VERSION ""

NS_ :

BS_:

BU_: WPC2 PSB SHVU_RR vHS_B2 FCS EMCU SLB GW_APSU GW_DLBCU ARS RCM CGW_CCU vDummy_HS_B GW_RLPSU ATS RLHV SGU PFSU GW_RRPSU ALBCU DSAU SWRC SHVU_FR RCS GW_DPSU BLTN_CAM SCM OHCL RWPC RRHV WPC HOD ASAU

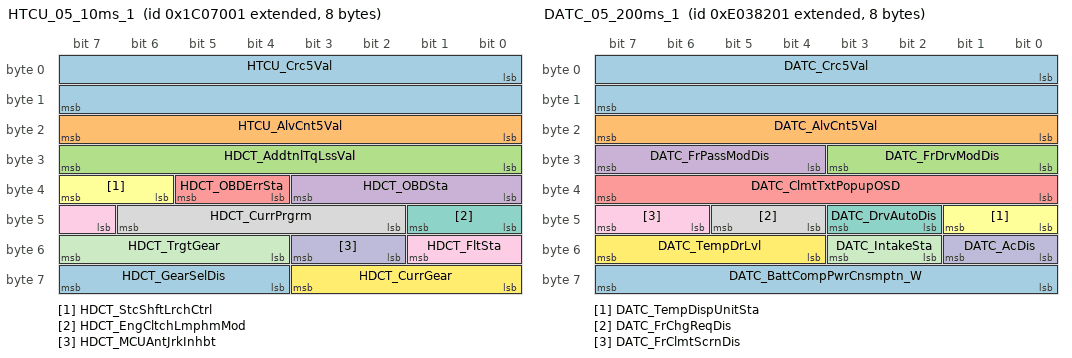
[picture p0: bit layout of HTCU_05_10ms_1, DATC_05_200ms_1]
BO_ 2176872449 HTCU_05_10ms_1: 8 CGW_CCU
 SG_ HTCU_Crc5Val : 0|16@1+ (1,0) [0|0] ""  Vector__XXX
 SG_ HTCU_AlvCnt5Val : 16|8@1+ (1,0) [0|0] ""  Vector__XXX
 SG_ HDCT_AddtnlTqLssVal : 24|8@1+ (0.390625,0) [0|0] "%"  Vector__XXX
 SG_ HDCT_OBDSta : 32|4@1+ (1,0) [0|0] ""  Vector__XXX
 SG_ HDCT_OBDErrSta : 36|2@1+ (1,0) [0|0] ""  Vector__XXX
 SG_ HDCT_StcShftLrchCtrl : 38|2@1+ (1,0) [0|0] ""  Vector__XXX
 SG_ HDCT_EngCltchLmphmMod : 40|2@1+ (1,0) [0|0] ""  Vector__XXX
 SG_ HDCT_CurrPrgrm : 42|5@1+ (1,0) [0|0] ""  Vector__XXX
 SG_ HDCT_FltSta : 47|3@1+ (1,0) [0|0] ""  Vector__XXX
 SG_ HDCT_MCUAntJrkInhbt : 50|2@1+ (1,0) [0|0] ""  Vector__XXX
 SG_ HDCT_TrgtGear : 52|4@1+ (1,0) [0|0] ""  Vector__XXX
 SG_ HDCT_CurrGear : 56|4@1+ (1,0) [0|0] ""  Vector__XXX
 SG_ HDCT_GearSelDis : 60|4@1+ (1,0) [0|0] ""  SWRC,BLTN_CAM

BO_ 2176872452 HTCU_05_10ms_4: 8 CGW_CCU

BO_ 694 ASAU_02_00ms: 8 ASAU
 SG_ ASAU_NotFootMsgOperStaWarn : 0|2@1+ (1,0) [0|0] ""  Vector__XXX

BO_ 2382594561 DATC_05_200ms_1: 8 CGW_CCU
 SG_ DATC_Crc5Val : 0|16@1+ (1,0) [0|0] ""  Vector__XXX
 SG_ DATC_AlvCnt5Val : 16|8@1+ (1,0) [0|0] ""  Vector__XXX
 SG_ DATC_FrDrvModDis : 24|4@1+ (1,0) [0|0] ""  ATS
 SG_ DATC_FrPassModDis : 28|4@1+ (1,0) [0|0] ""  ATS
 SG_ DATC_ClmtTxtPopupOSD : 32|8@1+ (1,0) [0|0] ""  ATS
 SG_ DATC_TempDispUnitSta : 40|2@1+ (1,0) [0|0] ""  ATS
 SG_ DATC_DrvAutoDis : 42|2@1+ (1,0) [0|0] ""  ATS
 SG_ DATC_FrChgReqDis : 44|2@1+ (1,0) [0|0] ""  Vector__XXX
 SG_ DATC_FrClmtScrnDis : 46|2@1+ (1,0) [0|0] ""  ATS
 SG_ DATC_AcDis : 48|2@1+ (1,0) [0|0] ""  ATS
 SG_ DATC_IntakeSta : 50|2@1+ (1,0) [0|0] ""  Vector__XXX
 SG_ DATC_TempDrLvl : 52|4@1+ (1,0) [0|0] ""  Vector__XXX
 SG_ DATC_BattCompPwrCnsmptn_W : 56|8@1+ (40,0) [0|0] "W"  Vector__XXX

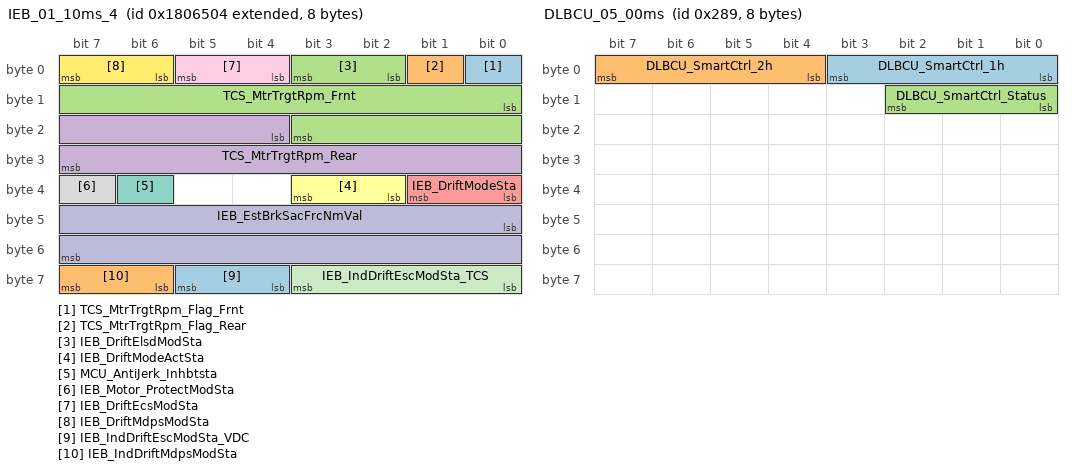
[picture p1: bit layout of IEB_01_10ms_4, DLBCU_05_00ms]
BO_ 2172675332 IEB_01_10ms_4: 8 CGW_CCU
 SG_ TCS_MtrTrgtRpm_Flag_Frnt : 0|1@1+ (1,0) [0|0] ""  Vector__XXX
 SG_ TCS_MtrTrgtRpm_Flag_Rear : 1|1@1+ (1,0) [0|0] ""  Vector__XXX
 SG_ IEB_DriftElsdModSta : 2|2@1+ (1,0) [0|0] ""  Vector__XXX
 SG_ TCS_MtrTrgtRpm_Rear : 20|12@1+ (8,0) [0|0] "rpm"  Vector__XXX
 SG_ IEB_DriftModeSta : 32|2@1+ (1,0) [0|0] ""  Vector__XXX
 SG_ IEB_DriftModeActSta : 34|2@1+ (1,0) [0|0] ""  Vector__XXX
 SG_ MCU_AntiJerk_Inhbtsta : 38|1@1+ (1,0) [0|0] ""  Vector__XXX
 SG_ IEB_Motor_ProtectModSta : 39|1@1+ (1,0) [0|0] ""  Vector__XXX
 SG_ IEB_DriftEcsModSta : 4|2@1+ (1,0) [0|0] ""  Vector__XXX
 SG_ IEB_EstBrkSacFrcNmVal : 40|16@1+ (1,0) [0|0] ""  Vector__XXX
 SG_ IEB_IndDriftEscModSta_TCS : 56|4@1+ (1,0) [0|0] ""  Vector__XXX
 SG_ IEB_DriftMdpsModSta : 6|2@1+ (1,0) [0|0] ""  Vector__XXX
 SG_ IEB_IndDriftEscModSta_VDC : 60|2@1+ (1,0) [0|0] ""  Vector__XXX
 SG_ IEB_IndDriftMdpsModSta : 62|2@1+ (1,0) [0|0] ""  Vector__XXX
 SG_ TCS_MtrTrgtRpm_Frnt : 8|12@1+ (8,0) [0|0] "rpm"  Vector__XXX

BO_ 649 DLBCU_05_00ms: 8 GW_DLBCU
 SG_ DLBCU_SmartCtrl_1h : 0|4@1+ (1,0) [0|0] ""  CGW_CCU
 SG_ DLBCU_SmartCtrl_2h : 4|4@1+ (1,0) [0|0] ""  CGW_CCU
 SG_ DLBCU_SmartCtrl_Status : 8|3@1+ (1,0) [0|0] ""  CGW_CCU

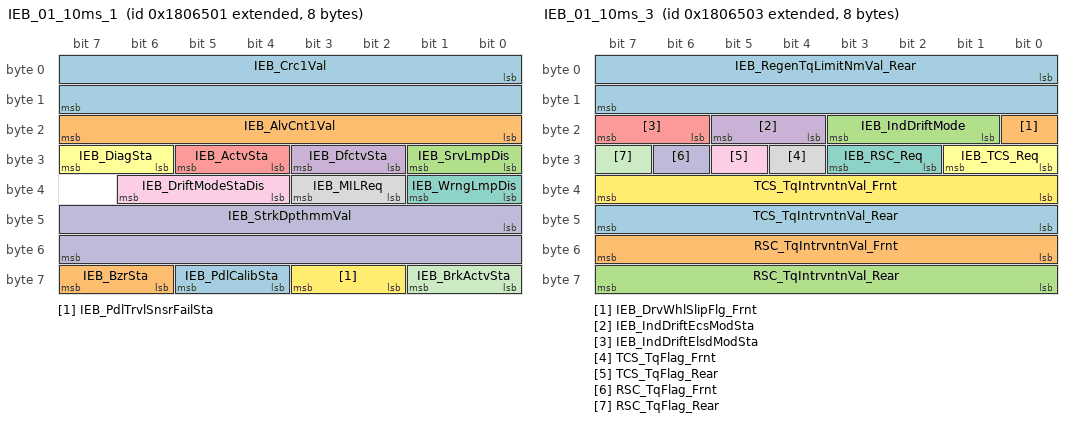
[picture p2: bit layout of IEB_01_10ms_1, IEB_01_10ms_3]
BO_ 2172675329 IEB_01_10ms_1: 8 CGW_CCU
 SG_ IEB_Crc1Val : 0|16@1+ (1,0) [0|0] ""  Vector__XXX
 SG_ IEB_AlvCnt1Val : 16|8@1+ (1,0) [0|0] ""  Vector__XXX
 SG_ IEB_SrvLmpDis : 24|2@1+ (1,0) [0|0] ""  Vector__XXX
 SG_ IEB_DfctvSta : 26|2@1+ (1,0) [0|0] ""  Vector__XXX
 SG_ IEB_ActvSta : 28|2@1+ (1,0) [0|0] ""  Vector__XXX
 SG_ IEB_DiagSta : 30|2@1+ (1,0) [0|0] ""  Vector__XXX
 SG_ IEB_WrngLmpDis : 32|2@1+ (1,0) [0|0] ""  Vector__XXX
 SG_ IEB_MILReq : 34|2@1+ (1,0) [0|0] ""  Vector__XXX
 SG_ IEB_DriftModeStaDis : 36|3@1+ (1,0) [0|0] ""  Vector__XXX
 SG_ IEB_StrkDpthmmVal : 40|16@1- (0.1,0) [0|0] "mm"  Vector__XXX
 SG_ IEB_BrkActvSta : 56|2@1+ (1,0) [0|0] ""  BLTN_CAM
 SG_ IEB_PdlTrvlSnsrFailSta : 58|2@1+ (1,0) [0|0] ""  Vector__XXX
 SG_ IEB_PdlCalibSta : 60|2@1+ (1,0) [0|0] ""  Vector__XXX
 SG_ IEB_BzrSta : 62|2@1+ (1,0) [0|0] ""  Vector__XXX

BO_ 2172675331 IEB_01_10ms_3: 8 CGW_CCU
 SG_ IEB_RegenTqLimitNmVal_Rear : 0|16@1+ (1,0) [0|0] "Nm"  Vector__XXX
 SG_ IEB_DrvWhlSlipFlg_Frnt : 16|1@1+ (1,0) [0|0] ""  Vector__XXX
 SG_ IEB_IndDriftMode : 17|3@1+ (1,0) [0|0] ""  Vector__XXX
 SG_ IEB_IndDriftEcsModSta : 20|2@1+ (1,0) [0|0] ""  Vector__XXX
 SG_ IEB_IndDriftElsdModSta : 22|2@1+ (1,0) [0|0] ""  Vector__XXX
 SG_ IEB_TCS_Req : 24|2@1+ (1,0) [0|0] ""  Vector__XXX
 SG_ IEB_RSC_Req : 26|2@1+ (1,0) [0|0] ""  Vector__XXX
 SG_ TCS_TqFlag_Frnt : 28|1@1+ (1,0) [0|0] ""  Vector__XXX
 SG_ TCS_TqFlag_Rear : 29|1@1+ (1,0) [0|0] ""  Vector__XXX
 SG_ RSC_TqFlag_Frnt : 30|1@1+ (1,0) [0|0] ""  Vector__XXX
 SG_ RSC_TqFlag_Rear : 31|1@1+ (1,0) [0|0] ""  Vector__XXX
 SG_ TCS_TqIntrvntnVal_Frnt : 32|8@1+ (0.390625,0) [0|0] "%"  Vector__XXX
 SG_ TCS_TqIntrvntnVal_Rear : 40|8@1+ (0.390625,0) [0|0] "%"  Vector__XXX
 SG_ RSC_TqIntrvntnVal_Frnt : 48|8@1+ (0.390625,0) [0|0] "%"  Vector__XXX
 SG_ RSC_TqIntrvntnVal_Rear : 56|8@1+ (0.390625,0) [0|0] "%"  Vector__XXX

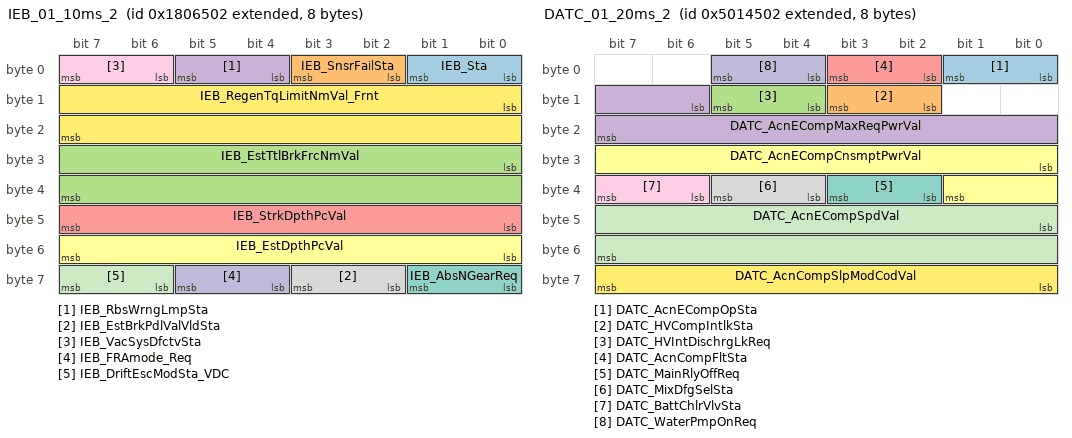
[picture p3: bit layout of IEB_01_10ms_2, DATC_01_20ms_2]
BO_ 2172675330 IEB_01_10ms_2: 8 CGW_CCU
 SG_ IEB_Sta : 0|2@1+ (1,0) [0|0] ""  Vector__XXX
 SG_ IEB_SnsrFailSta : 2|2@1+ (1,0) [0|0] ""  Vector__XXX
 SG_ IEB_EstTtlBrkFrcNmVal : 24|16@1+ (1,0) [0|0] "Nm"  Vector__XXX
 SG_ IEB_RbsWrngLmpSta : 4|2@1+ (1,0) [0|0] ""  Vector__XXX
 SG_ IEB_StrkDpthPcVal : 40|8@1+ (0.39215,0) [0|0] "%"  Vector__XXX
 SG_ IEB_EstDpthPcVal : 48|8@1+ (0.390625,0) [0|0] "%"  Vector__XXX
 SG_ IEB_AbsNGearReq : 56|2@1+ (1,0) [0|0] ""  Vector__XXX
 SG_ IEB_EstBrkPdlValVldSta : 58|2@1+ (1,0) [0|0] ""  Vector__XXX
 SG_ IEB_VacSysDfctvSta : 6|2@1+ (1,0) [0|0] ""  Vector__XXX
 SG_ IEB_FRAmode_Req : 60|2@1+ (1,0) [0|0] ""  Vector__XXX
 SG_ IEB_DriftEscModSta_VDC : 62|2@1+ (1,0) [0|0] ""  Vector__XXX
 SG_ IEB_RegenTqLimitNmVal_Frnt : 8|16@1+ (1,0) [0|0] "Nm"  Vector__XXX

BO_ 2231452930 DATC_01_20ms_2: 8 CGW_CCU
 SG_ DATC_AcnECompOpSta : 0|2@1+ (1,0) [0|0] "flag"  Vector__XXX
 SG_ DATC_HVCompIntlkSta : 10|2@1+ (1,0) [0|0] "flag"  Vector__XXX
 SG_ DATC_HVIntDischrgLkReq : 12|2@1+ (1,0) [0|0] "flag"  Vector__XXX
 SG_ DATC_AcnECompMaxReqPwrVal : 14|10@1+ (20,0) [0|0] "W"  Vector__XXX
 SG_ DATC_AcnCompFltSta : 2|2@1+ (1,0) [0|0] "flag"  Vector__XXX
 SG_ DATC_AcnECompCnsmptPwrVal : 24|10@1+ (20,0) [0|0] "W"  Vector__XXX
 SG_ DATC_MainRlyOffReq : 34|2@1+ (1,0) [0|0] "flag"  Vector__XXX
 SG_ DATC_MixDfgSelSta : 36|2@1+ (1,0) [0|0] "flag"  Vector__XXX
 SG_ DATC_BattChlrVlvSta : 38|2@1+ (1,0) [0|0] ""  Vector__XXX
 SG_ DATC_WaterPmpOnReq : 4|2@1+ (1,0) [0|0] "flag"  Vector__XXX
 SG_ DATC_AcnECompSpdVal : 40|16@1+ (1,0) [0|0] "rpm"  Vector__XXX
 SG_ DATC_AcnCompSlpModCodVal : 56|8@1+ (1,0) [0|0] ""  Vector__XXX

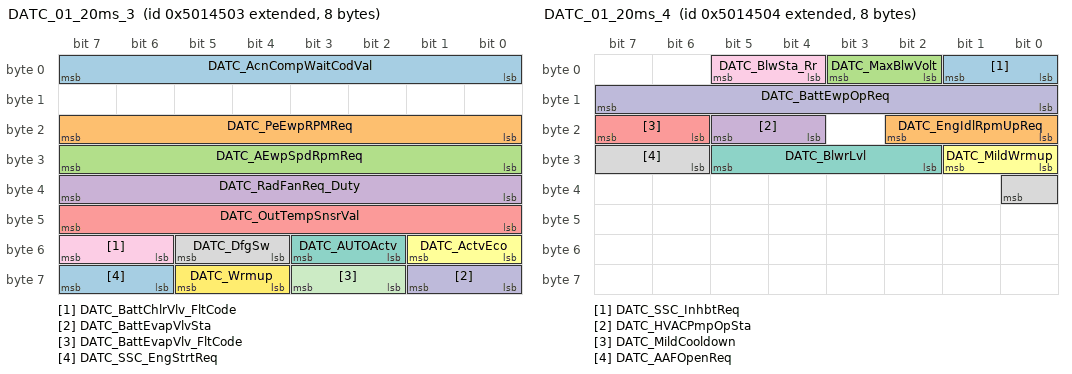
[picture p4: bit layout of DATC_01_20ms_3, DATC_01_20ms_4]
BO_ 2231452931 DATC_01_20ms_3: 8 CGW_CCU
 SG_ DATC_AcnCompWaitCodVal : 0|8@1+ (1,0) [0|0] ""  Vector__XXX
 SG_ DATC_PeEwpRPMReq : 16|8@1+ (30,0) [0|0] ""  Vector__XXX
 SG_ DATC_AEwpSpdRpmReq : 24|8@1+ (20,0) [0|0] "rpm"  Vector__XXX
 SG_ DATC_RadFanReq_Duty : 32|8@1+ (1,0) [0|0] "%"  Vector__XXX
 SG_ DATC_OutTempSnsrVal : 40|8@1+ (0.5,-40) [0|0] "¡É"  RCM
 SG_ DATC_ActvEco : 48|2@1+ (1,0) [0|0] ""  Vector__XXX
 SG_ DATC_AUTOActv : 50|2@1+ (1,0) [0|0] ""  Vector__XXX
 SG_ DATC_DfgSw : 52|2@1+ (1,0) [0|0] ""  Vector__XXX
 SG_ DATC_BattChlrVlv_FltCode : 54|2@1+ (1,0) [0|0] ""  Vector__XXX
 SG_ DATC_BattEvapVlvSta : 56|2@1+ (1,0) [0|0] ""  Vector__XXX
 SG_ DATC_BattEvapVlv_FltCode : 58|2@1+ (1,0) [0|0] ""  Vector__XXX
 SG_ DATC_Wrmup : 60|2@1+ (1,0) [0|0] ""  Vector__XXX
 SG_ DATC_SSC_EngStrtReq : 62|2@1+ (1,0) [0|0] ""  Vector__XXX

BO_ 2231452929 DATC_01_20ms_1: 8 CGW_CCU
 SG_ DATC_Crc1Val : 0|16@1+ (1,0) [0|0] ""  Vector__XXX
 SG_ DATC_AlvCnt1Val : 16|8@1+ (1,0) [0|0] ""  Vector__XXX
 SG_ DATC_PtcRlySta : 24|3@1+ (1,0) [0|0] ""  Vector__XXX
 SG_ DATC_ManufacturerTyp : 27|3@1+ (1,0) [0|0] ""  Vector__XXX
 SG_ DATC_DatcPwmSts : 30|2@1+ (1,0) [0|0] ""  Vector__XXX
 SG_ DATC_AcnCompTyp : 32|3@1+ (1,0) [0|0] "flag"  Vector__XXX
 SG_ DATC_EewpRpmLvlReq : 35|3@1+ (1,0) [0|0] ""  Vector__XXX
 SG_ DATC_Cooldown : 38|2@1+ (1,0) [0|0] ""  Vector__XXX
 SG_ DATC_AcnReq : 40|2@1+ (1,0) [0|0] ""  Vector__XXX
 SG_ DATC_BlwSta : 42|2@1+ (1,0) [0|0] ""  Vector__XXX
 SG_ DATC_BlwMaxSta : 44|2@1+ (1,0) [0|0] ""  Vector__XXX
 SG_ DATC_EngStrtReq : 46|2@1+ (1,0) [0|0] ""  Vector__XXX
 SG_ DATC_IsgInhbtReq : 48|2@1+ (1,0) [0|0] ""  Vector__XXX
 SG_ DATC_AcnCompOnReq : 50|2@1+ (1,0) [0|0] "flag"  Vector__XXX
 SG_ DATC_SrvLmpReq : 52|2@1+ (1,0) [0|0] ""  Vector__XXX
 SG_ DATC_EcvFltSta : 54|2@1+ (1,0) [0|0] ""  Vector__XXX
 SG_ DATC_CalcAcnCompTqVal : 56|8@1+ (0.2,0) [0|0] "Nm"  Vector__XXX

BO_ 2231452932 DATC_01_20ms_4: 8 CGW_CCU
 SG_ DATC_SSC_InhbtReq : 0|2@1+ (1,0) [0|0] ""  Vector__XXX
 SG_ DATC_EngIdlRpmUpReq : 16|3@1+ (1,0) [0|0] ""  Vector__XXX
 SG_ DATC_MaxBlwVolt : 2|2@1+ (1,0) [0|0] ""  Vector__XXX
 SG_ DATC_HVACPmpOpSta : 20|2@1+ (1,0) [0|0] ""  Vector__XXX
 SG_ DATC_MildCooldown : 22|2@1+ (1,0) [0|0] ""  Vector__XXX
 SG_ DATC_MildWrmup : 24|2@1+ (1,0) [0|0] ""  Vector__XXX
 SG_ DATC_BlwrLvl : 26|4@1+ (1,0) [0|0] ""  Vector__XXX
 SG_ DATC_AAFOpenReq : 30|3@1+ (1,0) [0|0] ""  Vector__XXX
 SG_ DATC_BlwSta_Rr : 4|2@1+ (1,0) [0|0] ""  Vector__XXX
 SG_ DATC_BattEwpOpReq : 8|8@1+ (30,0) [0|0] "rpm"  Vector__XXX

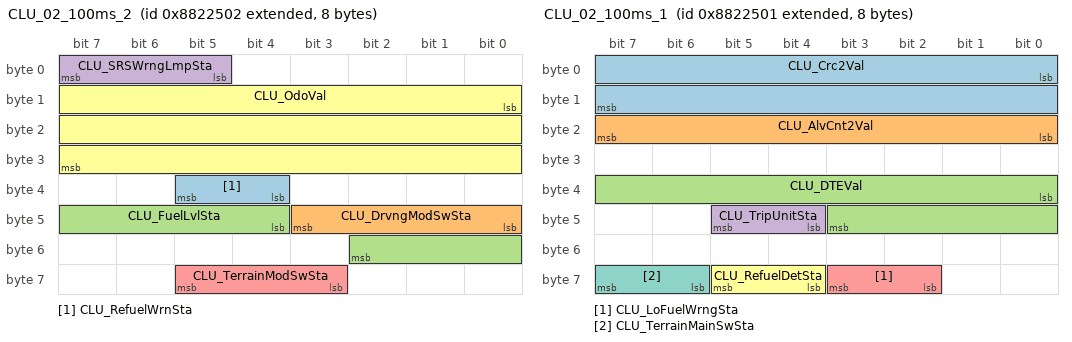
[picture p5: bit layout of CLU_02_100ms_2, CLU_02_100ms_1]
BO_ 2290230530 CLU_02_100ms_2: 8 CGW_CCU
 SG_ CLU_RefuelWrnSta : 36|2@1+ (1,0) [0|0] ""  Vector__XXX
 SG_ CLU_DrvngModSwSta : 40|4@1+ (1,0) [0|0] ""  ALBCU,GW_DLBCU,SWRC
 SG_ CLU_FuelLvlSta : 44|7@1+ (1,0) [0|0] "%"  Vector__XXX
 SG_ CLU_SRSWrngLmpSta : 5|3@1+ (1,0) [0|0] ""  Vector__XXX
 SG_ CLU_TerrainModSwSta : 59|3@1+ (1,0) [0|0] ""  SWRC
 SG_ CLU_OdoVal : 8|24@1+ (0.1,0) [0|0] "km"  Vector__XXX

BO_ 2290230529 CLU_02_100ms_1: 8 CGW_CCU
 SG_ CLU_Crc2Val : 0|16@1+ (1,0) [0|0] ""  Vector__XXX
 SG_ CLU_AlvCnt2Val : 16|8@1+ (1,0) [0|0] ""  Vector__XXX
 SG_ CLU_DTEVal : 32|12@1+ (1,0) [0|0] ""  Vector__XXX
 SG_ CLU_TripUnitSta : 44|2@1+ (1,0) [0|0] ""  Vector__XXX
 SG_ CLU_LoFuelWrngSta : 58|2@1+ (1,0) [0|0] ""  Vector__XXX
 SG_ CLU_RefuelDetSta : 60|2@1+ (1,0) [0|0] ""  Vector__XXX
 SG_ CLU_TerrainMainSwSta : 62|2@1+ (1,0) [0|0] ""  FCS

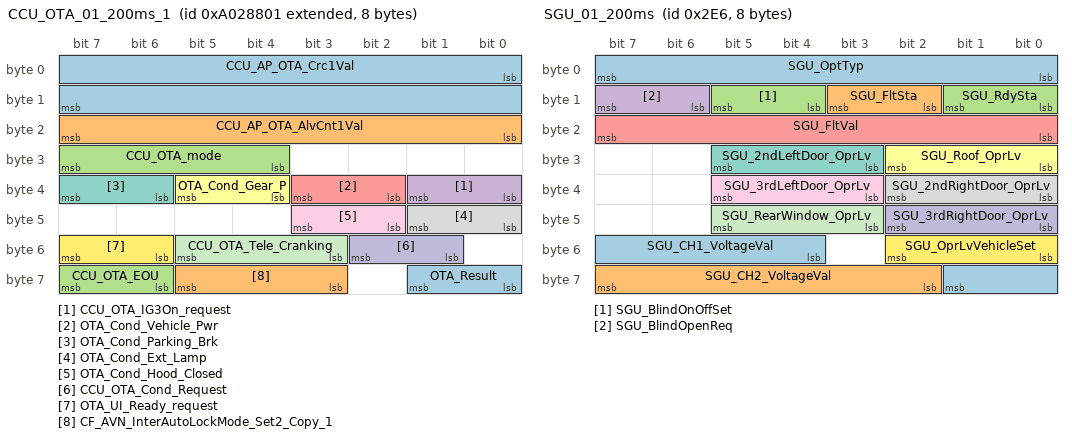
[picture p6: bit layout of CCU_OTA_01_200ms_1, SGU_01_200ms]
BO_ 2315421697 CCU_OTA_01_200ms_1: 8 CGW_CCU
 SG_ CCU_AP_OTA_Crc1Val : 0|16@1+ (1,0) [0|0] ""  vDummy_HS_B
 SG_ CCU_AP_OTA_AlvCnt1Val : 16|8@1+ (1,0) [0|0] ""  vDummy_HS_B
 SG_ CCU_OTA_mode : 28|4@1+ (1,0) [0|0] ""  Vector__XXX
 SG_ CCU_OTA_IG3On_request : 32|2@1+ (1,0) [0|0] ""  Vector__XXX
 SG_ OTA_Cond_Vehicle_Pwr : 34|2@1+ (1,0) [0|0] "flag"  Vector__XXX
 SG_ OTA_Cond_Gear_P : 36|2@1+ (1,0) [0|0] "flag"  Vector__XXX
 SG_ OTA_Cond_Parking_Brk : 38|2@1+ (1,0) [0|0] "flag"  Vector__XXX
 SG_ OTA_Cond_Ext_Lamp : 40|2@1+ (1,0) [0|0] "flag"  Vector__XXX
 SG_ OTA_Cond_Hood_Closed : 42|2@1+ (1,0) [0|0] "flag"  Vector__XXX
 SG_ CCU_OTA_Cond_Request : 49|2@1+ (1,0) [0|0] ""  Vector__XXX
 SG_ CCU_OTA_Tele_Cranking : 51|3@1+ (1,0) [0|0] ""  Vector__XXX
 SG_ OTA_UI_Ready_request : 54|2@1+ (1,0) [0|0] ""  Vector__XXX
 SG_ OTA_Result : 56|2@1+ (1,0) [0|0] "flag"  Vector__XXX
 SG_ CF_AVN_InterAutoLockMode_Set2_Copy_1 : 59|3@1+ (1,0) [0|0] ""  Vector__XXX
 SG_ CCU_OTA_EOU : 62|2@1+ (1,0) [0|0] ""  Vector__XXX

BO_ 2470763009 CLU_09_00ms_1: 8 CGW_CCU
 SG_ CLU_Crc9Val : 0|16@1+ (1,0) [0|0] ""  Vector__XXX
 SG_ CLU_AlvCnt9Val : 16|8@1+ (1,0) [0|0] ""  Vector__XXX
 SG_ USM_MdLmpClrSetReq : 24|4@1+ (1,0) [0|0] ""  Vector__XXX
 SG_ USM_RrWiperRevSetReq : 28|2@1+ (1,0) [0|0] ""  Vector__XXX
 SG_ USM_RrStRemindSetReq : 30|2@1+ (1,0) [0|0] ""  Vector__XXX
 SG_ USM_RrWpcSetReq : 32|2@1+ (1,0) [0|0] ""  Vector__XXX
 SG_ USM_WpcSetReq : 34|2@1+ (1,0) [0|0] ""  WPC,WPC2
 SG_ USM_SeqLmpSetReq : 36|2@1+ (1,0) [0|0] ""  Vector__XXX
 SG_ USM_UnlckWlcmSetReq : 38|2@1+ (1,0) [0|0] ""  Vector__XXX
 SG_ USM_SmrtWlcmSetReq : 40|2@1+ (1,0) [0|0] ""  Vector__XXX
 SG_ USM_UipSetReq : 42|2@1+ (1,0) [0|0] ""  Vector__XXX
 SG_ USM_DigitalKeyEnblSetReq : 44|2@1+ (1,0) [0|0] ""  Vector__XXX
 SG_ USM_OwnerPhnRegSetReq : 46|2@1+ (1,0) [0|0] ""  Vector__XXX
 SG_ USM_NFCCard1RegSetReq : 48|2@1+ (1,0) [0|0] ""  Vector__XXX
 SG_ USM_NFCCard2RegSetReq : 50|2@1+ (1,0) [0|0] ""  Vector__XXX
 SG_ USM_ProcStpReq : 52|1@1+ (1,0) [0|0] ""  Vector__XXX
 SG_ USM_PwrAutoOffTimeSetReq : 54|3@1+ (1,0) [0|0] ""  Vector__XXX
 SG_ USM_RrStRemindSetReq_RestMode : 57|3@1+ (1,0) [0|0] ""  Vector__XXX
 SG_ USM_1stRrStRemindSetReq : 60|2@1+ (1,0) [0|0] ""  Vector__XXX
 SG_ USM_Wpc2SetReq : 62|2@1+ (1,0) [0|0] ""  WPC2

BO_ 742 SGU_01_200ms: 8 SGU
 SG_ SGU_OptTyp : 0|8@1+ (1,0) [0|0] ""  Vector__XXX
 SG_ SGU_FltSta : 10|2@1+ (1,0) [0|0] ""  Vector__XXX
 SG_ SGU_BlindOnOffSet : 12|2@1+ (1,0) [0|0] ""  CGW_CCU
 SG_ SGU_BlindOpenReq : 14|2@1+ (1,0) [0|0] ""  RCM
 SG_ SGU_FltVal : 16|8@1+ (1,0) [0|0] ""  Vector__XXX
 SG_ SGU_Roof_OprLv : 24|3@1+ (1,0) [0|0] ""  CGW_CCU
 SG_ SGU_2ndLeftDoor_OprLv : 27|3@1+ (1,0) [0|0] ""  CGW_CCU
 SG_ SGU_2ndRightDoor_OprLv : 32|3@1+ (1,0) [0|0] ""  CGW_CCU
 SG_ SGU_3rdLeftDoor_OprLv : 35|3@1+ (1,0) [0|0] ""  CGW_CCU
 SG_ SGU_3rdRightDoor_OprLv : 40|3@1+ (1,0) [0|0] ""  CGW_CCU
 SG_ SGU_RearWindow_OprLv : 43|3@1+ (1,0) [0|0] ""  CGW_CCU
 SG_ SGU_OprLvVehicleSet : 48|3@1+ (1,0) [0|0] ""  CGW_CCU
 SG_ SGU_CH1_VoltageVal : 52|6@1+ (0.1,0) [0|0] "V"  Vector__XXX
 SG_ SGU_CH2_VoltageVal : 58|6@1+ (0.1,0) [0|0] "V"  Vector__XXX
 SG_ SGU_RdySta : 8|2@1+ (1,0) [0|0] ""  Vector__XXX

BO_ 763 SBCM_DRV_03_200ms: 8 CGW_CCU
 SG_ SBCM_DRV_Crc3Val : 0|8@1+ (1,0) [0|0] ""  Vector__XXX
 SG_ CDM_TypeOption : 10|2@1+ (1,0) [0|0] ""  Vector__XXX
 SG_ SBCM_DRV_AlvCnt3Val : 12|4@1+ (1,0) [0|0] ""  Vector__XXX
 SG_ CDM_ImmeChgSw_SBCM : 16|2@1+ (1,0) [0|0] ""  Vector__XXX
 SG_ CDM_ChgDrSwFrt_SBCM : 18|2@1+ (1,0) [0|0] ""  Vector__XXX
 SG_ CDM_OpnClsState_SBCM : 20|2@1+ (1,0) [0|0] ""  Vector__XXX
 SG_ CDM_WarnMsg_SBCM : 22|2@1+ (1,0) [0|0] ""  Vector__XXX
 SG_ CDM_AutoWashModeSta : 24|3@1+ (1,0) [0|0] ""  Vector__XXX
 SG_ CDM_CmdStatus_SBCM : 28|4@1+ (1,0) [0|0] ""  Vector__XXX
 SG_ CDM_OutsideOpnSwSta : 32|2@1+ (1,0) [0|0] ""  Vector__XXX
 SG_ PwrDRBuzzerOut_DRV : 34|2@1+ (1,0) [0|0] ""  Vector__XXX
 SG_ Warn_HoodSwSta_SBCM : 36|2@1+ (1,0) [0|0] ""  BLTN_CAM
 SG_ Hood_TypeOption : 38|2@1+ (1,0) [0|0] ""  BLTN_CAM
 SG_ SBCM_FrunkSta : 40|2@1+ (1,0) [0|0] ""  Vector__XXX
 SG_ Warn_HoodSwFullSta_SBCM : 42|2@1+ (1,0) [0|0] ""  Vector__XXX
 SG_ FrunkWarning_SBCM : 44|2@1+ (1,0) [0|0] ""  Vector__XXX
 SG_ SBCM_Longkey_DRVDrAtClsSwSta : 46|2@1+ (1,0) [0|0] ""  Vector__XXX
 SG_ PwrDRClosingDRVDrSta : 48|3@1+ (1,0) [0|0] ""  Vector__XXX
 SG_ Drv_DrLkRetryFail_SBCM : 51|2@1+ (1,0) [0|0] ""  Vector__XXX
 SG_ CDM_GbtImmeChgSw_SBCM : 54|2@1+ (1,0) [0|0] ""  Vector__XXX
 SG_ CDM_GbtOpnClsState_SBCM : 56|2@1+ (1,0) [0|0] ""  Vector__XXX
 SG_ CDM_GbtWarnMsg_SBCM : 58|2@1+ (1,0) [0|0] ""  Vector__XXX
 SG_ DoorLock_DrvLkOutSta_SBCM : 62|2@1+ (1,0) [0|0] ""  Vector__XXX
 SG_ CDM_InsideOpnSwSta : 8|2@1+ (1,0) [0|0] ""  Vector__XXX

BO_ 761 SBCM_AST_03_200ms: 8 CGW_CCU
 SG_ SBCM_AST_Crc3Val : 0|8@1+ (1,0) [0|0] ""  Vector__XXX
 SG_ CDM_TypeOption_AST : 10|2@1+ (1,0) [0|0] ""  Vector__XXX
 SG_ SBCM_AST_AlvCnt3Val : 12|4@1+ (1,0) [0|0] ""  Vector__XXX
 SG_ CDM_ImmeChgSw_AST : 16|2@1+ (1,0) [0|0] ""  Vector__XXX
 SG_ CDM_ChgDrSwFrt_AST : 18|2@1+ (1,0) [0|0] ""  Vector__XXX
 SG_ CDM_OpnClsState_AST : 20|2@1+ (1,0) [0|0] ""  Vector__XXX
 SG_ CDM_WarnMsg_AST : 22|2@1+ (1,0) [0|0] ""  Vector__XXX
 SG_ Mirror_RH_FoldingSta : 24|2@1+ (1,0) [0|0] ""  Vector__XXX
 SG_ Mirror_RH_UnfoldingSta : 26|2@1+ (1,0) [0|0] ""  Vector__XXX
 SG_ CDM_CmdStatus_AST : 28|4@1+ (1,0) [0|0] ""  Vector__XXX
 SG_ AST_CrashMRActAlarm : 32|2@1+ (1,0) [0|0] ""  Vector__XXX
 SG_ PwrDRBuzzerOut_AST : 34|2@1+ (1,0) [0|0] ""  Vector__XXX
 SG_ IMS_OSMirPlayBackSta_RH : 36|4@1+ (1,0) [0|0] ""  GW_DPSU
 SG_ PwrDRClosingASTDrSta : 40|3@1+ (1,0) [0|0] ""  Vector__XXX
 SG_ CDM_OutsideOpnSwSta_AST : 44|2@1+ (1,0) [0|0] ""  Vector__XXX
 SG_ SBCM_Longkey_ASTDrAtClsSwSta : 46|2@1+ (1,0) [0|0] ""  Vector__XXX
 SG_ Hood_TypeOption_AST : 48|2@1+ (1,0) [0|0] ""  Vector__XXX
 SG_ Warn_HoodSwSta_AST : 50|2@1+ (1,0) [0|0] ""  Vector__XXX
 SG_ FrunkWarning_AST : 52|2@1+ (1,0) [0|0] ""  Vector__XXX
 SG_ SBCM_FrunkSta_AST : 54|2@1+ (1,0) [0|0] ""  Vector__XXX
 SG_ Ast_DrLkRetryFail_SBCM : 60|2@1+ (1,0) [0|0] ""  Vector__XXX
 SG_ DoorLock_AstLkOutSta_SBCM : 62|2@1+ (1,0) [0|0] ""  Vector__XXX
 SG_ SBCM_AST_DiagSta : 8|2@1+ (1,0) [0|0] ""  Vector__XXX

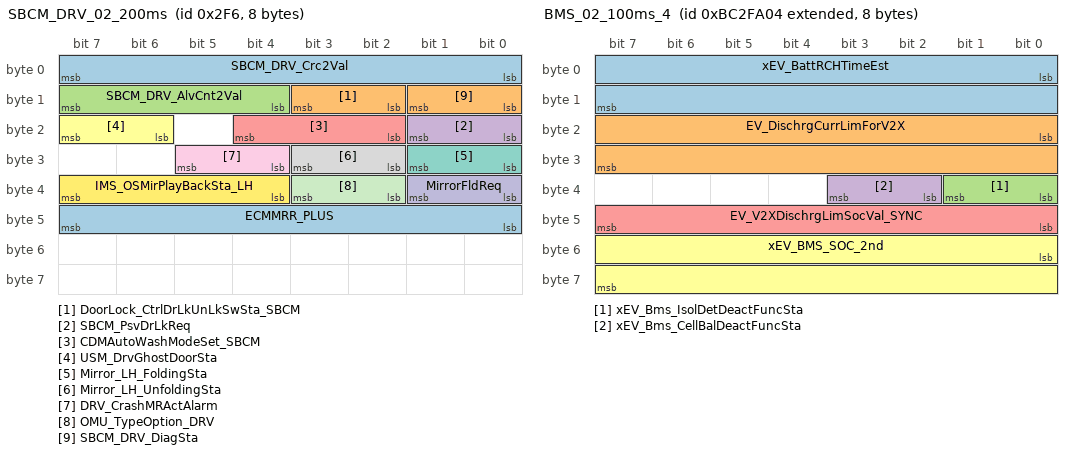
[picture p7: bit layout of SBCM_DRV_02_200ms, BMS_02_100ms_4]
BO_ 758 SBCM_DRV_02_200ms: 8 CGW_CCU
 SG_ SBCM_DRV_Crc2Val : 0|8@1+ (1,0) [0|0] ""  Vector__XXX
 SG_ DoorLock_CtrlDrLkUnLkSwSta_SBCM : 10|2@1+ (1,0) [0|0] ""  Vector__XXX
 SG_ SBCM_DRV_AlvCnt2Val : 12|4@1+ (1,0) [0|0] ""  Vector__XXX
 SG_ SBCM_PsvDrLkReq : 16|2@1+ (1,0) [0|0] ""  Vector__XXX
 SG_ CDMAutoWashModeSet_SBCM : 18|3@1+ (1,0) [0|0] ""  Vector__XXX
 SG_ USM_DrvGhostDoorSta : 22|2@1+ (1,0) [0|0] ""  Vector__XXX
 SG_ Mirror_LH_FoldingSta : 24|2@1+ (1,0) [0|0] ""  Vector__XXX
 SG_ Mirror_LH_UnfoldingSta : 26|2@1+ (1,0) [0|0] ""  Vector__XXX
 SG_ DRV_CrashMRActAlarm : 28|2@1+ (1,0) [0|0] ""  Vector__XXX
 SG_ MirrorFldReq : 32|2@1+ (1,0) [0|0] ""  Vector__XXX
 SG_ OMU_TypeOption_DRV : 34|2@1+ (1,0) [0|0] ""  Vector__XXX
 SG_ IMS_OSMirPlayBackSta_LH : 36|4@1+ (1,0) [0|0] ""  GW_DPSU
 SG_ ECMMRR_PLUS : 40|8@1+ (1,0) [0|0] ""  Vector__XXX
 SG_ SBCM_DRV_DiagSta : 8|2@1+ (1,0) [0|0] ""  Vector__XXX

BO_ 2344811012 BMS_02_100ms_4: 8 CGW_CCU
 SG_ xEV_BattRCHTimeEst : 0|16@1+ (1,0) [0|0] "Min"  Vector__XXX
 SG_ EV_DischrgCurrLimForV2X : 16|16@1+ (0.1,0) [0|0] "A"  Vector__XXX
 SG_ xEV_Bms_IsolDetDeactFuncSta : 32|2@1+ (1,0) [0|0] "flg"  Vector__XXX
 SG_ xEV_Bms_CellBalDeactFuncSta : 34|2@1+ (1,0) [0|0] "flag"  Vector__XXX
 SG_ EV_V2XDischrgLimSocVal_SYNC : 40|8@1+ (0.5,0) [0|0] "%"  Vector__XXX
 SG_ xEV_BMS_SOC_2nd : 48|16@1+ (0.05,0) [0|0] "%"  Vector__XXX

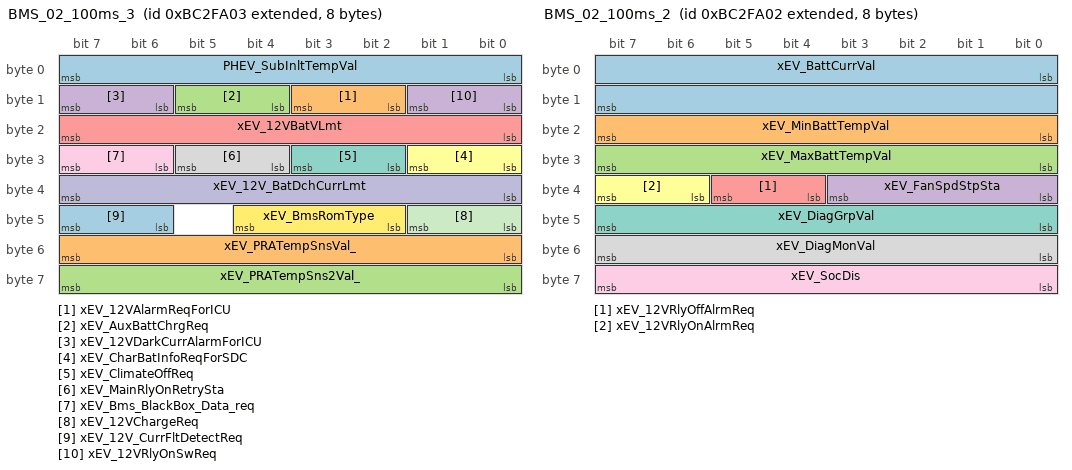
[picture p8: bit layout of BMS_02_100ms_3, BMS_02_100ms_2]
BO_ 2344811011 BMS_02_100ms_3: 8 CGW_CCU
 SG_ PHEV_SubInltTempVal : 0|8@1- (1,0) [0|0] "¡É"  Vector__XXX
 SG_ xEV_12VAlarmReqForICU : 10|2@1+ (1,0) [0|0] ""  Vector__XXX
 SG_ xEV_AuxBattChrgReq : 12|2@1+ (1,0) [0|0] ""  Vector__XXX
 SG_ xEV_12VDarkCurrAlarmForICU : 14|2@1+ (1,0) [0|0] ""  Vector__XXX
 SG_ xEV_12VBatVLmt : 16|8@1+ (0.1,0) [0|0] "V"  Vector__XXX
 SG_ xEV_CharBatInfoReqForSDC : 24|2@1+ (1,0) [0|0] ""  Vector__XXX
 SG_ xEV_ClimateOffReq : 26|2@1+ (1,0) [0|0] ""  Vector__XXX
 SG_ xEV_MainRlyOnRetrySta : 28|2@1+ (1,0) [0|0] ""  Vector__XXX
 SG_ xEV_Bms_BlackBox_Data_req : 30|2@1+ (1,0) [0|0] ""  Vector__XXX
 SG_ xEV_12V_BatDchCurrLmt : 32|8@1+ (1,0) [0|0] "A"  Vector__XXX
 SG_ xEV_12VChargeReq : 40|2@1+ (1,0) [0|0] ""  Vector__XXX
 SG_ xEV_BmsRomType : 42|3@1+ (1,0) [0|0] ""  Vector__XXX
 SG_ xEV_12V_CurrFltDetectReq : 46|2@1+ (1,0) [0|0] ""  Vector__XXX
 SG_ xEV_PRATempSnsVal_ : 48|8@1- (2,0) [0|0] "¡É"  Vector__XXX
 SG_ xEV_PRATempSns2Val_ : 56|8@1- (2,0) [0|0] "¡É"  Vector__XXX
 SG_ xEV_12VRlyOnSwReq : 8|2@1+ (1,0) [0|0] ""  Vector__XXX

BO_ 2344811010 BMS_02_100ms_2: 8 CGW_CCU
 SG_ xEV_BattCurrVal : 0|16@1- (0.1,0) [0|0] "A"  Vector__XXX
 SG_ xEV_MinBattTempVal : 16|8@1- (1,0) [0|0] "¡É"  Vector__XXX
 SG_ xEV_MaxBattTempVal : 24|8@1- (1,0) [0|0] "¡É"  Vector__XXX
 SG_ xEV_FanSpdStpSta : 32|4@1+ (1,0) [0|0] "Step"  Vector__XXX
 SG_ xEV_12VRlyOffAlrmReq : 36|2@1+ (1,0) [0|0] ""  Vector__XXX
 SG_ xEV_12VRlyOnAlrmReq : 38|2@1+ (1,0) [0|0] ""  Vector__XXX
 SG_ xEV_DiagGrpVal : 40|8@1+ (1,0) [0|0] ""  Vector__XXX
 SG_ xEV_DiagMonVal : 48|8@1+ (1,0) [0|0] ""  Vector__XXX
 SG_ xEV_SocDis : 56|8@1+ (0.5,0) [0|0] "%"  SWRC

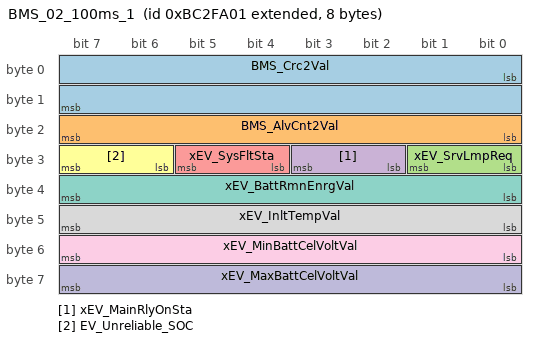
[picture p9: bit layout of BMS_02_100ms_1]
BO_ 2344811009 BMS_02_100ms_1: 8 CGW_CCU
 SG_ BMS_Crc2Val : 0|16@1+ (1,0) [0|0] ""  Vector__XXX
 SG_ BMS_AlvCnt2Val : 16|8@1+ (1,0) [0|0] ""  Vector__XXX
 SG_ xEV_SrvLmpReq : 24|2@1+ (1,0) [0|0] ""  Vector__XXX
 SG_ xEV_MainRlyOnSta : 26|2@1+ (1,0) [0|0] ""  ALBCU,GW_APSU,GW_DLBCU,GW_DPSU,GW_RLPSU,GW_RRPSU,RLHV,RRHV,SHVU_FR,SHVU_RR
 SG_ xEV_SysFltSta : 28|2@1+ (1,0) [0|0] ""  Vector__XXX
 SG_ EV_Unreliable_SOC : 30|2@1+ (1,0) [0|0] ""  Vector__XXX
 SG_ xEV_BattRmnEnrgVal : 32|8@1+ (1,0) [0|0] ""  Vector__XXX
 SG_ xEV_InltTempVal : 40|8@1- (1,0) [0|0] "¡É"  Vector__XXX
 SG_ xEV_MinBattCelVoltVal : 48|8@1+ (0.02,0) [0|0] "V"  Vector__XXX
 SG_ xEV_MaxBattCelVoltVal : 56|8@1+ (0.02,0) [0|0] "V"  Vector__XXX

CM_ BO_ 694 "[EC] On Event and On Change";
CM_ SG_ 694 ASAU_NotFootMsgOperStaWarn "Passenger Foot Massage Operation Disable Mode";
CM_ BO_ 2344811009 "[P] Periodic";
CM_ SG_ 2344811009 BMS_Crc2Val "BMS_CyclicRedundancyCheck2Value";
CM_ SG_ 2344811009 BMS_AlvCnt2Val "BMS_AliveCounter2Value";
CM_ SG_ 2344811009 xEV_SrvLmpReq "xEV_ServiceLampRequest";
CM_ SG_ 2344811009 xEV_MainRlyOnSta "xEV_MainRelayOnStatus";
CM_ SG_ 2344811009 xEV_SysFltSta "xEV_SystemFaultStatus";
CM_ SG_ 2344811009 EV_Unreliable_SOC "Unreliable SOC Alarm FLAG";
CM_ SG_ 2344811009 xEV_BattRmnEnrgVal "xEV_BatteryRemainEnergyValue";
CM_ SG_ 2344811009 xEV_InltTempVal "xEV_InletTemperatureValue";
CM_ SG_ 2344811009 xEV_MinBattCelVoltVal "xEV_MinimumBatteryCellVoltageValue";
CM_ SG_ 2344811009 xEV_MaxBattCelVoltVal "xEV_MaximumBatteryCellVoltageValue";
CM_ BO_ 2344811010 "[P] Periodic";
CM_ SG_ 2344811010 xEV_BattCurrVal "xEV_BatteryCurrentValue";
CM_ SG_ 2344811010 xEV_MinBattTempVal "xEV_MinimumBatteryTemperatureValue";
CM_ SG_ 2344811010 xEV_MaxBattTempVal "xEV_MaximumBatteryTemperatureValue";
CM_ SG_ 2344811010 xEV_FanSpdStpSta "xEV_FanSpeedStepStatus";
CM_ SG_ 2344811010 xEV_12VRlyOffAlrmReq "xEV_12VRelayOffAlarmRequest";
CM_ SG_ 2344811010 xEV_12VRlyOnAlrmReq "xEV_12VRelayOnAlarmRequest";
CM_ SG_ 2344811010 xEV_DiagGrpVal "xEV_DiagnosticGroupValue";
CM_ SG_ 2344811010 xEV_DiagMonVal "xEV_DiagnosticMonitorValue";
CM_ SG_ 2344811010 xEV_SocDis "xEV_StateOfChargeDisplay";
CM_ BO_ 2344811011 "[P] Periodic";
CM_ SG_ 2344811011 PHEV_SubInltTempVal "PHEV_SubInletTemperatureValue";
CM_ SG_ 2344811011 xEV_12VAlarmReqForICU "xEV_12VBatteryAlarmRequestForICU";
CM_ SG_ 2344811011 xEV_AuxBattChrgReq "Aux. Battery Charge Request Flag";
CM_ SG_ 2344811011 xEV_12VDarkCurrAlarmForICU "xEV_12VDarkCurrentAlarmForICU";
CM_ SG_ 2344811011 xEV_12VBatVLmt "xEV_12VBatteryVoltageLimit";
CM_ SG_ 2344811011 xEV_CharBatInfoReqForSDC "xEV_ChargeBatteryInformationRequestForSDC";
CM_ SG_ 2344811011 xEV_ClimateOffReq "xEV_ClimateOffRequest";
CM_ SG_ 2344811011 xEV_MainRlyOnRetrySta "xEV_MainRelayONRetryStatus";
CM_ SG_ 2344811011 xEV_Bms_BlackBox_Data_req "For Saving BMS data set, this signal transmits to MCU";
CM_ SG_ 2344811011 xEV_12V_BatDchCurrLmt "xEV_12VBatteryDischargeCurrentLimit";
CM_ SG_ 2344811011 xEV_12VChargeReq "xEV_12V BatteryChargeRequest";
CM_ SG_ 2344811011 xEV_12V_CurrFltDetectReq "xEV_12VBatteryCurrentSensorFaultDetectRequest";
CM_ SG_ 2344811011 xEV_PRATempSnsVal_ "PRA Temperature #1 (Relay Busbar Temperature #1)";
CM_ SG_ 2344811011 xEV_PRATempSns2Val_ "PRA Temperature #2 (Relay Busbar Temperature #2)";
CM_ SG_ 2344811011 xEV_12VRlyOnSwReq "xEV_12VRelayOnSwitchRequest";
CM_ BO_ 2344811012 "[P] Periodic";
CM_ SG_ 2344811012 xEV_BattRCHTimeEst "calculated charging power by estimated output OBC power";
CM_ SG_ 2344811012 EV_DischrgCurrLimForV2X "Discharge Current Limit(for V2X)";
CM_ SG_ 2344811012 xEV_Bms_IsolDetDeactFuncSta "xEV_Isolation Detection Circuit Deactivate Function Status (GDS Function)";
CM_ SG_ 2344811012 xEV_Bms_CellBalDeactFuncSta "xEV_Cell Balancing Deactivate Function Status (GDS Function)";
CM_ SG_ 2344811012 EV_V2XDischrgLimSocVal_SYNC "Feedback SOC of  V2X discharge limitation for sync by BMS";
CM_ SG_ 2344811012 xEV_BMS_SOC_2nd "2nd SOC for NEV (Unit 0.05%)";
CM_ BO_ 2315421697 "[PE] Periodic and On Event";
CM_ SG_ 2315421697 CCU_AP_OTA_Crc1Val "CCU_AP_OTA_CyclicRedundancyCheck1Value";
CM_ SG_ 2315421697 CCU_AP_OTA_AlvCnt1Val "CCU_AP_OTA_AliveCounter1Value";
CM_ SG_ 2315421697 CCU_OTA_mode "OTA_mode";
CM_ SG_ 2315421697 CCU_OTA_IG3On_request "IG3 Rly ON request";
CM_ SG_ 2315421697 CCU_OTA_Cond_Request "CCU_OTA_CondRequest";
CM_ SG_ 2315421697 CCU_OTA_Tele_Cranking "Vehicle cranking request signfal for OTA Update";
CM_ SG_ 2315421697 OTA_UI_Ready_request "OTA UI Ready";
CM_ SG_ 2315421697 OTA_Result "¾÷µ¥ÀÌÆ® °á°ú";
CM_ SG_ 2315421697 CF_AVN_InterAutoLockMode_Set2_Copy_1 "USM Request for Charing Connector Locking Mode (Auto/Lock/Unlock)";
CM_ BO_ 2290230529 "[P] Periodic";
CM_ SG_ 2290230529 CLU_Crc2Val "CLU_CyclicRedundancyCheck2Value";
CM_ SG_ 2290230529 CLU_AlvCnt2Val "CLU_AliveCounter2Value";
CM_ SG_ 2290230529 CLU_DTEVal "CLU_DTEValue";
CM_ SG_ 2290230529 CLU_TripUnitSta "CLU_TripUnitStatus";
CM_ SG_ 2290230529 CLU_LoFuelWrngSta "CLU_LowFuelWarningStatus";
CM_ SG_ 2290230529 CLU_RefuelDetSta "CLU_RefuelDetectedStatus";
CM_ SG_ 2290230529 CLU_TerrainMainSwSta "CLU_TerrainMainSwitchStatus";
CM_ BO_ 2290230530 "[P] Periodic";
CM_ SG_ 2290230530 CLU_RefuelWrnSta "CLU_RefuelWarningStatus";
CM_ SG_ 2290230530 CLU_DrvngModSwSta "CLU_DrivingModeSwitchStatus";
CM_ SG_ 2290230530 CLU_FuelLvlSta "CLU_FuelLevelStatus";
CM_ SG_ 2290230530 CLU_SRSWrngLmpSta "CLU_SRSWarningLampStatus";
CM_ SG_ 2290230530 CLU_TerrainModSwSta "CLU_TerrainModeSwitchStatus";
CM_ SG_ 2290230530 CLU_OdoVal "CLU_OdometerValue";
CM_ BO_ 2470763009 "[EC] On Event and On Change";
CM_ SG_ 2470763009 CLU_Crc9Val "CLU_CyclicRedundancyCheck9Value";
CM_ SG_ 2470763009 CLU_AlvCnt9Val "CLU_AliveCounter9Value";
CM_ SG_ 2470763009 USM_MdLmpClrSetReq "USM_MoodLampColorSetRequest";
CM_ SG_ 2470763009 USM_RrWiperRevSetReq "USM_RearWiperReverseSetRequest";
CM_ SG_ 2470763009 USM_RrStRemindSetReq "USM_RrseatReminderSetRequest(2nd :General: CLU20/CF_Clu_RrSeatRemindNValueSet)";
CM_ SG_ 2470763009 USM_RrWpcSetReq "USM_RearWpcSetRequest";
CM_ SG_ 2470763009 USM_WpcSetReq "USM_WpcSetRequest";
CM_ SG_ 2470763009 USM_SeqLmpSetReq "USM_SequencialLampSetRequest";
CM_ SG_ 2470763009 USM_UnlckWlcmSetReq "USM_UnlockWelcomeSetRequest";
CM_ SG_ 2470763009 USM_SmrtWlcmSetReq "USM_SmartWelcomeSetRequest";
CM_ SG_ 2470763009 USM_UipSetReq "2nd General: CF_Clu_UIPNValueSet";
CM_ SG_ 2470763009 USM_DigitalKeyEnblSetReq "Request to set the Digital Key ON or OFF(2nd General DB: CF_Clu_DigitalKeyNValueSet)";
CM_ SG_ 2470763009 USM_OwnerPhnRegSetReq "2nd general DB: CF_Clu_OwnerPhoneNValueSet";
CM_ SG_ 2470763009 USM_NFCCard1RegSetReq "2nd General DB:CF_Clu_NFCCard1NValueSet";
CM_ SG_ 2470763009 USM_NFCCard2RegSetReq "2nd General DB:CF_Clu_NFCCard2NValueSet";
CM_ SG_ 2470763009 USM_ProcStpReq "2nd General DB:CF_Clu_ProcessStopReq";
CM_ SG_ 2470763009 USM_PwrAutoOffTimeSetReq "USM_PowerAutoofftimeSetRequest";
CM_ SG_ 2470763009 USM_RrStRemindSetReq_RestMode "Request to set  Restmod of Rear Seat remind";
CM_ SG_ 2470763009 USM_1stRrStRemindSetReq "USM_RrseatReminderSetRequest(2nd :General: CLU21/CF_Clu_1stRrSeatRemindNValueSet)";
CM_ SG_ 2470763009 USM_Wpc2SetReq "USM_Wpc2SetRequest";
CM_ BO_ 2231452929 "[P] Periodic";
CM_ SG_ 2231452929 DATC_Crc1Val "DATC_CyclicRedundancyCheck1Value";
CM_ SG_ 2231452929 DATC_AlvCnt1Val "DATC_AliveCounter1Value";
CM_ SG_ 2231452929 DATC_PtcRlySta "DATC_PtcRelayStatus";
CM_ SG_ 2231452929 DATC_ManufacturerTyp "DATC_ManufacturerType";
CM_ SG_ 2231452929 DATC_DatcPwmSts "Status of E-comp";
CM_ SG_ 2231452929 DATC_AcnCompTyp "DATC_AirconCompressorType";
CM_ SG_ 2231452929 DATC_EewpRpmLvlReq "DATC_EewpRpmlevelReq";
CM_ SG_ 2231452929 DATC_Cooldown "Complete of cooldown";
CM_ SG_ 2231452929 DATC_AcnReq "DATC_AirconRequest";
CM_ SG_ 2231452929 DATC_BlwSta "DATC_BlowerStatus";
CM_ SG_ 2231452929 DATC_BlwMaxSta "DATC_BlowerMaxStatus";
CM_ SG_ 2231452929 DATC_EngStrtReq "DATC_EngineStartRequest";
CM_ SG_ 2231452929 DATC_IsgInhbtReq "DATC_IsgInhibitRequset";
CM_ SG_ 2231452929 DATC_AcnCompOnReq "DATC_AirconCompressorOnRequest";
CM_ SG_ 2231452929 DATC_SrvLmpReq "DATC_ServiceLampRequest";
CM_ SG_ 2231452929 DATC_EcvFltSta "DATC_EcvFaultStatus";
CM_ SG_ 2231452929 DATC_CalcAcnCompTqVal "DATC_CalculatedAirconCompressortorqueValue";
CM_ BO_ 2231452930 "[P] Periodic";
CM_ SG_ 2231452930 DATC_AcnECompOpSta "DATC_AirconElectricCompressorOperationStatus";
CM_ SG_ 2231452930 DATC_HVCompIntlkSta "DATC_HighVoltageCompressorInterlockStatus";
CM_ SG_ 2231452930 DATC_HVIntDischrgLkReq "DATC_HighVoltageInterlockDischargeRequest";
CM_ SG_ 2231452930 DATC_AcnECompMaxReqPwrVal "DATC_AirconElectricalCompressorMaximumRequestPowerValue";
CM_ SG_ 2231452930 DATC_AcnCompFltSta "DATC_AirconElectricCompressorFaultStatus";
CM_ SG_ 2231452930 DATC_AcnECompCnsmptPwrVal "DATC_AirconElectricalCompressorConsumptionPowerValue";
CM_ SG_ 2231452930 DATC_MainRlyOffReq "DATC_MainRelayoffRequest";
CM_ SG_ 2231452930 DATC_MixDfgSelSta "DATC_MixDefogSelectStatus";
CM_ SG_ 2231452930 DATC_BattChlrVlvSta "Battery chiller valve status";
CM_ SG_ 2231452930 DATC_WaterPmpOnReq "DATC_WaterPumpOnRequest";
CM_ SG_ 2231452930 DATC_AcnECompSpdVal "DATC_AirconElectricalCompressorSpeedValue";
CM_ SG_ 2231452930 DATC_AcnCompSlpModCodVal "DATC_AirconCompressorSleepModeCodeValue";
CM_ BO_ 2231452931 "[P] Periodic";
CM_ SG_ 2231452931 DATC_AcnCompWaitCodVal "DATC_AirconCompressorWaitCode";
CM_ SG_ 2231452931 DATC_PeEwpRPMReq "DATC_PeEwpRpmRequest";
CM_ SG_ 2231452931 DATC_AEwpSpdRpmReq "DATC_AsistenceEwpSpeedRpmRequest";
CM_ SG_ 2231452931 DATC_RadFanReq_Duty "This signal indicates Request cooling fan speed to cool HVAC System (Duty)";
CM_ SG_ 2231452931 DATC_OutTempSnsrVal "DATC_OutsideTemperatureSensorValue";
CM_ SG_ 2231452931 DATC_ActvEco "DATC_ActiveEco";
CM_ SG_ 2231452931 DATC_AUTOActv "DATCAutoActivation";
CM_ SG_ 2231452931 DATC_DfgSw "DATC_DefogSwitch";
CM_ SG_ 2231452931 DATC_BattChlrVlv_FltCode "Battery Chiller Filt Code";
CM_ SG_ 2231452931 DATC_BattEvapVlvSta "BATTERY COOL V/V (EVAP) STATUS";
CM_ SG_ 2231452931 DATC_BattEvapVlv_FltCode "BATTERY COOL V/V (EVAP) FltCode";
CM_ SG_ 2231452931 DATC_Wrmup "Complete of warmup";
CM_ SG_ 2231452931 DATC_SSC_EngStrtReq "Engine start request in SSC state";
CM_ BO_ 2231452932 "[P] Periodic";
CM_ SG_ 2231452932 DATC_SSC_InhbtReq "Request to EMS not to enter SSC";
CM_ SG_ 2231452932 DATC_EngIdlRpmUpReq "DATC_EngineIdleRpmUpRequest";
CM_ SG_ 2231452932 DATC_MaxBlwVolt "DATC_MaxBlowerVoltage";
CM_ SG_ 2231452932 DATC_HVACPmpOpSta "HVAC Pump Operation Status";
CM_ SG_ 2231452932 DATC_MildWrmup "Mild Warmup State";
CM_ SG_ 2231452932 DATC_BlwSta_Rr "DATC_BlowerStatus_Rear";
CM_ SG_ 2231452932 DATC_BattEwpOpReq "Battery EWP Operating Request";
CM_ BO_ 2382594561 "[PE] Periodic and On Event";
CM_ SG_ 2382594561 DATC_Crc5Val "DATC_CyclicRedundancyCheck5Value";
CM_ SG_ 2382594561 DATC_AlvCnt5Val "DATC_AliveCounter5Value";
CM_ SG_ 2382594561 DATC_FrDrvModDis "DATC_FrontDriverModeDisplay";
CM_ SG_ 2382594561 DATC_FrPassModDis "DATC_FrontPassengerModeDisplay";
CM_ SG_ 2382594561 DATC_ClmtTxtPopupOSD "Climate Text Pop-up OSD";
CM_ SG_ 2382594561 DATC_TempDispUnitSta "DATC_TemperatureDiplayUnitStatus";
CM_ SG_ 2382594561 DATC_DrvAutoDis "DATC_DriverAutoDisplay";
CM_ SG_ 2382594561 DATC_FrChgReqDis "DATC_FrontChangeRequestDisplay";
CM_ SG_ 2382594561 DATC_FrClmtScrnDis "DATC_FrontClimateScreenDisplay";
CM_ SG_ 2382594561 DATC_AcDis "DATC_ACDisplay";
CM_ SG_ 2382594561 DATC_IntakeSta "DATC_IntakeStatus";
CM_ SG_ 2382594561 DATC_TempDrLvl "Level of temp door";
CM_ SG_ 2382594561 DATC_BattCompPwrCnsmptn_W "This signal indicates consumption power by e-compressor for battery";
CM_ BO_ 649 "[EC] On Event and On Change";
CM_ SG_ 649 DLBCU_SmartCtrl_1h "½º¸¶Æ® ÀÚ¼¼Á¦¾î DLBCU ¿¬µ¿ Á¶Àý¿¡ µû¸¥ °³¼±ÇöÈ² AVN Ç¥½Ã¹®±¸_1½Ã°£";
CM_ SG_ 649 DLBCU_SmartCtrl_2h "½º¸¶Æ® ÀÚ¼¼Á¦¾î DLBCU ¿¬µ¿ Á¶Àý¿¡ µû¸¥ °³¼±ÇöÈ² AVN Ç¥½Ã ¹®±¸_2½Ã°£";
CM_ SG_ 649 DLBCU_SmartCtrl_Status "½º¸¶Æ® ÀÚ¼¼Á¦¾î 2´Ü°è DLBCU ¿¬µ¿ Á¶Àý µ¿ÀÛ ½ÃÀÛ / Á¾·á / Áß´Ü AVN ÆË¾÷";
CM_ BO_ 2176872449 "[P] Periodic";
CM_ SG_ 2176872449 HTCU_Crc5Val "HTCU_CyclicRedundancyCheck5Value";
CM_ SG_ 2176872449 HTCU_AlvCnt5Val "HTCU_AliveCounter5Value";
CM_ SG_ 2176872449 HDCT_AddtnlTqLssVal "Additional Torque Loss Value ## TCU16 - CR_Tcu_AddTqLoss_Pc";
CM_ SG_ 2176872449 HDCT_OBDSta "OBD Status ## TCU16 - CF_Tcu_ObdStat";
CM_ SG_ 2176872449 HDCT_OBDErrSta "OBD Error Status ## TCU16 - CF_Tcu_ObdRelErr";
CM_ SG_ 2176872449 HDCT_StcShftLrchCtrl "Static Shift Lurch Control ## TCU16 - CF_Tcu_StaticLurchCtl";
CM_ SG_ 2176872449 HDCT_EngCltchLmphmMod "Engine Clutch Limphome Mode ## TCU16 - CF_Tcu_CltLimAct";
CM_ SG_ 2176872449 HDCT_CurrPrgrm "Current Program ## TCU16 - CF_Tcu_CurProgram";
CM_ SG_ 2176872449 HDCT_FltSta "TCU fault status ## TCU16 - CF_Tcu_Flt";
CM_ SG_ 2176872449 HDCT_MCUAntJrkInhbt "MCU Anti-Jerk Inhibition ## TCU16 - CF_Tcu_MCUAntiJerkInh";
CM_ SG_ 2176872449 HDCT_TrgtGear "Target Gear ## TCU11 - CF_Tcu_TarGe";
CM_ SG_ 2176872449 HDCT_CurrGear "Current Gear ## TCU11 - HDCT_CurrGear";
CM_ SG_ 2176872449 HDCT_GearSelDis "Gear Select Display ## TCU11 - CF_Tcu_GarSelDisp";
CM_ BO_ 2176872452 "[P] Periodic";
CM_ BO_ 2172675329 "[P] Periodic";
CM_ SG_ 2172675329 IEB_Crc1Val "IEB_CyclicRedundancyCheck1Value";
CM_ SG_ 2172675329 IEB_AlvCnt1Val "IEB_AliveCounter1Value";
CM_ SG_ 2172675329 IEB_SrvLmpDis "IEB_ServiceLampDisplay ##2G##ESC - AHB1 - CF_Ahb_SLmp";
CM_ SG_ 2172675329 IEB_DfctvSta "IEB_DefectiveStatus ##2G##ESC - AHB1 - CF_Ahb_Def";
CM_ SG_ 2172675329 IEB_ActvSta "IEB_ActiveStatus ##2G##ESC - AHB1 - CF_Ahb_Act";
CM_ SG_ 2172675329 IEB_DiagSta "IEB_DiagnosticStatus ##2G##ESC - AHB1 - CF_Ahb_Diag";
CM_ SG_ 2172675329 IEB_WrngLmpDis "IEB_WarningLampDisplay ##2G##ESC - AHB1 - CF_Ahb_WLmp";
CM_ SG_ 2172675329 IEB_MILReq "MIL Requeset";
CM_ SG_ 2172675329 IEB_DriftModeStaDis "This signal is for a pop-up display on restriction status of drift mode activation";
CM_ SG_ 2172675329 IEB_StrkDpthmmVal "IEB_StrokeDepthmmValue ##2G##ESC - AHB1 - CR_Ahb_StDep_mm";
CM_ SG_ 2172675329 IEB_BrkActvSta "IEB_BrakeActiveStatus ##2G##ESC - AHB1 - CF_Esc_BrakeAct";
CM_ SG_ 2172675329 IEB_PdlTrvlSnsrFailSta "IEB_PedalTravelSensorFailStatus ##2G##ESC - AHB1 - CF_Ahb_SnsFail";
CM_ SG_ 2172675329 IEB_PdlCalibSta "IEB_PedalCalibrationStatus ##2G##ESC - AHB1 - CF_Ahb_PedalCalStat";
CM_ SG_ 2172675329 IEB_BzrSta "IEB_BuzzerStatus ##2G##ESC - AHB1 - CF_Ahb_Bzzr";
CM_ BO_ 2172675330 "[P] Periodic";
CM_ SG_ 2172675330 IEB_Sta "IEB_Status ##2G##ESC - EBS1 - CF_Brk_EBSStat";
CM_ SG_ 2172675330 IEB_SnsrFailSta "IEB_SensorFailStatus ##2G##ESC - EBS1 - CF_Brk_SnsFail";
CM_ SG_ 2172675330 IEB_EstTtlBrkFrcNmVal "IEB_EstimatedTotalBrakeForceValue ##2G##ESC - EBS1 - CR_Brk_EstTot_Nm";
CM_ SG_ 2172675330 IEB_RbsWrngLmpSta "IEB_RbsWarningLamp ##2G##ESC - EBS1 - CF_Brk_RBSWLamp";
CM_ SG_ 2172675330 IEB_StrkDpthPcVal "IEB_StrokeDepthPcValue ##2G##ESC - EBS2 - CR_Brk_StkDep_Pc";
CM_ SG_ 2172675330 IEB_EstDpthPcVal "IEB_EstimatedPedalDepthValue ##2G##ESC - EBS2 - CR_Brk_Est_StkDep_Pc";
CM_ SG_ 2172675330 IEB_AbsNGearReq "IEB_AbsNGearRequest ##2G##ESC - TCS11 - CF_Brk_AbsNReq";
CM_ SG_ 2172675330 IEB_EstBrkPdlValVldSta "IEB_EstimatedBrakePedalValueValidityStatus ##2G##ESC - EBS2 - CF_Brk_Est_StkValid";
CM_ SG_ 2172675330 IEB_VacSysDfctvSta "IEB_VacuumSystemDefectiveStatus ##2G##ESC - EBS1 - CF_Brk_VacuumSysDef";
CM_ SG_ 2172675330 IEB_DriftEscModSta_VDC "ESC/VDC mode command from DMIC by AVNT custom mode select";
CM_ SG_ 2172675330 IEB_RegenTqLimitNmVal_Frnt "IEB_RegenTorqueLimitValue ##2G##ESC - EBS1 - CR_Brk_RegenTqLimit_Nm";
CM_ BO_ 2172675331 "[P] Periodic";
CM_ SG_ 2172675331 IEB_RegenTqLimitNmVal_Rear "IEB_RegenTorqueLimitValue Rear";
CM_ SG_ 2172675331 IEB_DrvWhlSlipFlg_Frnt "Slip status of driving wheel ##2G##ESC ? EBS2 ? CF_Brk_DrvWhlSlipFlg";
CM_ SG_ 2172675331 IEB_IndDriftMode "Signal for feedback from AVNT drift mode ON/OFF command";
CM_ SG_ 2172675331 IEB_IndDriftEcsModSta "Signal for feed back of  ECS mode command from DMIC by AVNT custom mode select";
CM_ SG_ 2172675331 IEB_IndDriftElsdModSta "Signal for feed back of ELSD mode command from DMIC by AVNT custom mode select";
CM_ SG_ 2172675331 IEB_TCS_Req "IEB_TCS_Request";
CM_ SG_ 2172675331 IEB_RSC_Req "IEB_RSC_Request";
CM_ SG_ 2172675331 TCS_TqFlag_Frnt "TCS_TorqueFlag_Front";
CM_ SG_ 2172675331 TCS_TqFlag_Rear "TCS_TorqueFlag_Rear";
CM_ SG_ 2172675331 RSC_TqFlag_Frnt "RSC_TorqueFlag_Front";
CM_ SG_ 2172675331 RSC_TqFlag_Rear "RSC_TorqueFlag_Rear";
CM_ SG_ 2172675331 TCS_TqIntrvntnVal_Frnt "TCS_TorqueInterventionValue_Front";
CM_ SG_ 2172675331 TCS_TqIntrvntnVal_Rear "TCS_TorqueInterventionValue_Rear";
CM_ SG_ 2172675331 RSC_TqIntrvntnVal_Frnt "RSC_TorqueInterventionValue_Front";
CM_ SG_ 2172675331 RSC_TqIntrvntnVal_Rear "RSC_TorqueInterventionValue_Rear";
CM_ BO_ 2172675332 "[P] Periodic";
CM_ SG_ 2172675332 TCS_MtrTrgtRpm_Flag_Frnt "TCS_MotorTargetRPM_Flag_Front";
CM_ SG_ 2172675332 TCS_MtrTrgtRpm_Flag_Rear "TCS_MotorTargetRPM_Flag_Rear";
CM_ SG_ 2172675332 IEB_DriftElsdModSta "ELSD mode command from DMIC by AVNT custom mode select";
CM_ SG_ 2172675332 TCS_MtrTrgtRpm_Rear "TCS_MotorTargetRPM_Rear";
CM_ SG_ 2172675332 IEB_DriftModeSta "Display";
CM_ SG_ 2172675332 IEB_DriftModeActSta "ON/OFF status, Symbol";
CM_ SG_ 2172675332 MCU_AntiJerk_Inhbtsta "MCU_AntiJerk_Inhbtsta is a signal to inform the MCU of anti-jerk control prohibition in order to prevent side effects caused by intervention in the IEB when ABS control and MCU anti-jerk control overlap.";
CM_ SG_ 2172675332 IEB_Motor_ProtectModSta "It is a signal to notify when the internal motor protection mode of the electric integrated booster is activated.";
CM_ SG_ 2172675332 IEB_DriftEcsModSta "ECS mode command from DMIC by AVNT custom mode select";
CM_ SG_ 2172675332 IEB_EstBrkSacFrcNmVal "Estimated brake force value for stop assist control";
CM_ SG_ 2172675332 IEB_IndDriftEscModSta_TCS "Signal for feed back of TCS mode change from DMIC by AVNT custom mode select";
CM_ SG_ 2172675332 IEB_DriftMdpsModSta "MDPS mode command from DMIC by AVNT custom mode select";
CM_ SG_ 2172675332 IEB_IndDriftEscModSta_VDC "Signal for feed back of ESC/VDC mode command from DMIC by AVNT custom mode select";
CM_ SG_ 2172675332 IEB_IndDriftMdpsModSta "Signal for feed back of MDPS mode command from DMIC by AVNT custom mode select";
CM_ SG_ 2172675332 TCS_MtrTrgtRpm_Frnt "TCS_MotorTargetRPM_Front";
CM_ BO_ 761 "[PE] Periodic and On Event";
CM_ SG_ 761 SBCM_AST_Crc3Val "SBCM_AST_CyclicRedundancyCheck3Value";
CM_ SG_ 761 SBCM_AST_AlvCnt3Val "SBCM_AST_AliveCounter3Value";
CM_ SG_ 761 SBCM_Longkey_ASTDrAtClsSwSta "FCS Power Door Long key Status";
CM_ SG_ 761 Hood_TypeOption_AST "E-Hood_Option Type";
CM_ BO_ 758 "[PE] Periodic and On Event";
CM_ SG_ 758 SBCM_DRV_Crc2Val "SBCM_DRV_CyclicRedundancyCheck2Value";
CM_ SG_ 758 DoorLock_CtrlDrLkUnLkSwSta_SBCM "Central Door Lock/Unlock Switch State";
CM_ SG_ 758 SBCM_DRV_AlvCnt2Val "SBCM_DRV_AliveCounter2Value";
CM_ SG_ 758 CDMAutoWashModeSet_SBCM "Auto wash mode set signal for CDM from SBCM_DRV";
CM_ SG_ 758 ECMMRR_PLUS "ECM Voltage value";
CM_ BO_ 763 "[PE] Periodic and On Event";
CM_ SG_ 763 SBCM_DRV_Crc3Val "SBCM_DRV_CyclicRedundancyCheck3Value";
CM_ SG_ 763 CDM_TypeOption "CDM_HS_OptionType";
CM_ SG_ 763 SBCM_DRV_AlvCnt3Val "SBCM_DRV_AliveCounter3Value";
CM_ SG_ 763 CDM_ImmeChgSw_SBCM "State of Immediate Charging Switch";
CM_ SG_ 763 CDM_OpnClsState_SBCM "CDM_HS_ OpenCloseState";
CM_ SG_ 763 CDM_WarnMsg_SBCM "CDM_HS_WarningMessage";
CM_ SG_ 763 CDM_CmdStatus_SBCM "CDM_HS_CommandStatus";
CM_ SG_ 763 Hood_TypeOption "E-Hood_Option Type";
CM_ SG_ 763 CDM_GbtImmeChgSw_SBCM "State of Immediate Charging Switch";
CM_ SG_ 763 CDM_GbtOpnClsState_SBCM "CDM_HS_ OpenCloseState";
CM_ SG_ 763 CDM_GbtWarnMsg_SBCM "CDM_HS_WarningMessage";
CM_ BO_ 742 "[PE] Periodic and On Event";
CM_ SG_ 742 SGU_FltSta "It indicates if SGU is normal or fault";
CM_ SG_ 742 SGU_BlindOnOffSet "It indicates smart glass user setting for roll blind operation.";
CM_ SG_ 742 SGU_BlindOpenReq "Blind Open Command by SGU";
CM_ SG_ 742 SGU_FltVal "It indicates details of SGU fault status";
CM_ SG_ 742 SGU_Roof_OprLv "It indicates tranmittance of Roof Smart Glass";
CM_ SG_ 742 SGU_2ndLeftDoor_OprLv "It indicates tranmittance of 2nd Row Left Door Smart Glass";
CM_ SG_ 742 SGU_2ndRightDoor_OprLv "It indicates transmittance of 2nd Row Right Door Smart Glass";
CM_ SG_ 742 SGU_3rdLeftDoor_OprLv "It Indicates transmittance of 3rd Row Left Door Smart Glass";
CM_ SG_ 742 SGU_3rdRightDoor_OprLv "It Indicates transmittance of 3rd Row Right Door Smart Glass";
CM_ SG_ 742 SGU_RearWindow_OprLv "It indicates transmittance of Rear Window Smart Glass";
CM_ SG_ 742 SGU_OprLvVehicleSet "It indicates Smart Glass Maximum Operation Level Setting Value for each vehicles.";
CM_ SG_ 742 SGU_CH1_VoltageVal "It indicates CH1 Alteranting Current voltage value of  smart glass unit";
CM_ SG_ 742 SGU_CH2_VoltageVal "It indicates CH2 Alternating Current voltage value of smart glass unit";
CM_ SG_ 742 SGU_RdySta "It indicates if SGU is ready or not to operate smart glass";
BA_DEF_ BO_ "DiagState" ENUM "No","Yes" ;
BA_DEF_ BO_ "DiagResponse" ENUM "No","Yes" ;
BA_DEF_ BO_ "DiagRequest" ENUM "No","Yes" ;
BA_DEF_ BO_ "TpMessage" ENUM "No","Yes" ;
BA_DEF_ BO_ "UsrMsgIDSforwardDeviation" INT 0 100 ;
BA_DEF_ BO_ "UsrMsgIDSbackwardDeviation" INT 50 1000 ;
BA_DEF_ BO_ "GenMsgCycleTime" INT 0 2000 ;
BA_DEF_ BO_ "GenMsgStartDelayTime" INT 0 2000 ;
BA_DEF_ BO_ "GenMsgSendType" ENUM "Cyclic","NoMsgSendType" ;
BA_DEF_ BO_ "GenMsgCycleTimeFast" INT 0 500 ;
BA_DEF_ BO_ "GenMsgDelayTime" INT 0 20 ;
BA_DEF_ BO_ "GenMsgILSupport" ENUM "No","Yes" ;
BA_DEF_ BO_ "GenMsgNrOfRepetition" INT 0 3 ;
BA_DEF_ BO_ "NmMessage" ENUM "No","Yes" ;
BA_DEF_ BO_ "NWM-Botschaft" ENUM "No","Yes" ;
BA_DEF_ BO_ "TpTxIndex" INT 0 65535 ;
BA_DEF_ BO_ "VFrameFormat" ENUM "StandardCAN","ExtendedCAN","reserved","reserved","reserved","reserved","reserved","reserved","reserved","reserved","reserved","reserved","reserved","reserved","StandardCAN_FD","ExtendedCAN_FD" ;
BA_DEF_ SG_ "UserSigValidity" ENUM "B+","ACC","IG","IG1","IG2","IG3","IG1 or IG2","IG1 or IG3","Undef" ;
BA_DEF_ SG_ "TimeoutValue" STRING ;
BA_DEF_ SG_ "UsrSigPurpose" ENUM "Undef","FN","DIAG","DIAG(Req)","DIAG(Res)","DIAG(Phy)","DEV","CCP(Req)","CCP(Res)","NM","TP" ;
BA_DEF_ SG_ "GenSigStartValue" INT 0 1215752192 ;
BA_DEF_ SG_ "NetworkRequest" ENUM "Yes","No" ;
BA_DEF_ SG_ "NetworkRequestHoldingTime" INT 0 65535 ;
BA_DEF_ SG_ "Description" STRING ;
BA_DEF_ SG_ "Version" STRING ;
BA_DEF_ SG_ "GenSigEnvVarType" ENUM "Int","Float","Undef" ;
BA_DEF_ SG_ "GenSigSendType" ENUM "Cyclic","OnWrite","OnWriteWithRepetition","OnChange","OnChangeWithRepetition","IfActive","IfActiveWithRepetition","NoSigSendType","OnChangeAndIfActive","OnChangeAndIfActiveWithRepetition" ;
BA_DEF_ SG_ "GwSigLatencyTime" INT 0 65536 ;
BA_DEF_ SG_ "GwSigMissingSourceType" ENUM "Undef","OldValue","DefaultValue","InitialValue" ;
BA_DEF_ SG_ "NWM-WakeupAllowed" ENUM "<n.a.>" ;
BA_DEF_ SG_ "RoutingFactor" INT 1 1215752192 ;
BA_DEF_REL_ BU_SG_REL_ "GenSigTimeoutTime" INT 0 7000 ;
BA_DEF_DEF_ "DiagState" "No" ;
BA_DEF_DEF_ "DiagResponse" "No" ;
BA_DEF_DEF_ "DiagRequest" "No" ;
BA_DEF_DEF_ "TpMessage" "No" ;
BA_DEF_DEF_ "UsrMsgIDSforwardDeviation" 10 ;
BA_DEF_DEF_ "UsrMsgIDSbackwardDeviation" 100 ;
BA_DEF_DEF_ "GenMsgCycleTime" 200 ;
BA_DEF_DEF_ "GenMsgStartDelayTime" 0 ;
BA_DEF_DEF_ "GenMsgSendType" "NoMsgSendType" ;
BA_DEF_DEF_ "GenMsgCycleTimeFast" 40 ;
BA_DEF_DEF_ "GenMsgDelayTime" 20 ;
BA_DEF_DEF_ "GenMsgILSupport" "Yes" ;
BA_DEF_DEF_ "GenMsgNrOfRepetition" 3 ;
BA_DEF_DEF_ "NmMessage" "No" ;
BA_DEF_DEF_ "NWM-Botschaft" "No" ;
BA_DEF_DEF_ "TpTxIndex" 0 ;
BA_DEF_DEF_ "VFrameFormat" "StandardCAN" ;
BA_DEF_DEF_ "UserSigValidity" "IG" ;
BA_DEF_DEF_ "TimeoutValue" "" ;
BA_DEF_DEF_ "UsrSigPurpose" "FN" ;
BA_DEF_DEF_ "GenSigStartValue" 0 ;
BA_DEF_DEF_ "NetworkRequest" "No" ;
BA_DEF_DEF_ "NetworkRequestHoldingTime" 0 ;
BA_DEF_DEF_ "Description" "" ;
BA_DEF_DEF_ "Version" "" ;
BA_DEF_DEF_ "GenSigEnvVarType" "Undef" ;
BA_DEF_DEF_ "GenSigSendType" "NoSigSendType" ;
BA_DEF_DEF_ "GwSigLatencyTime" 40 ;
BA_DEF_DEF_ "GwSigMissingSourceType" "Undef" ;
BA_DEF_DEF_ "NWM-WakeupAllowed" "<n.a.>" ;
BA_DEF_DEF_ "RoutingFactor" 1 ;
BA_DEF_DEF_REL_ "GenSigTimeoutTime" 500 ;
BA_ "GenMsgCycleTime" BO_ 694 0;
BA_ "Description" SG_ 694 ASAU_NotFootMsgOperStaWarn "Passenger Foot Massage Operation Disable Mode";
BA_ "GenSigSendType" SG_ 694 ASAU_NotFootMsgOperStaWarn 4;
BA_ "UserSigValidity" SG_ 694 ASAU_NotFootMsgOperStaWarn 3;
BA_ "NetworkRequest" SG_ 694 ASAU_NotFootMsgOperStaWarn 0;
BA_ "NetworkRequestHoldingTime" SG_ 694 ASAU_NotFootMsgOperStaWarn 5000;
BA_ "RoutingFactor" SG_ 694 ASAU_NotFootMsgOperStaWarn 0;
BA_ "Version" SG_ 694 ASAU_NotFootMsgOperStaWarn "20.08.00";
BA_ "GenMsgSendType" BO_ 2344811009 0;
BA_ "GenMsgCycleTimeFast" BO_ 2344811009 0;
BA_ "GenMsgNrOfRepetition" BO_ 2344811009 0;
BA_ "VFrameFormat" BO_ 2344811009 1;
BA_ "Description" SG_ 2344811009 BMS_Crc2Val "The data area for CRC calculation is based on the data length (DLC) of the message DB.

The CRC shall be calculated over the entire data block (excluding the CRC bytes) including the user data, alive counter and Data ID



- CRC Polynomial (0x1021) , Initial Value : 0xFFFF, XOR value : 0x0000, Data ID : Message ID + 0xF800 

- The initial value is for CRC calculation and the message should be sent with the calculated result value. 

- The mathematical expression to 16 bit CRC polynomial is given here. G(x) = x16 + x12 + x5 + 1



<For CRC calculation of CAN-FD Msg for HS CAN domain ECUs>



- HS-CAN Messages that routed from CAN-FD domain are using 29 bit Extended CAN ID and splitted into 8 Byte Messages.

(from 1 to 4 Msgs, depending on source CAN-FD Msg¡¯s DLC)

- For splitted CAN-FD Msgs¡¯ CRC calculation, HS CAN ECUs should use source CAN-FD Msg¡¯s original STD ID. 

- The original STD ID can be read from Ext ID¡¯s 4~6th Byte.

Eg. STD 0x6AA : EXT SPLT 0x1A8[6AA]01 / 0x1A8[6AA]02 / 0x1A8[6AA]03 / 0x1A8[6AA]04 

(2~4th splitited Msgs can be omitted depending on source CAN-FD Msg¡¯s DLC)

- Aslo, HS-CAN ECUs should use merged data block (from whole splitted Msg) for CRC calculation.";
BA_ "GenSigStartValue" SG_ 2344811009 BMS_Crc2Val 65535;
BA_ "UserSigValidity" SG_ 2344811009 BMS_Crc2Val 3;
BA_ "RoutingFactor" SG_ 2344811009 BMS_Crc2Val 2;
BA_ "Version" SG_ 2344811009 BMS_Crc2Val "21.09.03";
BA_ "Description" SG_ 2344811009 BMS_AlvCnt2Val "For the first transmission request for a data element the counter shall be initialized with 0 and shall be incremented by 1 for every subsequent send request. 

When the counter reaches the maximum value(0xFF), then it shall restart with 0 for the next send request";
BA_ "UserSigValidity" SG_ 2344811009 BMS_AlvCnt2Val 3;
BA_ "RoutingFactor" SG_ 2344811009 BMS_AlvCnt2Val 2;
BA_ "Version" SG_ 2344811009 BMS_AlvCnt2Val "21.09.03";
BA_ "Description" SG_ 2344811009 xEV_SrvLmpReq "Service Lamp request";
BA_ "UserSigValidity" SG_ 2344811009 xEV_SrvLmpReq 7;
BA_ "RoutingFactor" SG_ 2344811009 xEV_SrvLmpReq 2;
BA_ "Version" SG_ 2344811009 xEV_SrvLmpReq "18.11.01";
BA_ "Description" SG_ 2344811009 xEV_MainRlyOnSta "Main Relay On Status";
BA_ "UserSigValidity" SG_ 2344811009 xEV_MainRlyOnSta 7;
BA_REL_ "GenSigTimeoutTime" BU_SG_REL_ ALBCU SG_ 2344811009 xEV_MainRlyOnSta 1500;
BA_REL_ "GenSigTimeoutTime" BU_SG_REL_ GW_APSU SG_ 2344811009 xEV_MainRlyOnSta 1500;
BA_REL_ "GenSigTimeoutTime" BU_SG_REL_ GW_DLBCU SG_ 2344811009 xEV_MainRlyOnSta 1500;
BA_REL_ "GenSigTimeoutTime" BU_SG_REL_ GW_DPSU SG_ 2344811009 xEV_MainRlyOnSta 1500;
BA_REL_ "GenSigTimeoutTime" BU_SG_REL_ GW_RLPSU SG_ 2344811009 xEV_MainRlyOnSta 1500;
BA_REL_ "GenSigTimeoutTime" BU_SG_REL_ GW_RRPSU SG_ 2344811009 xEV_MainRlyOnSta 1500;
BA_REL_ "GenSigTimeoutTime" BU_SG_REL_ RLHV SG_ 2344811009 xEV_MainRlyOnSta 1500;
BA_REL_ "GenSigTimeoutTime" BU_SG_REL_ RRHV SG_ 2344811009 xEV_MainRlyOnSta 1500;
BA_REL_ "GenSigTimeoutTime" BU_SG_REL_ SHVU_FR SG_ 2344811009 xEV_MainRlyOnSta 1500;
BA_REL_ "GenSigTimeoutTime" BU_SG_REL_ SHVU_RR SG_ 2344811009 xEV_MainRlyOnSta 1500;
BA_ "RoutingFactor" SG_ 2344811009 xEV_MainRlyOnSta 2;
BA_ "Version" SG_ 2344811009 xEV_MainRlyOnSta "18.11.01";
BA_ "Description" SG_ 2344811009 xEV_SysFltSta "BMS Fault";
BA_ "UserSigValidity" SG_ 2344811009 xEV_SysFltSta 7;
BA_ "RoutingFactor" SG_ 2344811009 xEV_SysFltSta 2;
BA_ "Version" SG_ 2344811009 xEV_SysFltSta "18.11.01";
BA_ "Description" SG_ 2344811009 EV_Unreliable_SOC "LFP Battery Unreliable SOC Alarm Flag (to Cluster/AVN)";
BA_ "UserSigValidity" SG_ 2344811009 EV_Unreliable_SOC 7;
BA_ "RoutingFactor" SG_ 2344811009 EV_Unreliable_SOC 2;
BA_ "Version" SG_ 2344811009 EV_Unreliable_SOC "23.03.01";
BA_ "Description" SG_ 2344811009 xEV_BattRmnEnrgVal "Difference of increased or decreased battery resistance";
BA_ "UserSigValidity" SG_ 2344811009 xEV_BattRmnEnrgVal 7;
BA_ "RoutingFactor" SG_ 2344811009 xEV_BattRmnEnrgVal 2;
BA_ "Version" SG_ 2344811009 xEV_BattRmnEnrgVal "18.11.01";
BA_ "Description" SG_ 2344811009 xEV_InltTempVal "Battery Inlet Temperature";
BA_ "UserSigValidity" SG_ 2344811009 xEV_InltTempVal 7;
BA_ "RoutingFactor" SG_ 2344811009 xEV_InltTempVal 2;
BA_ "Version" SG_ 2344811009 xEV_InltTempVal "20.07.05";
BA_ "Description" SG_ 2344811009 xEV_MinBattCelVoltVal "Minimum Battery Cell Voltage";
BA_ "GenSigStartValue" SG_ 2344811009 xEV_MinBattCelVoltVal 3;
BA_ "UserSigValidity" SG_ 2344811009 xEV_MinBattCelVoltVal 7;
BA_ "RoutingFactor" SG_ 2344811009 xEV_MinBattCelVoltVal 2;
BA_ "Version" SG_ 2344811009 xEV_MinBattCelVoltVal "18.11.01";
BA_ "Description" SG_ 2344811009 xEV_MaxBattCelVoltVal "Maximum Battery Cell Voltage";
BA_ "GenSigStartValue" SG_ 2344811009 xEV_MaxBattCelVoltVal 3;
BA_ "UserSigValidity" SG_ 2344811009 xEV_MaxBattCelVoltVal 7;
BA_ "RoutingFactor" SG_ 2344811009 xEV_MaxBattCelVoltVal 2;
BA_ "Version" SG_ 2344811009 xEV_MaxBattCelVoltVal "18.11.01";
BA_ "GenMsgSendType" BO_ 2344811010 0;
BA_ "GenMsgCycleTimeFast" BO_ 2344811010 0;
BA_ "GenMsgNrOfRepetition" BO_ 2344811010 0;
BA_ "VFrameFormat" BO_ 2344811010 1;
BA_ "Description" SG_ 2344811010 xEV_BattCurrVal "xEV_Battery Current Value (CR_Bms_BatI_A)";
BA_ "UserSigValidity" SG_ 2344811010 xEV_BattCurrVal 7;
BA_ "RoutingFactor" SG_ 2344811010 xEV_BattCurrVal 2;
BA_ "Version" SG_ 2344811010 xEV_BattCurrVal "18.11.01";
BA_ "Description" SG_ 2344811010 xEV_MinBattTempVal "Minimum Battery Temperature

(All the analog value indicate valid values except for Error ID)";
BA_ "UserSigValidity" SG_ 2344811010 xEV_MinBattTempVal 7;
BA_ "RoutingFactor" SG_ 2344811010 xEV_MinBattTempVal 2;
BA_ "Version" SG_ 2344811010 xEV_MinBattTempVal "21.10.04";
BA_ "Description" SG_ 2344811010 xEV_MaxBattTempVal "Maximum Battery Temperature";
BA_ "UserSigValidity" SG_ 2344811010 xEV_MaxBattTempVal 7;
BA_ "RoutingFactor" SG_ 2344811010 xEV_MaxBattTempVal 2;
BA_ "Version" SG_ 2344811010 xEV_MaxBattTempVal "18.11.01";
BA_ "Description" SG_ 2344811010 xEV_FanSpdStpSta "Battery Cooling Fan Speed Step";
BA_ "UserSigValidity" SG_ 2344811010 xEV_FanSpdStpSta 7;
BA_ "RoutingFactor" SG_ 2344811010 xEV_FanSpdStpSta 2;
BA_ "Version" SG_ 2344811010 xEV_FanSpdStpSta "18.11.01";
BA_ "Description" SG_ 2344811010 xEV_12VRlyOffAlrmReq "12V Battery Relay Off Alarm Request";
BA_ "UserSigValidity" SG_ 2344811010 xEV_12VRlyOffAlrmReq 7;
BA_ "RoutingFactor" SG_ 2344811010 xEV_12VRlyOffAlrmReq 2;
BA_ "Version" SG_ 2344811010 xEV_12VRlyOffAlrmReq "18.11.01";
BA_ "Description" SG_ 2344811010 xEV_12VRlyOnAlrmReq "12V Battery Relay On Alarm Request";
BA_ "UserSigValidity" SG_ 2344811010 xEV_12VRlyOnAlrmReq 7;
BA_ "RoutingFactor" SG_ 2344811010 xEV_12VRlyOnAlrmReq 2;
BA_ "Version" SG_ 2344811010 xEV_12VRlyOnAlrmReq "18.11.01";
BA_ "Description" SG_ 2344811010 xEV_DiagGrpVal "Diagnosis code";
BA_ "UserSigValidity" SG_ 2344811010 xEV_DiagGrpVal 7;
BA_ "RoutingFactor" SG_ 2344811010 xEV_DiagGrpVal 2;
BA_ "Version" SG_ 2344811010 xEV_DiagGrpVal "18.11.01";
BA_ "Description" SG_ 2344811010 xEV_DiagMonVal "Diagnosis data";
BA_ "UserSigValidity" SG_ 2344811010 xEV_DiagMonVal 7;
BA_ "RoutingFactor" SG_ 2344811010 xEV_DiagMonVal 2;
BA_ "Version" SG_ 2344811010 xEV_DiagMonVal "18.11.01";
BA_ "Description" SG_ 2344811010 xEV_SocDis "Cluster, AVN Display SOC

(All the analog value indicate valid values except for Error ID)";
BA_ "UserSigValidity" SG_ 2344811010 xEV_SocDis 7;
BA_REL_ "GenSigTimeoutTime" BU_SG_REL_ SWRC SG_ 2344811010 xEV_SocDis 1500;
BA_ "RoutingFactor" SG_ 2344811010 xEV_SocDis 2;
BA_ "Version" SG_ 2344811010 xEV_SocDis "21.10.04";
BA_ "GenMsgSendType" BO_ 2344811011 0;
BA_ "GenMsgCycleTimeFast" BO_ 2344811011 0;
BA_ "GenMsgNrOfRepetition" BO_ 2344811011 0;
BA_ "VFrameFormat" BO_ 2344811011 1;
BA_ "Description" SG_ 2344811011 PHEV_SubInltTempVal "Sub Pack Inlet Temperature

(If MSB is 1, (PH) = 1 * (HEX) ? 256 [¡É]

else (PH) = 1 * (HEX) [¡É])";
BA_ "UserSigValidity" SG_ 2344811011 PHEV_SubInltTempVal 7;
BA_ "RoutingFactor" SG_ 2344811011 PHEV_SubInltTempVal 2;
BA_ "Version" SG_ 2344811011 PHEV_SubInltTempVal "18.11.01";
BA_ "Description" SG_ 2344811011 xEV_12VAlarmReqForICU "xEV_12V Battery Alarm Request For ICU";
BA_ "UserSigValidity" SG_ 2344811011 xEV_12VAlarmReqForICU 7;
BA_ "RoutingFactor" SG_ 2344811011 xEV_12VAlarmReqForICU 2;
BA_ "Version" SG_ 2344811011 xEV_12VAlarmReqForICU "18.11.01";
BA_ "Description" SG_ 2344811011 xEV_AuxBattChrgReq "Aux. Battery Charge Request Flag

LV2 Charge Request : Battery Saver

LV1 Charge Request : Auxiliary Charge";
BA_ "UserSigValidity" SG_ 2344811011 xEV_AuxBattChrgReq 7;
BA_ "RoutingFactor" SG_ 2344811011 xEV_AuxBattChrgReq 2;
BA_ "Version" SG_ 2344811011 xEV_AuxBattChrgReq "23.02.01";
BA_ "Description" SG_ 2344811011 xEV_12VDarkCurrAlarmForICU "12V Battery Alarm request for ICU(CGW)";
BA_ "UserSigValidity" SG_ 2344811011 xEV_12VDarkCurrAlarmForICU 7;
BA_ "RoutingFactor" SG_ 2344811011 xEV_12VDarkCurrAlarmForICU 2;
BA_ "Version" SG_ 2344811011 xEV_12VDarkCurrAlarmForICU "18.11.01";
BA_ "Description" SG_ 2344811011 xEV_12VBatVLmt "xEV_12VBatteryVoltageLimit(CR_Bms_12V_BatV_Lmt)";
BA_ "UserSigValidity" SG_ 2344811011 xEV_12VBatVLmt 7;
BA_ "RoutingFactor" SG_ 2344811011 xEV_12VBatVLmt 2;
BA_ "Version" SG_ 2344811011 xEV_12VBatVLmt "18.11.01";
BA_ "Description" SG_ 2344811011 xEV_CharBatInfoReqForSDC "Function of determining first battery to charge (12V battery or High voltage battery)";
BA_ "UserSigValidity" SG_ 2344811011 xEV_CharBatInfoReqForSDC 7;
BA_ "RoutingFactor" SG_ 2344811011 xEV_CharBatInfoReqForSDC 2;
BA_ "Version" SG_ 2344811011 xEV_CharBatInfoReqForSDC "18.11.01";
BA_ "Description" SG_ 2344811011 xEV_ClimateOffReq "xEV_ClimateOffRequest  --Alarm flag at climate off requested (CF_Bms_ClimateOffReq)";
BA_ "UserSigValidity" SG_ 2344811011 xEV_ClimateOffReq 7;
BA_ "RoutingFactor" SG_ 2344811011 xEV_ClimateOffReq 2;
BA_ "Version" SG_ 2344811011 xEV_ClimateOffReq "18.11.01";
BA_ "Description" SG_ 2344811011 xEV_MainRlyOnRetrySta "BMS sets this Flag until BMS completes Relay ON Sequence for Relay recontact";
BA_ "UserSigValidity" SG_ 2344811011 xEV_MainRlyOnRetrySta 7;
BA_ "RoutingFactor" SG_ 2344811011 xEV_MainRlyOnRetrySta 2;
BA_ "Version" SG_ 2344811011 xEV_MainRlyOnRetrySta "18.11.01";
BA_ "Description" SG_ 2344811011 xEV_Bms_BlackBox_Data_req "For Saving BMS data set, this signal transmits to MCU";
BA_ "UserSigValidity" SG_ 2344811011 xEV_Bms_BlackBox_Data_req 7;
BA_ "RoutingFactor" SG_ 2344811011 xEV_Bms_BlackBox_Data_req 2;
BA_ "Version" SG_ 2344811011 xEV_Bms_BlackBox_Data_req "20.03.06";
BA_ "Description" SG_ 2344811011 xEV_12V_BatDchCurrLmt "xEV_12V Battery Discharge Current Limit (CR_Bms_12V_BatDchI_Lmt)";
BA_ "UserSigValidity" SG_ 2344811011 xEV_12V_BatDchCurrLmt 7;
BA_ "RoutingFactor" SG_ 2344811011 xEV_12V_BatDchCurrLmt 2;
BA_ "Version" SG_ 2344811011 xEV_12V_BatDchCurrLmt "18.11.01";
BA_ "Description" SG_ 2344811011 xEV_12VChargeReq "xEV_12VBatteryChargeRequest (for 12V battery over-discharge protection) (CF_Bms_12_ChargeReq)";
BA_ "UserSigValidity" SG_ 2344811011 xEV_12VChargeReq 7;
BA_ "RoutingFactor" SG_ 2344811011 xEV_12VChargeReq 2;
BA_ "Version" SG_ 2344811011 xEV_12VChargeReq "18.11.02";
BA_ "Description" SG_ 2344811011 xEV_BmsRomType "BMS rom type variation of Battery Pack Specification";
BA_ "UserSigValidity" SG_ 2344811011 xEV_BmsRomType 7;
BA_ "RoutingFactor" SG_ 2344811011 xEV_BmsRomType 2;
BA_ "Version" SG_ 2344811011 xEV_BmsRomType "21.01.03";
BA_ "Description" SG_ 2344811011 xEV_12V_CurrFltDetectReq "xEV_12V Battery Current Sensor Fault Detect Request";
BA_ "UserSigValidity" SG_ 2344811011 xEV_12V_CurrFltDetectReq 7;
BA_ "RoutingFactor" SG_ 2344811011 xEV_12V_CurrFltDetectReq 2;
BA_ "Version" SG_ 2344811011 xEV_12V_CurrFltDetectReq "19.01.00";
BA_ "Description" SG_ 2344811011 xEV_PRATempSnsVal_ "xEV_PRATemperatureSensorValue";
BA_ "UserSigValidity" SG_ 2344811011 xEV_PRATempSnsVal_ 7;
BA_ "RoutingFactor" SG_ 2344811011 xEV_PRATempSnsVal_ 2;
BA_ "Version" SG_ 2344811011 xEV_PRATempSnsVal_ "19.01.00";
BA_ "Description" SG_ 2344811011 xEV_PRATempSns2Val_ "xEV_PRATemperatureSensor2Value";
BA_ "UserSigValidity" SG_ 2344811011 xEV_PRATempSns2Val_ 7;
BA_ "RoutingFactor" SG_ 2344811011 xEV_PRATempSns2Val_ 2;
BA_ "Version" SG_ 2344811011 xEV_PRATempSns2Val_ "19.01.00";
BA_ "Description" SG_ 2344811011 xEV_12VRlyOnSwReq "12V relay ON switch ON status. BMS sets this Flag when 12V Relay Switch is ON.";
BA_ "UserSigValidity" SG_ 2344811011 xEV_12VRlyOnSwReq 7;
BA_ "RoutingFactor" SG_ 2344811011 xEV_12VRlyOnSwReq 2;
BA_ "Version" SG_ 2344811011 xEV_12VRlyOnSwReq "18.11.01";
BA_ "GenMsgSendType" BO_ 2344811012 0;
BA_ "GenMsgCycleTimeFast" BO_ 2344811012 0;
BA_ "GenMsgNrOfRepetition" BO_ 2344811012 0;
BA_ "VFrameFormat" BO_ 2344811012 1;
BA_ "Description" SG_ 2344811012 xEV_BattRCHTimeEst "calculated charging time by esrimated OBC output power

***HS CAN : BMS7(0x598), CR_Bms_RCHTimeEst***";
BA_ "UserSigValidity" SG_ 2344811012 xEV_BattRCHTimeEst 7;
BA_ "RoutingFactor" SG_ 2344811012 xEV_BattRCHTimeEst 2;
BA_ "Version" SG_ 2344811012 xEV_BattRCHTimeEst "19.04.06";
BA_ "Description" SG_ 2344811012 EV_DischrgCurrLimForV2X "Discharge Current Limit(for V2X)

***new signal***";
BA_ "UserSigValidity" SG_ 2344811012 EV_DischrgCurrLimForV2X 7;
BA_ "RoutingFactor" SG_ 2344811012 EV_DischrgCurrLimForV2X 2;
BA_ "Version" SG_ 2344811012 EV_DischrgCurrLimForV2X "20.04.03";
BA_ "Description" SG_ 2344811012 xEV_Bms_IsolDetDeactFuncSta "xEV_Isolation Detection Circuit Deactivate Function Status (GDS Function)";
BA_ "UserSigValidity" SG_ 2344811012 xEV_Bms_IsolDetDeactFuncSta 7;
BA_ "RoutingFactor" SG_ 2344811012 xEV_Bms_IsolDetDeactFuncSta 2;
BA_ "Version" SG_ 2344811012 xEV_Bms_IsolDetDeactFuncSta "20.06.10";
BA_ "Description" SG_ 2344811012 xEV_Bms_CellBalDeactFuncSta "xEV_Cell Balancing Deactivate Function Status (GDS Function)";
BA_ "UserSigValidity" SG_ 2344811012 xEV_Bms_CellBalDeactFuncSta 7;
BA_ "RoutingFactor" SG_ 2344811012 xEV_Bms_CellBalDeactFuncSta 2;
BA_ "Version" SG_ 2344811012 xEV_Bms_CellBalDeactFuncSta "20.06.10";
BA_ "Description" SG_ 2344811012 EV_V2XDischrgLimSocVal_SYNC "Feedback SOC of  V2X discharge limitation for sync by BMS

***New Signal***";
BA_ "UserSigValidity" SG_ 2344811012 EV_V2XDischrgLimSocVal_SYNC 7;
BA_ "RoutingFactor" SG_ 2344811012 EV_V2XDischrgLimSocVal_SYNC 2;
BA_ "Version" SG_ 2344811012 EV_V2XDischrgLimSocVal_SYNC "20.11.02";
BA_ "Description" SG_ 2344811012 xEV_BMS_SOC_2nd "2nd SOC for NEV";
BA_ "UserSigValidity" SG_ 2344811012 xEV_BMS_SOC_2nd 7;
BA_ "RoutingFactor" SG_ 2344811012 xEV_BMS_SOC_2nd 2;
BA_ "Version" SG_ 2344811012 xEV_BMS_SOC_2nd "20.03.07";
BA_ "GenMsgSendType" BO_ 2315421697 0;
BA_ "VFrameFormat" BO_ 2315421697 1;
BA_ "Description" SG_ 2315421697 CCU_AP_OTA_Crc1Val "The data area for CRC calculation is based on the data length (DLC) of the message DB.

The CRC shall be calculated over the entire data block (excluding the CRC bytes) including the user data, alive counter and Data ID



- CRC Polynomial (0x1021) , Initial Value : 0xFFFF, XOR value : 0x0000, Data ID : Message ID + 0xF800 

- The initial value is for CRC calculation and the message should be sent with the calculated result value. 

- The mathematical expression to 16 bit CRC polynomial is given here. G(x) = x16 + x12 + x5 + 1



<For CRC calculation of CAN-FD Msg for HS CAN domain ECUs>



- HS-CAN Messages that routed from CAN-FD domain are using 29 bit Extended CAN ID and splitted into 8 Byte Messages.

(from 1 to 4 Msgs, depending on source CAN-FD Msg¡¯s DLC)

- For splitted CAN-FD Msgs¡¯ CRC calculation, HS CAN ECUs should use source CAN-FD Msg¡¯s original STD ID. 

- The original STD ID can be read from Ext ID¡¯s 4~6th Byte.

Eg. STD 0x6AA : EXT SPLT 0x1A8[6AA]01 / 0x1A8[6AA]02 / 0x1A8[6AA]03 / 0x1A8[6AA]04 

(2~4th splitited Msgs can be omitted depending on source CAN-FD Msg¡¯s DLC)

- Aslo, HS-CAN ECUs should use merged data block (from whole splitted Msg) for CRC calculation.";
BA_ "GenSigSendType" SG_ 2315421697 CCU_AP_OTA_Crc1Val 4;
BA_ "GenSigStartValue" SG_ 2315421697 CCU_AP_OTA_Crc1Val 65535;
BA_ "UserSigValidity" SG_ 2315421697 CCU_AP_OTA_Crc1Val 3;
BA_REL_ "GenSigTimeoutTime" BU_SG_REL_ vDummy_HS_B SG_ 2315421697 CCU_AP_OTA_Crc1Val 1500;
BA_ "Version" SG_ 2315421697 CCU_AP_OTA_Crc1Val "21.09.03";
BA_ "Description" SG_ 2315421697 CCU_AP_OTA_AlvCnt1Val "For the first transmission request for a data element the counter shall be initialized with 0 and shall be incremented by 1 for every subsequent send request. 

When the counter reaches the maximum value(0xFF), then it shall restart with 0 for the next send request";
BA_ "GenSigSendType" SG_ 2315421697 CCU_AP_OTA_AlvCnt1Val 4;
BA_ "UserSigValidity" SG_ 2315421697 CCU_AP_OTA_AlvCnt1Val 3;
BA_REL_ "GenSigTimeoutTime" BU_SG_REL_ vDummy_HS_B SG_ 2315421697 CCU_AP_OTA_AlvCnt1Val 1500;
BA_ "Version" SG_ 2315421697 CCU_AP_OTA_AlvCnt1Val "21.09.03";
BA_ "GenSigSendType" SG_ 2315421697 CCU_OTA_mode 4;
BA_ "UserSigValidity" SG_ 2315421697 CCU_OTA_mode 0;
BA_ "Version" SG_ 2315421697 CCU_OTA_mode "20.01.01";
BA_ "GenSigSendType" SG_ 2315421697 CCU_OTA_IG3On_request 4;
BA_ "UserSigValidity" SG_ 2315421697 CCU_OTA_IG3On_request 0;
BA_ "Version" SG_ 2315421697 CCU_OTA_IG3On_request "20.01.02";
BA_ "GenSigSendType" SG_ 2315421697 OTA_Cond_Vehicle_Pwr 4;
BA_ "GenSigStartValue" SG_ 2315421697 OTA_Cond_Vehicle_Pwr 1;
BA_ "UserSigValidity" SG_ 2315421697 OTA_Cond_Vehicle_Pwr 0;
BA_ "Version" SG_ 2315421697 OTA_Cond_Vehicle_Pwr "20.11.03";
BA_ "GenSigSendType" SG_ 2315421697 OTA_Cond_Gear_P 4;
BA_ "GenSigStartValue" SG_ 2315421697 OTA_Cond_Gear_P 1;
BA_ "UserSigValidity" SG_ 2315421697 OTA_Cond_Gear_P 0;
BA_ "Version" SG_ 2315421697 OTA_Cond_Gear_P "20.11.03";
BA_ "GenSigSendType" SG_ 2315421697 OTA_Cond_Parking_Brk 4;
BA_ "GenSigStartValue" SG_ 2315421697 OTA_Cond_Parking_Brk 1;
BA_ "UserSigValidity" SG_ 2315421697 OTA_Cond_Parking_Brk 0;
BA_ "Version" SG_ 2315421697 OTA_Cond_Parking_Brk "20.11.03";
BA_ "GenSigSendType" SG_ 2315421697 OTA_Cond_Ext_Lamp 4;
BA_ "GenSigStartValue" SG_ 2315421697 OTA_Cond_Ext_Lamp 1;
BA_ "UserSigValidity" SG_ 2315421697 OTA_Cond_Ext_Lamp 0;
BA_ "Version" SG_ 2315421697 OTA_Cond_Ext_Lamp "20.11.03";
BA_ "GenSigSendType" SG_ 2315421697 OTA_Cond_Hood_Closed 4;
BA_ "GenSigStartValue" SG_ 2315421697 OTA_Cond_Hood_Closed 1;
BA_ "UserSigValidity" SG_ 2315421697 OTA_Cond_Hood_Closed 0;
BA_ "Version" SG_ 2315421697 OTA_Cond_Hood_Closed "20.11.03";
BA_ "Description" SG_ 2315421697 CCU_OTA_Cond_Request "Request for OTA Condition (to EPB, extLamp)";
BA_ "GenSigSendType" SG_ 2315421697 CCU_OTA_Cond_Request 4;
BA_ "UserSigValidity" SG_ 2315421697 CCU_OTA_Cond_Request 0;
BA_ "Version" SG_ 2315421697 CCU_OTA_Cond_Request "22.08.01";
BA_ "GenSigSendType" SG_ 2315421697 CCU_OTA_Tele_Cranking 4;
BA_ "UserSigValidity" SG_ 2315421697 CCU_OTA_Tele_Cranking 0;
BA_ "NetworkRequest" SG_ 2315421697 CCU_OTA_Tele_Cranking 0;
BA_ "NetworkRequestHoldingTime" SG_ 2315421697 CCU_OTA_Tele_Cranking 2000;
BA_ "Version" SG_ 2315421697 CCU_OTA_Tele_Cranking "22.02.02";
BA_ "Description" SG_ 2315421697 OTA_UI_Ready_request "OTA User Approval Popup Request Signal (to ccIC)";
BA_ "GenSigSendType" SG_ 2315421697 OTA_UI_Ready_request 4;
BA_ "UserSigValidity" SG_ 2315421697 OTA_UI_Ready_request 0;
BA_ "Version" SG_ 2315421697 OTA_UI_Ready_request "21.04.00";
BA_ "GenSigSendType" SG_ 2315421697 OTA_Result 4;
BA_ "UserSigValidity" SG_ 2315421697 OTA_Result 0;
BA_ "Version" SG_ 2315421697 OTA_Result "21.02.02";
BA_ "GenSigSendType" SG_ 2315421697 CF_AVN_InterAutoLockMode_Set2_Copy_1 4;
BA_ "UserSigValidity" SG_ 2315421697 CF_AVN_InterAutoLockMode_Set2_Copy_1 3;
BA_ "Version" SG_ 2315421697 CF_AVN_InterAutoLockMode_Set2_Copy_1 "20.09.00";
BA_ "GenSigSendType" SG_ 2315421697 CCU_OTA_EOU 4;
BA_ "UserSigValidity" SG_ 2315421697 CCU_OTA_EOU 0;
BA_ "Version" SG_ 2315421697 CCU_OTA_EOU "20.09.00";
BA_ "GenMsgSendType" BO_ 2290230529 0;
BA_ "GenMsgCycleTimeFast" BO_ 2290230529 0;
BA_ "GenMsgNrOfRepetition" BO_ 2290230529 0;
BA_ "VFrameFormat" BO_ 2290230529 1;
BA_ "Description" SG_ 2290230529 CLU_Crc2Val "The data area for CRC calculation is based on the data length (DLC) of the message DB.

The CRC shall be calculated over the entire data block (excluding the CRC bytes) including the user data, alive counter and Data ID



- CRC Polynomial (0x1021) , Initial Value : 0xFFFF, XOR value : 0x0000, Data ID : Message ID + 0xF800 

- The initial value is for CRC calculation and the message should be sent with the calculated result value. 

- The mathematical expression to 16 bit CRC polynomial is given here. G(x) = x16 + x12 + x5 + 1



<For CRC calculation of CAN-FD Msg for HS CAN domain ECUs>



- HS-CAN Messages that routed from CAN-FD domain are using 29 bit Extended CAN ID and splitted into 8 Byte Messages.

(from 1 to 4 Msgs, depending on source CAN-FD Msg¡¯s DLC)

- For splitted CAN-FD Msgs¡¯ CRC calculation, HS CAN ECUs should use source CAN-FD Msg¡¯s original STD ID. 

- The original STD ID can be read from Ext ID¡¯s 4~6th Byte.

Eg. STD 0x6AA : EXT SPLT 0x1A8[6AA]01 / 0x1A8[6AA]02 / 0x1A8[6AA]03 / 0x1A8[6AA]04 

(2~4th splitited Msgs can be omitted depending on source CAN-FD Msg¡¯s DLC)

- Aslo, HS-CAN ECUs should use merged data block (from whole splitted Msg) for CRC calculation.";
BA_ "GenSigStartValue" SG_ 2290230529 CLU_Crc2Val 65535;
BA_ "UserSigValidity" SG_ 2290230529 CLU_Crc2Val 3;
BA_ "RoutingFactor" SG_ 2290230529 CLU_Crc2Val 2;
BA_ "Version" SG_ 2290230529 CLU_Crc2Val "21.09.03";
BA_ "Description" SG_ 2290230529 CLU_AlvCnt2Val "For the first transmission request for a data element the counter shall be initialized with 0 and shall be incremented by 1 for every subsequent send request. 

When the counter reaches the maximum value(0xFF), then it shall restart with 0 for the next send request";
BA_ "UserSigValidity" SG_ 2290230529 CLU_AlvCnt2Val 3;
BA_ "RoutingFactor" SG_ 2290230529 CLU_AlvCnt2Val 2;
BA_ "Version" SG_ 2290230529 CLU_AlvCnt2Val "21.09.03";
BA_ "Description" SG_ 2290230529 CLU_DTEVal "This signal indicates DTE.

0x0: Valid DTE 0 (Display '---')

0x1~0xFFE: Valid DTE (1 ~ 4094 km)

(DTE >4094 km : 0xFFE)

0xFFF : Invalid(Display '---' Blink)";
BA_ "UserSigValidity" SG_ 2290230529 CLU_DTEVal 3;
BA_ "RoutingFactor" SG_ 2290230529 CLU_DTEVal 2;
BA_ "Version" SG_ 2290230529 CLU_DTEVal "19.02.07";
BA_ "Description" SG_ 2290230529 CLU_TripUnitSta "This signal indicates Distance to Empty UNIT";
BA_ "UserSigValidity" SG_ 2290230529 CLU_TripUnitSta 3;
BA_ "RoutingFactor" SG_ 2290230529 CLU_TripUnitSta 2;
BA_ "Version" SG_ 2290230529 CLU_TripUnitSta "17.11.00";
BA_ "Description" SG_ 2290230529 CLU_LoFuelWrngSta "This signal indicates that the Low fuel warning in the cluster is On or Off. When Low Fuel Warning is On, its value is 01H otherwise its value is 00H.";
BA_ "UserSigValidity" SG_ 2290230529 CLU_LoFuelWrngSta 3;
BA_ "RoutingFactor" SG_ 2290230529 CLU_LoFuelWrngSta 2;
BA_ "Version" SG_ 2290230529 CLU_LoFuelWrngSta "17.11.00";
BA_ "Description" SG_ 2290230529 CLU_RefuelDetSta "This signal sends the refuel detected status to the tele-matics control unit. 

It transfers 3 times during refuel detected event why if valid one is missing, valid signals are used for extra signal.";
BA_ "UserSigValidity" SG_ 2290230529 CLU_RefuelDetSta 3;
BA_ "RoutingFactor" SG_ 2290230529 CLU_RefuelDetSta 2;
BA_ "Version" SG_ 2290230529 CLU_RefuelDetSta "17.11.00";
BA_ "Description" SG_ 2290230529 CLU_TerrainMainSwSta "This signal represents the terrain mode main switch's state.

0x1:On-Road /0x2:Off-Road";
BA_ "UserSigValidity" SG_ 2290230529 CLU_TerrainMainSwSta 3;
BA_REL_ "GenSigTimeoutTime" BU_SG_REL_ FCS SG_ 2290230529 CLU_TerrainMainSwSta 1500;
BA_ "RoutingFactor" SG_ 2290230529 CLU_TerrainMainSwSta 2;
BA_ "Version" SG_ 2290230529 CLU_TerrainMainSwSta "18.04.00";
BA_ "GenMsgSendType" BO_ 2290230530 0;
BA_ "GenMsgCycleTimeFast" BO_ 2290230530 0;
BA_ "GenMsgNrOfRepetition" BO_ 2290230530 0;
BA_ "VFrameFormat" BO_ 2290230530 1;
BA_ "Description" SG_ 2290230530 CLU_RefuelWrnSta "This signal indicates that the Refuel popup is the cluster is On or Off.

When Refuel popup is on, its value is 0x1 otherwise its value is 0x0.";
BA_ "UserSigValidity" SG_ 2290230530 CLU_RefuelWrnSta 3;
BA_ "RoutingFactor" SG_ 2290230530 CLU_RefuelWrnSta 2;
BA_ "Version" SG_ 2290230530 CLU_RefuelWrnSta "17.11.00";
BA_ "Description" SG_ 2290230530 CLU_DrvngModSwSta "This signal occurs when drive mode switch is selected either 'Normal' or 'Eco' or 'Sport' or 'Sport+' or 'Smart' or 'Custom' or 'N-mode'.";
BA_ "UserSigValidity" SG_ 2290230530 CLU_DrvngModSwSta 3;
BA_REL_ "GenSigTimeoutTime" BU_SG_REL_ ALBCU SG_ 2290230530 CLU_DrvngModSwSta 1500;
BA_REL_ "GenSigTimeoutTime" BU_SG_REL_ GW_DLBCU SG_ 2290230530 CLU_DrvngModSwSta 1500;
BA_REL_ "GenSigTimeoutTime" BU_SG_REL_ SWRC SG_ 2290230530 CLU_DrvngModSwSta 1500;
BA_ "RoutingFactor" SG_ 2290230530 CLU_DrvngModSwSta 2;
BA_ "Version" SG_ 2290230530 CLU_DrvngModSwSta "20.04.02";
BA_ "Description" SG_ 2290230530 CLU_FuelLvlSta "The signal is fuel level of the cluster that fuel gauge indicate (Unit: %)";
BA_ "UserSigValidity" SG_ 2290230530 CLU_FuelLvlSta 3;
BA_ "RoutingFactor" SG_ 2290230530 CLU_FuelLvlSta 2;
BA_ "Version" SG_ 2290230530 CLU_FuelLvlSta "17.12.03";
BA_ "Description" SG_ 2290230530 CLU_SRSWrngLmpSta "This signal is generated by one of the following 5 self-diagnostic result of micro-controller of Cluster.

1) ¡°Lamp ON¡± status as a self-status diagnostic result of cluster

2) ¡°Lamp OFF¡± status as a self-status diagnostic result of cluster

3) ¡°Lamp flashing with 1hz frequency / 50% duty ratio¡± as a self-status result diagnostic result of cluster

4) ¡°Lamp Circuit Failure¡± as a self-diagnostic result of cluster circuit 

5) ¡°No Valid ACU message¡± as ACU4 message check result by cluster



Note to be taken that CLU2 message does not include judgment on ¡°SRS W/Lamp failure in terms of airbag system¡±. CLU2 message only contains ¡°status and diagnostic result of Cluster itself¡±.";
BA_ "GenSigStartValue" SG_ 2290230530 CLU_SRSWrngLmpSta 6;
BA_ "UserSigValidity" SG_ 2290230530 CLU_SRSWrngLmpSta 3;
BA_ "RoutingFactor" SG_ 2290230530 CLU_SRSWrngLmpSta 2;
BA_ "Version" SG_ 2290230530 CLU_SRSWrngLmpSta "22.04.01";
BA_ "Description" SG_ 2290230530 CLU_TerrainModSwSta "This signal occurs when terrain mode switch is selected either 'Snow' or 'Sand' or 'Mud' or 'Auto'.";
BA_ "UserSigValidity" SG_ 2290230530 CLU_TerrainModSwSta 3;
BA_REL_ "GenSigTimeoutTime" BU_SG_REL_ SWRC SG_ 2290230530 CLU_TerrainModSwSta 1500;
BA_ "RoutingFactor" SG_ 2290230530 CLU_TerrainModSwSta 2;
BA_ "Version" SG_ 2290230530 CLU_TerrainModSwSta "20.09.00";
BA_ "Description" SG_ 2290230530 CLU_OdoVal "This signal indicates mileage counter of a vehicle. Cluster calculates total mileage and sends it to SCC and CUBIS. This value shall be the same with the mileage that is displayed to a driver.";
BA_ "UserSigValidity" SG_ 2290230530 CLU_OdoVal 3;
BA_ "RoutingFactor" SG_ 2290230530 CLU_OdoVal 2;
BA_ "Version" SG_ 2290230530 CLU_OdoVal "17.11.00";
BA_ "GenMsgCycleTime" BO_ 2470763009 0;
BA_ "VFrameFormat" BO_ 2470763009 1;
BA_ "Description" SG_ 2470763009 CLU_Crc9Val "The data area for CRC calculation is based on the data length (DLC) of the message DB.

The CRC shall be calculated over the entire data block (excluding the CRC bytes) including the user data, alive counter and Data ID



- CRC Polynomial (0x1021) , Initial Value : 0xFFFF, XOR value : 0x0000, Data ID : Message ID + 0xF800 

- The initial value is for CRC calculation and the message should be sent with the calculated result value. 

- The mathematical expression to 16 bit CRC polynomial is given here. G(x) = x16 + x12 + x5 + 1



<For CRC calculation of CAN-FD Msg for HS CAN domain ECUs>



- HS-CAN Messages that routed from CAN-FD domain are using 29 bit Extended CAN ID and splitted into 8 Byte Messages.

(from 1 to 4 Msgs, depending on source CAN-FD Msg¡¯s DLC)

- For splitted CAN-FD Msgs¡¯ CRC calculation, HS CAN ECUs should use source CAN-FD Msg¡¯s original STD ID. 

- The original STD ID can be read from Ext ID¡¯s 4~6th Byte.

Eg. STD 0x6AA : EXT SPLT 0x1A8[6AA]01 / 0x1A8[6AA]02 / 0x1A8[6AA]03 / 0x1A8[6AA]04 

(2~4th splitited Msgs can be omitted depending on source CAN-FD Msg¡¯s DLC)

- Aslo, HS-CAN ECUs should use merged data block (from whole splitted Msg) for CRC calculation.";
BA_ "GenSigSendType" SG_ 2470763009 CLU_Crc9Val 4;
BA_ "GenSigStartValue" SG_ 2470763009 CLU_Crc9Val 65535;
BA_ "UserSigValidity" SG_ 2470763009 CLU_Crc9Val 3;
BA_ "Version" SG_ 2470763009 CLU_Crc9Val "21.09.03";
BA_ "Description" SG_ 2470763009 CLU_AlvCnt9Val "For the first transmission request for a data element the counter shall be initialized with 0 and shall be incremented by 1 for every subsequent send request. 

When the counter reaches the maximum value(0xFF), then it shall restart with 0 for the next send request";
BA_ "GenSigSendType" SG_ 2470763009 CLU_AlvCnt9Val 4;
BA_ "UserSigValidity" SG_ 2470763009 CLU_AlvCnt9Val 3;
BA_ "Version" SG_ 2470763009 CLU_AlvCnt9Val "21.09.03";
BA_ "Description" SG_ 2470763009 USM_MdLmpClrSetReq "Request set the Mood Lamp Color";
BA_ "GenSigSendType" SG_ 2470763009 USM_MdLmpClrSetReq 4;
BA_ "UserSigValidity" SG_ 2470763009 USM_MdLmpClrSetReq 3;
BA_ "Version" SG_ 2470763009 USM_MdLmpClrSetReq "20.08.06";
BA_ "Description" SG_ 2470763009 USM_RrWiperRevSetReq "Request to set RearWiper Reverse Mode";
BA_ "GenSigSendType" SG_ 2470763009 USM_RrWiperRevSetReq 4;
BA_ "UserSigValidity" SG_ 2470763009 USM_RrWiperRevSetReq 3;
BA_ "Version" SG_ 2470763009 USM_RrWiperRevSetReq "17.11.00";
BA_ "Description" SG_ 2470763009 USM_RrStRemindSetReq "USM Function for RearSeatReminder on/off SW";
BA_ "GenSigSendType" SG_ 2470763009 USM_RrStRemindSetReq 4;
BA_ "UserSigValidity" SG_ 2470763009 USM_RrStRemindSetReq 3;
BA_ "Version" SG_ 2470763009 USM_RrStRemindSetReq "19.01.04";
BA_ "Description" SG_ 2470763009 USM_RrWpcSetReq "USM Function for REAR WPC(Wireless Phone Chager) on/off SW";
BA_ "GenSigSendType" SG_ 2470763009 USM_RrWpcSetReq 4;
BA_ "UserSigValidity" SG_ 2470763009 USM_RrWpcSetReq 3;
BA_ "Version" SG_ 2470763009 USM_RrWpcSetReq "17.11.00";
BA_ "Description" SG_ 2470763009 USM_WpcSetReq "USM Function for WPC(Wireless Phone Chager) on/off SW";
BA_ "GenSigSendType" SG_ 2470763009 USM_WpcSetReq 4;
BA_ "UserSigValidity" SG_ 2470763009 USM_WpcSetReq 3;
BA_REL_ "GenSigTimeoutTime" BU_SG_REL_ WPC SG_ 2470763009 USM_WpcSetReq 0;
BA_REL_ "GenSigTimeoutTime" BU_SG_REL_ WPC2 SG_ 2470763009 USM_WpcSetReq 0;
BA_ "Version" SG_ 2470763009 USM_WpcSetReq "17.11.00";
BA_ "Description" SG_ 2470763009 USM_SeqLmpSetReq "This signal is used for a request to set the value of USM Menus. This signal requests to change status of SequencialLamp ON/OFF setting.





When this signal change, the message (CLU18) is sent 3 times.";
BA_ "GenSigSendType" SG_ 2470763009 USM_SeqLmpSetReq 4;
BA_ "UserSigValidity" SG_ 2470763009 USM_SeqLmpSetReq 3;
BA_ "Version" SG_ 2470763009 USM_SeqLmpSetReq "17.11.00";
BA_ "Description" SG_ 2470763009 USM_UnlckWlcmSetReq "This signal is used for a request to set the value of USM Menus. This signal requests to change status of Welcome System setting.





When this signal change, the message (CLU18) is sent 3 times.";
BA_ "GenSigSendType" SG_ 2470763009 USM_UnlckWlcmSetReq 4;
BA_ "UserSigValidity" SG_ 2470763009 USM_UnlckWlcmSetReq 3;
BA_ "Version" SG_ 2470763009 USM_UnlckWlcmSetReq "17.11.00";
BA_ "Description" SG_ 2470763009 USM_SmrtWlcmSetReq "This signal is used for a request to set the value of USM Menus. This signal requests to change status of Welcome System setting.





When this signal change, the message (CLU18) is sent 3 times.";
BA_ "GenSigSendType" SG_ 2470763009 USM_SmrtWlcmSetReq 4;
BA_ "UserSigValidity" SG_ 2470763009 USM_SmrtWlcmSetReq 3;
BA_ "Version" SG_ 2470763009 USM_SmrtWlcmSetReq "17.11.00";
BA_ "Description" SG_ 2470763009 USM_UipSetReq "Request to set Uip(Ultrasonic Intrusion Protection)

This signal is used for a request to set the value of USM Menus. 

When this signal change, the message is sent 3 times.";
BA_ "GenSigSendType" SG_ 2470763009 USM_UipSetReq 4;
BA_ "UserSigValidity" SG_ 2470763009 USM_UipSetReq 3;
BA_ "Version" SG_ 2470763009 USM_UipSetReq "18.11.07";
BA_ "Description" SG_ 2470763009 USM_DigitalKeyEnblSetReq "This signal is used for a request to set the value of USM Menus. This signal requests to set Digital Key On/Off.";
BA_ "GenSigSendType" SG_ 2470763009 USM_DigitalKeyEnblSetReq 4;
BA_ "UserSigValidity" SG_ 2470763009 USM_DigitalKeyEnblSetReq 3;
BA_ "Version" SG_ 2470763009 USM_DigitalKeyEnblSetReq "18.11.00";
BA_ "Description" SG_ 2470763009 USM_OwnerPhnRegSetReq "This signal is used for a request to set the value of USM Menus.

This signal requests to set Digital Key On/Off";
BA_ "GenSigSendType" SG_ 2470763009 USM_OwnerPhnRegSetReq 4;
BA_ "UserSigValidity" SG_ 2470763009 USM_OwnerPhnRegSetReq 3;
BA_ "Version" SG_ 2470763009 USM_OwnerPhnRegSetReq "18.11.00";
BA_ "Description" SG_ 2470763009 USM_NFCCard1RegSetReq "This signal is used for a request to set the value of USM Menus. This signal requests to go through the process for NFC Card 1 recoding.";
BA_ "GenSigSendType" SG_ 2470763009 USM_NFCCard1RegSetReq 4;
BA_ "UserSigValidity" SG_ 2470763009 USM_NFCCard1RegSetReq 3;
BA_ "Version" SG_ 2470763009 USM_NFCCard1RegSetReq "18.11.00";
BA_ "Description" SG_ 2470763009 USM_NFCCard2RegSetReq "This signal is used for arequest to set the value of usm menus.

This signal requests to go through the process NFC Card 2 recording";
BA_ "GenSigSendType" SG_ 2470763009 USM_NFCCard2RegSetReq 4;
BA_ "UserSigValidity" SG_ 2470763009 USM_NFCCard2RegSetReq 3;
BA_ "Version" SG_ 2470763009 USM_NFCCard2RegSetReq "18.11.00";
BA_ "Description" SG_ 2470763009 USM_ProcStpReq "This signal is used for a request to escape the IAU Authorizaton processing";
BA_ "GenSigSendType" SG_ 2470763009 USM_ProcStpReq 4;
BA_ "UserSigValidity" SG_ 2470763009 USM_ProcStpReq 3;
BA_ "Version" SG_ 2470763009 USM_ProcStpReq "18.11.00";
BA_ "Description" SG_ 2470763009 USM_PwrAutoOffTimeSetReq "This signal is used for a request to set the value of USM Menus. This signal requests to change status of Power auto off time setting.";
BA_ "GenSigSendType" SG_ 2470763009 USM_PwrAutoOffTimeSetReq 4;
BA_ "UserSigValidity" SG_ 2470763009 USM_PwrAutoOffTimeSetReq 3;
BA_ "Version" SG_ 2470763009 USM_PwrAutoOffTimeSetReq "18.12.02";
BA_ "Description" SG_ 2470763009 USM_RrStRemindSetReq_RestMode "This is a signal for Rear Seat remind USM 

Request to set  Restmod of Rear Seat remind";
BA_ "GenSigSendType" SG_ 2470763009 USM_RrStRemindSetReq_RestMode 4;
BA_ "UserSigValidity" SG_ 2470763009 USM_RrStRemindSetReq_RestMode 3;
BA_ "Version" SG_ 2470763009 USM_RrStRemindSetReq_RestMode "19.09.04";
BA_ "Description" SG_ 2470763009 USM_1stRrStRemindSetReq "USM Function for RearSeatReminder on/off SW for IBU only Type";
BA_ "GenSigSendType" SG_ 2470763009 USM_1stRrStRemindSetReq 4;
BA_ "UserSigValidity" SG_ 2470763009 USM_1stRrStRemindSetReq 3;
BA_ "Version" SG_ 2470763009 USM_1stRrStRemindSetReq "20.02.06";
BA_ "Description" SG_ 2470763009 USM_Wpc2SetReq "USM Function for WPC(Wireless Phone Chager) on/off SW";
BA_ "GenSigSendType" SG_ 2470763009 USM_Wpc2SetReq 4;
BA_ "UserSigValidity" SG_ 2470763009 USM_Wpc2SetReq 3;
BA_REL_ "GenSigTimeoutTime" BU_SG_REL_ WPC2 SG_ 2470763009 USM_Wpc2SetReq 0;
BA_ "Version" SG_ 2470763009 USM_Wpc2SetReq "22.02.06";
BA_ "GenMsgSendType" BO_ 2231452929 0;
BA_ "GenMsgCycleTime" BO_ 2231452929 100;
BA_ "GenMsgCycleTimeFast" BO_ 2231452929 0;
BA_ "GenMsgNrOfRepetition" BO_ 2231452929 0;
BA_ "VFrameFormat" BO_ 2231452929 1;
BA_ "Description" SG_ 2231452929 DATC_Crc1Val "The data area for CRC calculation is based on the data length (DLC) of the message DB.

The CRC shall be calculated over the entire data block (excluding the CRC bytes) including the user data, alive counter and Data ID



- CRC Polynomial (0x1021) , Initial Value : 0xFFFF, XOR value : 0x0000, Data ID : Message ID + 0xF800 

- The initial value is for CRC calculation and the message should be sent with the calculated result value. 

- The mathematical expression to 16 bit CRC polynomial is given here. G(x) = x16 + x12 + x5 + 1



<For CRC calculation of CAN-FD Msg for HS CAN domain ECUs>



- HS-CAN Messages that routed from CAN-FD domain are using 29 bit Extended CAN ID and splitted into 8 Byte Messages.

(from 1 to 4 Msgs, depending on source CAN-FD Msg¡¯s DLC)

- For splitted CAN-FD Msgs¡¯ CRC calculation, HS CAN ECUs should use source CAN-FD Msg¡¯s original STD ID. 

- The original STD ID can be read from Ext ID¡¯s 4~6th Byte.

Eg. STD 0x6AA : EXT SPLT 0x1A8[6AA]01 / 0x1A8[6AA]02 / 0x1A8[6AA]03 / 0x1A8[6AA]04 

(2~4th splitited Msgs can be omitted depending on source CAN-FD Msg¡¯s DLC)

- Aslo, HS-CAN ECUs should use merged data block (from whole splitted Msg) for CRC calculation.";
BA_ "GenSigStartValue" SG_ 2231452929 DATC_Crc1Val 65535;
BA_ "UserSigValidity" SG_ 2231452929 DATC_Crc1Val 7;
BA_ "RoutingFactor" SG_ 2231452929 DATC_Crc1Val 5;
BA_ "Version" SG_ 2231452929 DATC_Crc1Val "21.09.03";
BA_ "Description" SG_ 2231452929 DATC_AlvCnt1Val "For the first transmission request for a data element the counter shall be initialized with 0 and shall be incremented by 1 for every subsequent send request. 

When the counter reaches the maximum value(0xFF), then it shall restart with 0 for the next send request";
BA_ "UserSigValidity" SG_ 2231452929 DATC_AlvCnt1Val 7;
BA_ "RoutingFactor" SG_ 2231452929 DATC_AlvCnt1Val 5;
BA_ "Version" SG_ 2231452929 DATC_AlvCnt1Val "21.09.03";
BA_ "Description" SG_ 2231452929 DATC_PtcRlySta "This signal indicates PTC relay operation condition of gasoline engine. This signal is used for EMS to decide engine RPM up.";
BA_ "UserSigValidity" SG_ 2231452929 DATC_PtcRlySta 7;
BA_ "RoutingFactor" SG_ 2231452929 DATC_PtcRlySta 5;
BA_ "Version" SG_ 2231452929 DATC_PtcRlySta "17.11.00";
BA_ "Description" SG_ 2231452929 DATC_ManufacturerTyp "This signal FATC_ID identifies FATC Maker.";
BA_ "UserSigValidity" SG_ 2231452929 DATC_ManufacturerTyp 3;
BA_ "RoutingFactor" SG_ 2231452929 DATC_ManufacturerTyp 5;
BA_ "Version" SG_ 2231452929 DATC_ManufacturerTyp "17.11.00";
BA_ "Description" SG_ 2231452929 DATC_DatcPwmSts "This signal indicates operating status of E-comp.";
BA_ "UserSigValidity" SG_ 2231452929 DATC_DatcPwmSts 3;
BA_ "RoutingFactor" SG_ 2231452929 DATC_DatcPwmSts 5;
BA_ "Version" SG_ 2231452929 DATC_DatcPwmSts "18.09.00";
BA_ "Description" SG_ 2231452929 DATC_AcnCompTyp "Heater Control(FATC/MTC) information generated by HVAC Compressor type.";
BA_ "UserSigValidity" SG_ 2231452929 DATC_AcnCompTyp 3;
BA_ "RoutingFactor" SG_ 2231452929 DATC_AcnCompTyp 5;
BA_ "Version" SG_ 2231452929 DATC_AcnCompTyp "17.11.00";
BA_ "Description" SG_ 2231452929 DATC_EewpRpmLvlReq "EEWP Target RPM level



00h : MAX A/C

01h : Low

02h : Mid

03h : High";
BA_ "UserSigValidity" SG_ 2231452929 DATC_EewpRpmLvlReq 3;
BA_ "RoutingFactor" SG_ 2231452929 DATC_EewpRpmLvlReq 5;
BA_ "Version" SG_ 2231452929 DATC_EewpRpmLvlReq "17.11.00";
BA_ "Description" SG_ 2231452929 DATC_Cooldown "This signal indicates complete of cooldown.";
BA_ "UserSigValidity" SG_ 2231452929 DATC_Cooldown 3;
BA_ "RoutingFactor" SG_ 2231452929 DATC_Cooldown 5;
BA_ "Version" SG_ 2231452929 DATC_Cooldown "18.09.00";
BA_ "Description" SG_ 2231452929 DATC_AcnReq "This signal indicates A/C request switch by FATC

This signal occurs when A/C switch(button) is selected either manually or automatically.

EMS decides the torque compensation value to avoid torque shortage while A/C on";
BA_ "UserSigValidity" SG_ 2231452929 DATC_AcnReq 7;
BA_ "RoutingFactor" SG_ 2231452929 DATC_AcnReq 5;
BA_ "Version" SG_ 2231452929 DATC_AcnReq "17.11.00";
BA_ "Description" SG_ 2231452929 DATC_BlwSta "This signal indicates HVAC blower motor operation condition.

The signal is used for EMS to decide PTC on or manage battery level.";
BA_ "UserSigValidity" SG_ 2231452929 DATC_BlwSta 7;
BA_ "RoutingFactor" SG_ 2231452929 DATC_BlwSta 5;
BA_ "Version" SG_ 2231452929 DATC_BlwSta "17.11.00";
BA_ "Description" SG_ 2231452929 DATC_BlwMaxSta "This signal indicates that FATC operates HVAC blower by maximum speed.";
BA_ "UserSigValidity" SG_ 2231452929 DATC_BlwMaxSta 7;
BA_ "RoutingFactor" SG_ 2231452929 DATC_BlwMaxSta 5;
BA_ "Version" SG_ 2231452929 DATC_BlwMaxSta "17.11.00";
BA_ "Description" SG_ 2231452929 DATC_EngStrtReq "FATC requests Engine Auto Start to EMS by this signal during idle stop.";
BA_ "UserSigValidity" SG_ 2231452929 DATC_EngStrtReq 3;
BA_ "RoutingFactor" SG_ 2231452929 DATC_EngStrtReq 5;
BA_ "Version" SG_ 2231452929 DATC_EngStrtReq "17.11.00";
BA_ "Description" SG_ 2231452929 DATC_IsgInhbtReq "FATC requests EMS that ISG is prohibited (ISG function is not operating) by this signal.

FATC send the disable signal in the condition, for example HVAC Blower is Max.";
BA_ "UserSigValidity" SG_ 2231452929 DATC_IsgInhbtReq 3;
BA_ "RoutingFactor" SG_ 2231452929 DATC_IsgInhbtReq 5;
BA_ "Version" SG_ 2231452929 DATC_IsgInhbtReq "17.11.00";
BA_ "Description" SG_ 2231452929 DATC_AcnCompOnReq "FATC requests A/C compressor clutch on or off to EMS by this signal

This signal is off to maintain a/c refrigerant flow and air flow smoothly and avoid abnormal a/c compressor torque rising even though A/C request switch on, if the surface temperature of evaporator is below the certain icing temperature.";
BA_ "UserSigValidity" SG_ 2231452929 DATC_AcnCompOnReq 3;
BA_ "RoutingFactor" SG_ 2231452929 DATC_AcnCompOnReq 5;
BA_ "Version" SG_ 2231452929 DATC_AcnCompOnReq "17.11.00";
BA_ "Description" SG_ 2231452929 DATC_SrvLmpReq "This signal indicates request of service Lamp";
BA_ "UserSigValidity" SG_ 2231452929 DATC_SrvLmpReq 7;
BA_ "RoutingFactor" SG_ 2231452929 DATC_SrvLmpReq 5;
BA_ "Version" SG_ 2231452929 DATC_SrvLmpReq "19.08.04";
BA_ "Description" SG_ 2231452929 DATC_EcvFltSta "This signal indicates ECV control fault.

The detailed fault state is in the error identifiers of CR_Fatc_TqAcnOut signal";
BA_ "UserSigValidity" SG_ 2231452929 DATC_EcvFltSta 3;
BA_ "RoutingFactor" SG_ 2231452929 DATC_EcvFltSta 5;
BA_ "Version" SG_ 2231452929 DATC_EcvFltSta "17.11.00";
BA_ "Description" SG_ 2231452929 DATC_CalcAcnCompTqVal "This signal indicates the torque output of A/C compressor calculated by FATC.

EMS decides the torque compensation value or A/C compressor clutch disengagement (off) by receiving of this signal.";
BA_ "UserSigValidity" SG_ 2231452929 DATC_CalcAcnCompTqVal 3;
BA_ "RoutingFactor" SG_ 2231452929 DATC_CalcAcnCompTqVal 5;
BA_ "Version" SG_ 2231452929 DATC_CalcAcnCompTqVal "17.11.00";
BA_ "GenMsgSendType" BO_ 2231452930 0;
BA_ "GenMsgCycleTime" BO_ 2231452930 100;
BA_ "GenMsgCycleTimeFast" BO_ 2231452930 0;
BA_ "GenMsgNrOfRepetition" BO_ 2231452930 0;
BA_ "VFrameFormat" BO_ 2231452930 1;
BA_ "UserSigValidity" SG_ 2231452930 DATC_AcnECompOpSta 7;
BA_ "RoutingFactor" SG_ 2231452930 DATC_AcnECompOpSta 5;
BA_ "Version" SG_ 2231452930 DATC_AcnECompOpSta "17.11.00";
BA_ "UserSigValidity" SG_ 2231452930 DATC_HVCompIntlkSta 7;
BA_ "RoutingFactor" SG_ 2231452930 DATC_HVCompIntlkSta 5;
BA_ "Version" SG_ 2231452930 DATC_HVCompIntlkSta "17.11.00";
BA_ "Description" SG_ 2231452930 DATC_HVIntDischrgLkReq "This signal indicates forced discharge request when HV PTC Interlock or E-Compressor Interlock is open.";
BA_ "UserSigValidity" SG_ 2231452930 DATC_HVIntDischrgLkReq 7;
BA_ "RoutingFactor" SG_ 2231452930 DATC_HVIntDischrgLkReq 5;
BA_ "Version" SG_ 2231452930 DATC_HVIntDischrgLkReq "17.11.00";
BA_ "Description" SG_ 2231452930 DATC_AcnECompMaxReqPwrVal "0....20440[W] = 00H...3FEH (PH)= 20 * (HEX)[W]";
BA_ "UserSigValidity" SG_ 2231452930 DATC_AcnECompMaxReqPwrVal 7;
BA_ "RoutingFactor" SG_ 2231452930 DATC_AcnECompMaxReqPwrVal 5;
BA_ "Version" SG_ 2231452930 DATC_AcnECompMaxReqPwrVal "19.08.04";
BA_ "UserSigValidity" SG_ 2231452930 DATC_AcnCompFltSta 7;
BA_ "RoutingFactor" SG_ 2231452930 DATC_AcnCompFltSta 5;
BA_ "Version" SG_ 2231452930 DATC_AcnCompFltSta "17.11.00";
BA_ "Description" SG_ 2231452930 DATC_AcnECompCnsmptPwrVal "0¡¦20440[W] = 00H...3FEH (PH)= 20 * (HEX)[W]";
BA_ "UserSigValidity" SG_ 2231452930 DATC_AcnECompCnsmptPwrVal 7;
BA_ "RoutingFactor" SG_ 2231452930 DATC_AcnECompCnsmptPwrVal 5;
BA_ "Version" SG_ 2231452930 DATC_AcnECompCnsmptPwrVal "19.08.04";
BA_ "UserSigValidity" SG_ 2231452930 DATC_MainRlyOffReq 3;
BA_ "RoutingFactor" SG_ 2231452930 DATC_MainRlyOffReq 5;
BA_ "Version" SG_ 2231452930 DATC_MainRlyOffReq "17.11.00";
BA_ "Description" SG_ 2231452930 DATC_MixDfgSelSta "DATC will send this request signal to BMS when controlled in Mix/Def mode.";
BA_ "UserSigValidity" SG_ 2231452930 DATC_MixDfgSelSta 3;
BA_ "RoutingFactor" SG_ 2231452930 DATC_MixDfgSelSta 5;
BA_ "Version" SG_ 2231452930 DATC_MixDfgSelSta "17.11.00";
BA_ "Description" SG_ 2231452930 DATC_BattChlrVlvSta "Battery chiller valve status";
BA_ "UserSigValidity" SG_ 2231452930 DATC_BattChlrVlvSta 3;
BA_ "RoutingFactor" SG_ 2231452930 DATC_BattChlrVlvSta 5;
BA_ "Version" SG_ 2231452930 DATC_BattChlrVlvSta "22.04.02";
BA_ "UserSigValidity" SG_ 2231452930 DATC_WaterPmpOnReq 3;
BA_ "RoutingFactor" SG_ 2231452930 DATC_WaterPmpOnReq 5;
BA_ "Version" SG_ 2231452930 DATC_WaterPmpOnReq "17.11.00";
BA_ "Description" SG_ 2231452930 DATC_AcnECompSpdVal "0 ¡¦65534 [rpm] = 0000H ¡¦ FFFEH, (PH) = 1*(HEX) [rpm]";
BA_ "UserSigValidity" SG_ 2231452930 DATC_AcnECompSpdVal 7;
BA_ "RoutingFactor" SG_ 2231452930 DATC_AcnECompSpdVal 5;
BA_ "Version" SG_ 2231452930 DATC_AcnECompSpdVal "17.11.00";
BA_ "Description" SG_ 2231452930 DATC_AcnCompSlpModCodVal "(PH) = 1 * (HEX) [-]";
BA_ "UserSigValidity" SG_ 2231452930 DATC_AcnCompSlpModCodVal 7;
BA_ "RoutingFactor" SG_ 2231452930 DATC_AcnCompSlpModCodVal 5;
BA_ "Version" SG_ 2231452930 DATC_AcnCompSlpModCodVal "17.11.00";
BA_ "GenMsgSendType" BO_ 2231452931 0;
BA_ "GenMsgCycleTime" BO_ 2231452931 100;
BA_ "GenMsgCycleTimeFast" BO_ 2231452931 0;
BA_ "GenMsgNrOfRepetition" BO_ 2231452931 0;
BA_ "VFrameFormat" BO_ 2231452931 1;
BA_ "Description" SG_ 2231452931 DATC_AcnCompWaitCodVal "(PH) = 1 * (HEX) [-]";
BA_ "UserSigValidity" SG_ 2231452931 DATC_AcnCompWaitCodVal 7;
BA_ "RoutingFactor" SG_ 2231452931 DATC_AcnCompWaitCodVal 5;
BA_ "Version" SG_ 2231452931 DATC_AcnCompWaitCodVal "17.11.00";
BA_ "Description" SG_ 2231452931 DATC_PeEwpRPMReq "This signal indicates Cooling For High V Component (for A/C or Heatpump)

ÀüÀå¿ë ³Ã°¢¼ö¿ë, ÀüÀåÆó¿­À» ÀÌ¿ëÇÑ ¸®È÷ÆÃ¿ë";
BA_ "UserSigValidity" SG_ 2231452931 DATC_PeEwpRPMReq 3;
BA_ "RoutingFactor" SG_ 2231452931 DATC_PeEwpRPMReq 5;
BA_ "Version" SG_ 2231452931 DATC_PeEwpRPMReq "20.05.02";
BA_ "Description" SG_ 2231452931 DATC_AEwpSpdRpmReq "This signal indicates Request EWP speed to recover heat in HVAC System.(ENG COOLING ¿ë È¸·Î / È÷ÅÍÄÚ¾î ¿¬°ü)";
BA_ "UserSigValidity" SG_ 2231452931 DATC_AEwpSpdRpmReq 7;
BA_ "RoutingFactor" SG_ 2231452931 DATC_AEwpSpdRpmReq 5;
BA_ "Version" SG_ 2231452931 DATC_AEwpSpdRpmReq "17.11.00";
BA_ "Description" SG_ 2231452931 DATC_RadFanReq_Duty "This signal indicates Request cooling fan speed to cool HVAC System (Duty)

(0xFE value is only used to wake up EMS )";
BA_ "UserSigValidity" SG_ 2231452931 DATC_RadFanReq_Duty 5;
BA_ "RoutingFactor" SG_ 2231452931 DATC_RadFanReq_Duty 5;
BA_ "Version" SG_ 2231452931 DATC_RadFanReq_Duty "20.02.05";
BA_ "Description" SG_ 2231452931 DATC_OutTempSnsrVal "Actual temperature of Ambient Sensor via an A/D converter; converted into degrees

centigrade (¡É).

This is raw data of ambient sensor; just transferred from Ambient Sensor Voltage.";
BA_ "UserSigValidity" SG_ 2231452931 DATC_OutTempSnsrVal 7;
BA_REL_ "GenSigTimeoutTime" BU_SG_REL_ RCM SG_ 2231452931 DATC_OutTempSnsrVal 1500;
BA_ "RoutingFactor" SG_ 2231452931 DATC_OutTempSnsrVal 5;
BA_ "Version" SG_ 2231452931 DATC_OutTempSnsrVal "21.07.06";
BA_ "Description" SG_ 2231452931 DATC_ActvEco "This signal indicates the operating condition (ON or OFF) of Active ECO Button.";
BA_ "UserSigValidity" SG_ 2231452931 DATC_ActvEco 7;
BA_ "RoutingFactor" SG_ 2231452931 DATC_ActvEco 5;
BA_ "Version" SG_ 2231452931 DATC_ActvEco "17.11.00";
BA_ "Description" SG_ 2231452931 DATC_AUTOActv "As soon as FATC receive activation message from TMU, 

For 5 Seconds, FATC Send The massage ¡° Automatic control is Active(01H) ¡° and 

control 23¡É Auto.

After 5 seconds FATC send the initial value(00H) massage";
BA_ "UserSigValidity" SG_ 2231452931 DATC_AUTOActv 7;
BA_ "RoutingFactor" SG_ 2231452931 DATC_AUTOActv 5;
BA_ "Version" SG_ 2231452931 DATC_AUTOActv "17.11.00";
BA_ "Description" SG_ 2231452931 DATC_DfgSw "This signal indicates whether FRONT DEF switch is selected or not.";
BA_ "UserSigValidity" SG_ 2231452931 DATC_DfgSw 7;
BA_ "RoutingFactor" SG_ 2231452931 DATC_DfgSw 5;
BA_ "Version" SG_ 2231452931 DATC_DfgSw "17.11.00";
BA_ "Description" SG_ 2231452931 DATC_BattChlrVlv_FltCode "Battery Chiller Filt Code";
BA_ "UserSigValidity" SG_ 2231452931 DATC_BattChlrVlv_FltCode 3;
BA_ "RoutingFactor" SG_ 2231452931 DATC_BattChlrVlv_FltCode 5;
BA_ "Version" SG_ 2231452931 DATC_BattChlrVlv_FltCode "18.09.00";
BA_ "Description" SG_ 2231452931 DATC_BattEvapVlvSta "BATTERY COOL V/V (EVAP) STATUS";
BA_ "UserSigValidity" SG_ 2231452931 DATC_BattEvapVlvSta 5;
BA_ "RoutingFactor" SG_ 2231452931 DATC_BattEvapVlvSta 5;
BA_ "Version" SG_ 2231452931 DATC_BattEvapVlvSta "18.09.00";
BA_ "Description" SG_ 2231452931 DATC_BattEvapVlv_FltCode "BATTERY COOL V/V (EVAP) FltCode";
BA_ "UserSigValidity" SG_ 2231452931 DATC_BattEvapVlv_FltCode 5;
BA_ "RoutingFactor" SG_ 2231452931 DATC_BattEvapVlv_FltCode 5;
BA_ "Version" SG_ 2231452931 DATC_BattEvapVlv_FltCode "18.09.00";
BA_ "Description" SG_ 2231452931 DATC_Wrmup "This signal indicates complete of warmup";
BA_ "UserSigValidity" SG_ 2231452931 DATC_Wrmup 5;
BA_ "RoutingFactor" SG_ 2231452931 DATC_Wrmup 5;
BA_ "Version" SG_ 2231452931 DATC_Wrmup "18.09.00";
BA_ "Description" SG_ 2231452931 DATC_SSC_EngStrtReq "Engine start request in SSC state";
BA_ "UserSigValidity" SG_ 2231452931 DATC_SSC_EngStrtReq 3;
BA_ "RoutingFactor" SG_ 2231452931 DATC_SSC_EngStrtReq 5;
BA_ "Version" SG_ 2231452931 DATC_SSC_EngStrtReq "19.04.00";
BA_ "GenMsgSendType" BO_ 2231452932 0;
BA_ "GenMsgCycleTime" BO_ 2231452932 100;
BA_ "GenMsgCycleTimeFast" BO_ 2231452932 0;
BA_ "GenMsgNrOfRepetition" BO_ 2231452932 0;
BA_ "VFrameFormat" BO_ 2231452932 1;
BA_ "Description" SG_ 2231452932 DATC_SSC_InhbtReq "Request to EMS not to enter SSC";
BA_ "UserSigValidity" SG_ 2231452932 DATC_SSC_InhbtReq 3;
BA_ "RoutingFactor" SG_ 2231452932 DATC_SSC_InhbtReq 5;
BA_ "Version" SG_ 2231452932 DATC_SSC_InhbtReq "19.04.00";
BA_ "Description" SG_ 2231452932 DATC_EngIdlRpmUpReq "This signal is information of A/C Comp_Load by FATC.";
BA_ "UserSigValidity" SG_ 2231452932 DATC_EngIdlRpmUpReq 3;
BA_ "RoutingFactor" SG_ 2231452932 DATC_EngIdlRpmUpReq 5;
BA_ "Version" SG_ 2231452932 DATC_EngIdlRpmUpReq "20.07.12";
BA_ "Description" SG_ 2231452932 DATC_MaxBlwVolt "Max blower voltage that only B+ status send to LDC";
BA_ "UserSigValidity" SG_ 2231452932 DATC_MaxBlwVolt 7;
BA_ "RoutingFactor" SG_ 2231452932 DATC_MaxBlwVolt 5;
BA_ "Version" SG_ 2231452932 DATC_MaxBlwVolt "20.05.01";
BA_ "Description" SG_ 2231452932 DATC_HVACPmpOpSta "HVAC Pump Operation Status";
BA_ "UserSigValidity" SG_ 2231452932 DATC_HVACPmpOpSta 3;
BA_ "RoutingFactor" SG_ 2231452932 DATC_HVACPmpOpSta 5;
BA_ "Version" SG_ 2231452932 DATC_HVACPmpOpSta "18.09.00";
BA_ "Description" SG_ 2231452932 DATC_MildCooldown "Mild Cooldown State";
BA_ "UserSigValidity" SG_ 2231452932 DATC_MildCooldown 7;
BA_ "RoutingFactor" SG_ 2231452932 DATC_MildCooldown 5;
BA_ "Version" SG_ 2231452932 DATC_MildCooldown "18.10.06";
BA_ "Description" SG_ 2231452932 DATC_MildWrmup "Mild Warmup State";
BA_ "UserSigValidity" SG_ 2231452932 DATC_MildWrmup 5;
BA_ "RoutingFactor" SG_ 2231452932 DATC_MildWrmup 5;
BA_ "Version" SG_ 2231452932 DATC_MildWrmup "18.09.00";
BA_ "Description" SG_ 2231452932 DATC_BlwrLvl "This signal indicates step of Front blower operation .";
BA_ "UserSigValidity" SG_ 2231452932 DATC_BlwrLvl 7;
BA_ "RoutingFactor" SG_ 2231452932 DATC_BlwrLvl 5;
BA_ "Version" SG_ 2231452932 DATC_BlwrLvl "18.10.06";
BA_ "Description" SG_ 2231452932 DATC_AAFOpenReq "Open Reqest Active Air Flap(AAF) before Compressor max rpm";
BA_ "UserSigValidity" SG_ 2231452932 DATC_AAFOpenReq 7;
BA_ "RoutingFactor" SG_ 2231452932 DATC_AAFOpenReq 5;
BA_ "Version" SG_ 2231452932 DATC_AAFOpenReq "19.06.03";
BA_ "Description" SG_ 2231452932 DATC_BlwSta_Rr "This signal indicates HVAC blower motor operation condition for rear seat.";
BA_ "UserSigValidity" SG_ 2231452932 DATC_BlwSta_Rr 7;
BA_ "RoutingFactor" SG_ 2231452932 DATC_BlwSta_Rr 5;
BA_ "Version" SG_ 2231452932 DATC_BlwSta_Rr "22.11.03";
BA_ "Description" SG_ 2231452932 DATC_BattEwpOpReq "This signal requests the operation of BATT EWP for heat recovery technique.";
BA_ "UserSigValidity" SG_ 2231452932 DATC_BattEwpOpReq 5;
BA_ "RoutingFactor" SG_ 2231452932 DATC_BattEwpOpReq 5;
BA_ "Version" SG_ 2231452932 DATC_BattEwpOpReq "18.12.03";
BA_ "GenMsgSendType" BO_ 2382594561 0;
BA_ "VFrameFormat" BO_ 2382594561 1;
BA_ "Description" SG_ 2382594561 DATC_Crc5Val "The data area for CRC calculation is based on the data length (DLC) of the message DB.

The CRC shall be calculated over the entire data block (excluding the CRC bytes) including the user data, alive counter and Data ID



- CRC Polynomial (0x1021) , Initial Value : 0xFFFF, XOR value : 0x0000, Data ID : Message ID + 0xF800 

- The initial value is for CRC calculation and the message should be sent with the calculated result value. 

- The mathematical expression to 16 bit CRC polynomial is given here. G(x) = x16 + x12 + x5 + 1



<For CRC calculation of CAN-FD Msg for HS CAN domain ECUs>



- HS-CAN Messages that routed from CAN-FD domain are using 29 bit Extended CAN ID and splitted into 8 Byte Messages.

(from 1 to 4 Msgs, depending on source CAN-FD Msg¡¯s DLC)

- For splitted CAN-FD Msgs¡¯ CRC calculation, HS CAN ECUs should use source CAN-FD Msg¡¯s original STD ID. 

- The original STD ID can be read from Ext ID¡¯s 4~6th Byte.

Eg. STD 0x6AA : EXT SPLT 0x1A8[6AA]01 / 0x1A8[6AA]02 / 0x1A8[6AA]03 / 0x1A8[6AA]04 

(2~4th splitited Msgs can be omitted depending on source CAN-FD Msg¡¯s DLC)

- Aslo, HS-CAN ECUs should use merged data block (from whole splitted Msg) for CRC calculation.";
BA_ "GenSigSendType" SG_ 2382594561 DATC_Crc5Val 4;
BA_ "GenSigStartValue" SG_ 2382594561 DATC_Crc5Val 65535;
BA_ "UserSigValidity" SG_ 2382594561 DATC_Crc5Val 3;
BA_ "Version" SG_ 2382594561 DATC_Crc5Val "21.09.03";
BA_ "Description" SG_ 2382594561 DATC_AlvCnt5Val "For the first transmission request for a data element the counter shall be initialized with 0 and shall be incremented by 1 for every subsequent send request. 

When the counter reaches the maximum value(0xFF), then it shall restart with 0 for the next send request";
BA_ "GenSigSendType" SG_ 2382594561 DATC_AlvCnt5Val 4;
BA_ "UserSigValidity" SG_ 2382594561 DATC_AlvCnt5Val 3;
BA_ "Version" SG_ 2382594561 DATC_AlvCnt5Val "21.09.03";
BA_ "Description" SG_ 2382594561 DATC_FrDrvModDis "This signal indicates MODE of HTR Control (VENT, B/L, FLOOR, MIX, DEF, AUTO Defog).

This signal occurs when MODE switch(button) is selected either manually or automatically.";
BA_ "GenSigSendType" SG_ 2382594561 DATC_FrDrvModDis 4;
BA_ "UserSigValidity" SG_ 2382594561 DATC_FrDrvModDis 7;
BA_REL_ "GenSigTimeoutTime" BU_SG_REL_ ATS SG_ 2382594561 DATC_FrDrvModDis 1500;
BA_ "Version" SG_ 2382594561 DATC_FrDrvModDis "18.11.06";
BA_ "Description" SG_ 2382594561 DATC_FrPassModDis "This signal indicates Passenger MODE of HTR Control

 (VENT, B/L, FLOOR, MIX, DEF, AUTO Defog)

This signal occurs when MODE switch(button) is selected either manually or automatically";
BA_ "GenSigSendType" SG_ 2382594561 DATC_FrPassModDis 4;
BA_ "UserSigValidity" SG_ 2382594561 DATC_FrPassModDis 7;
BA_REL_ "GenSigTimeoutTime" BU_SG_REL_ ATS SG_ 2382594561 DATC_FrPassModDis 1500;
BA_ "Version" SG_ 2382594561 DATC_FrPassModDis "18.11.05";
BA_ "Description" SG_ 2382594561 DATC_ClmtTxtPopupOSD "Climate Text Pop-up OSD";
BA_ "GenSigSendType" SG_ 2382594561 DATC_ClmtTxtPopupOSD 4;
BA_ "TimeoutValue" SG_ 2382594561 DATC_ClmtTxtPopupOSD "0x0";
BA_ "UserSigValidity" SG_ 2382594561 DATC_ClmtTxtPopupOSD 7;
BA_REL_ "GenSigTimeoutTime" BU_SG_REL_ ATS SG_ 2382594561 DATC_ClmtTxtPopupOSD 1500;
BA_ "Version" SG_ 2382594561 DATC_ClmtTxtPopupOSD "21.04.10";
BA_ "Description" SG_ 2382594561 DATC_TempDispUnitSta "This signal indicates Temp unit of HTR Control (¡É, ¢µ).";
BA_ "GenSigSendType" SG_ 2382594561 DATC_TempDispUnitSta 4;
BA_ "UserSigValidity" SG_ 2382594561 DATC_TempDispUnitSta 6;
BA_REL_ "GenSigTimeoutTime" BU_SG_REL_ ATS SG_ 2382594561 DATC_TempDispUnitSta 1500;
BA_ "Version" SG_ 2382594561 DATC_TempDispUnitSta "17.11.00";
BA_ "Description" SG_ 2382594561 DATC_DrvAutoDis "This signal indicates AUTO Graphic On & Off.

This signal occurs when AUTO switch(button) is selected either manually or automatically.";
BA_ "GenSigSendType" SG_ 2382594561 DATC_DrvAutoDis 4;
BA_ "UserSigValidity" SG_ 2382594561 DATC_DrvAutoDis 6;
BA_REL_ "GenSigTimeoutTime" BU_SG_REL_ ATS SG_ 2382594561 DATC_DrvAutoDis 1500;
BA_ "Version" SG_ 2382594561 DATC_DrvAutoDis "17.11.00";
BA_ "Description" SG_ 2382594561 DATC_FrChgReqDis "This signal indicates to show Climate Pop-up screen.

This signal occurs when any kinds of climate switch(button)s are selected manually.";
BA_ "GenSigSendType" SG_ 2382594561 DATC_FrChgReqDis 4;
BA_ "UserSigValidity" SG_ 2382594561 DATC_FrChgReqDis 6;
BA_ "Version" SG_ 2382594561 DATC_FrChgReqDis "17.11.00";
BA_ "Description" SG_ 2382594561 DATC_FrClmtScrnDis "This signal indicates that screen change to Climate Full screen.



This signal occurs when Climate switch(button) is selected manually.";
BA_ "GenSigSendType" SG_ 2382594561 DATC_FrClmtScrnDis 4;
BA_ "UserSigValidity" SG_ 2382594561 DATC_FrClmtScrnDis 6;
BA_REL_ "GenSigTimeoutTime" BU_SG_REL_ ATS SG_ 2382594561 DATC_FrClmtScrnDis 1500;
BA_ "Version" SG_ 2382594561 DATC_FrClmtScrnDis "17.11.00";
BA_ "Description" SG_ 2382594561 DATC_AcDis "This signal indicates A/C Graphic On & Off.

This signal occurs when A/C switch(button) is selected either manually or automatically.";
BA_ "GenSigSendType" SG_ 2382594561 DATC_AcDis 4;
BA_ "UserSigValidity" SG_ 2382594561 DATC_AcDis 6;
BA_REL_ "GenSigTimeoutTime" BU_SG_REL_ ATS SG_ 2382594561 DATC_AcDis 1500;
BA_ "Version" SG_ 2382594561 DATC_AcDis "17.11.00";
BA_ "Description" SG_ 2382594561 DATC_IntakeSta "This signal indicates Intake status (REC or FRE).";
BA_ "GenSigSendType" SG_ 2382594561 DATC_IntakeSta 4;
BA_ "UserSigValidity" SG_ 2382594561 DATC_IntakeSta 7;
BA_ "Version" SG_ 2382594561 DATC_IntakeSta "17.11.00";
BA_ "Description" SG_ 2382594561 DATC_TempDrLvl "This signal indicates level of temp door.";
BA_ "GenSigSendType" SG_ 2382594561 DATC_TempDrLvl 4;
BA_ "UserSigValidity" SG_ 2382594561 DATC_TempDrLvl 3;
BA_ "Version" SG_ 2382594561 DATC_TempDrLvl "18.09.00";
BA_ "Description" SG_ 2382594561 DATC_BattCompPwrCnsmptn_W "This signal indicates consumption power by e-compressor for battery";
BA_ "GenSigSendType" SG_ 2382594561 DATC_BattCompPwrCnsmptn_W 4;
BA_ "UserSigValidity" SG_ 2382594561 DATC_BattCompPwrCnsmptn_W 5;
BA_ "Version" SG_ 2382594561 DATC_BattCompPwrCnsmptn_W "18.09.00";
BA_ "GenMsgCycleTime" BO_ 649 0;
BA_ "Description" SG_ 649 DLBCU_SmartCtrl_1h "½º¸¶Æ® ÀÚ¼¼Á¦¾î DLBCU ¿¬µ¿ Á¶Àý¿¡ µû¸¥ °³¼±ÇöÈ² AVN Ç¥½Ã¹®±¸_1½Ã°£";
BA_ "GenSigSendType" SG_ 649 DLBCU_SmartCtrl_1h 4;
BA_ "UserSigValidity" SG_ 649 DLBCU_SmartCtrl_1h 1;
BA_REL_ "GenSigTimeoutTime" BU_SG_REL_ CGW_CCU SG_ 649 DLBCU_SmartCtrl_1h 0;
BA_ "Version" SG_ 649 DLBCU_SmartCtrl_1h "21.07.06";
BA_ "Description" SG_ 649 DLBCU_SmartCtrl_2h "½º¸¶Æ® ÀÚ¼¼Á¦¾î DLBCU ¿¬µ¿ Á¶Àý¿¡ µû¸¥ °³¼±ÇöÈ² AVN Ç¥½Ã ¹®±¸_2½Ã°£";
BA_ "GenSigSendType" SG_ 649 DLBCU_SmartCtrl_2h 4;
BA_ "UserSigValidity" SG_ 649 DLBCU_SmartCtrl_2h 1;
BA_REL_ "GenSigTimeoutTime" BU_SG_REL_ CGW_CCU SG_ 649 DLBCU_SmartCtrl_2h 0;
BA_ "Version" SG_ 649 DLBCU_SmartCtrl_2h "21.07.06";
BA_ "Description" SG_ 649 DLBCU_SmartCtrl_Status "½º¸¶Æ® ÀÚ¼¼Á¦¾î 2´Ü°è DLBCU ¿¬µ¿ Á¶Àý µ¿ÀÛ ½ÃÀÛ / Á¾·á / Áß´Ü AVN ÆË¾÷";
BA_ "GenSigSendType" SG_ 649 DLBCU_SmartCtrl_Status 4;
BA_ "UserSigValidity" SG_ 649 DLBCU_SmartCtrl_Status 1;
BA_REL_ "GenSigTimeoutTime" BU_SG_REL_ CGW_CCU SG_ 649 DLBCU_SmartCtrl_Status 0;
BA_ "Version" SG_ 649 DLBCU_SmartCtrl_Status "21.07.06";
BA_ "GenMsgSendType" BO_ 2176872449 0;
BA_ "GenMsgCycleTime" BO_ 2176872449 50;
BA_ "GenMsgCycleTimeFast" BO_ 2176872449 0;
BA_ "GenMsgNrOfRepetition" BO_ 2176872449 0;
BA_ "VFrameFormat" BO_ 2176872449 1;
BA_ "Description" SG_ 2176872449 HTCU_Crc5Val "The data area for CRC calculation is based on the data length (DLC) of the message DB.

The CRC shall be calculated over the entire data block (excluding the CRC bytes) including the user data, alive counter and Data ID

 

- CRC Polynomial (0x1021) , Initial Value : 0xFFFF, XOR value : 0x0000, Data ID : Message ID + 0xF800 

- The initial value is for CRC calculation and the message should be sent with the calculated result value. 

- The mathematical expression to 16 bit CRC polynomial is given here. G(x) = x16 + x12 + x5 + 1";
BA_ "GenSigStartValue" SG_ 2176872449 HTCU_Crc5Val 65535;
BA_ "UserSigValidity" SG_ 2176872449 HTCU_Crc5Val 3;
BA_ "RoutingFactor" SG_ 2176872449 HTCU_Crc5Val 5;
BA_ "Version" SG_ 2176872449 HTCU_Crc5Val "19.10.00";
BA_ "Description" SG_ 2176872449 HTCU_AlvCnt5Val "For the first transmission request for a data element the counter shall be initialized with 0 and shall be incremented by 1 for every subsequent send request. 

When the counter reaches the maximum value(0xFF), then it shall restart with 0 for the next send request";
BA_ "UserSigValidity" SG_ 2176872449 HTCU_AlvCnt5Val 3;
BA_ "RoutingFactor" SG_ 2176872449 HTCU_AlvCnt5Val 5;
BA_ "Version" SG_ 2176872449 HTCU_AlvCnt5Val "19.10.00";
BA_ "Description" SG_ 2176872449 HDCT_AddtnlTqLssVal "Additional torque loss";
BA_ "UserSigValidity" SG_ 2176872449 HDCT_AddtnlTqLssVal 3;
BA_ "RoutingFactor" SG_ 2176872449 HDCT_AddtnlTqLssVal 5;
BA_ "Version" SG_ 2176872449 HDCT_AddtnlTqLssVal "19.10.01";
BA_ "Description" SG_ 2176872449 HDCT_OBDSta "The signal HDCT_ObdSta is used to inform the OBD master (EMS-ECU) in case a OBD relevant fault is detected. According to the OBD regulations the HTCU could request MIL on, MIL blinking and freeze frame storage. If a freeze frame request by the HTCU has not been acknowledged (CF_Ems_ObdFrfAck) within 2 seconds, this request has to be canceled.

Value description

Bit 0: readiness info / Bit 1: freeze frame request / Bit 2: MIL on request / Bit3: MIL blinking request";
BA_ "UserSigValidity" SG_ 2176872449 HDCT_OBDSta 3;
BA_ "RoutingFactor" SG_ 2176872449 HDCT_OBDSta 5;
BA_ "Version" SG_ 2176872449 HDCT_OBDSta "19.10.01";
BA_ "Description" SG_ 2176872449 HDCT_OBDErrSta "Informs about the presence of an OBD-relevant error in the HTCU.

When an OBD-relevant error detected HDCT_ObdErrSta is set to 1 and the related DTC(s) would be recorded into non-volatile memory. Even if the error is not detected currently, HDCT_ObdErrSta should be set to 1 as long as DTC exists in memory.";
BA_ "UserSigValidity" SG_ 2176872449 HDCT_OBDErrSta 3;
BA_ "RoutingFactor" SG_ 2176872449 HDCT_OBDErrSta 5;
BA_ "Version" SG_ 2176872449 HDCT_OBDErrSta "19.10.01";
BA_ "Description" SG_ 2176872449 HDCT_StcShftLrchCtrl "Static shift DR or RD lurch control";
BA_ "UserSigValidity" SG_ 2176872449 HDCT_StcShftLrchCtrl 3;
BA_ "RoutingFactor" SG_ 2176872449 HDCT_StcShftLrchCtrl 5;
BA_ "Version" SG_ 2176872449 HDCT_StcShftLrchCtrl "19.10.01";
BA_ "Description" SG_ 2176872449 HDCT_EngCltchLmphmMod "Engine clutch limp-home control activation";
BA_ "UserSigValidity" SG_ 2176872449 HDCT_EngCltchLmphmMod 3;
BA_ "RoutingFactor" SG_ 2176872449 HDCT_EngCltchLmphmMod 5;
BA_ "Version" SG_ 2176872449 HDCT_EngCltchLmphmMod "19.10.01";
BA_ "UserSigValidity" SG_ 2176872449 HDCT_CurrPrgrm 3;
BA_ "RoutingFactor" SG_ 2176872449 HDCT_CurrPrgrm 5;
BA_ "Version" SG_ 2176872449 HDCT_CurrPrgrm "19.10.01";
BA_ "Description" SG_ 2176872449 HDCT_FltSta "informs about status of transmission control.



<Value Description>

Bit 0: TCU Diagnostic failure

Bit 1: TCU Diagnostic failure ? Limphome activated

Bit 2: OPU/EOP Diagnostic failure";
BA_ "UserSigValidity" SG_ 2176872449 HDCT_FltSta 3;
BA_ "RoutingFactor" SG_ 2176872449 HDCT_FltSta 5;
BA_ "Version" SG_ 2176872449 HDCT_FltSta "20.02.00";
BA_ "Description" SG_ 2176872449 HDCT_MCUAntJrkInhbt "MCU anti-jerk inhibition";
BA_ "UserSigValidity" SG_ 2176872449 HDCT_MCUAntJrkInhbt 3;
BA_ "RoutingFactor" SG_ 2176872449 HDCT_MCUAntJrkInhbt 5;
BA_ "Version" SG_ 2176872449 HDCT_MCUAntJrkInhbt "19.10.01";
BA_ "Description" SG_ 2176872449 HDCT_TrgtGear "HTCU_TrgtGearSta informs about the speed, which is currently engaged in the gearbox, or, in case of a gear change (HTCU_GearChgSta), which speed is reached.

Note: Gear changes covering more than one speed are also possible.

In the P and N positions, the frictional connection is interrupted hydraulically.

Depending on the type of error, the 3rd or 4th (forward) speed, and the R (reverse) speed are engaged in the limp home program.";
BA_ "UserSigValidity" SG_ 2176872449 HDCT_TrgtGear 3;
BA_ "RoutingFactor" SG_ 2176872449 HDCT_TrgtGear 5;
BA_ "Version" SG_ 2176872449 HDCT_TrgtGear "19.10.01";
BA_ "Description" SG_ 2176872449 HDCT_CurrGear "CUR_GR indicates the gear speed which is currently engaged in the gearbox.";
BA_ "UserSigValidity" SG_ 2176872449 HDCT_CurrGear 3;
BA_ "RoutingFactor" SG_ 2176872449 HDCT_CurrGear 5;
BA_ "Version" SG_ 2176872449 HDCT_CurrGear "19.10.01";
BA_ "Description" SG_ 2176872449 HDCT_GearSelDis "Position (P, R, N..), which was identified by the gear selector.

In case the gear selector is in a intermediate position, the last clear recognized position is used.

There is no specific phase relationship between the output and any other signal.";
BA_ "GenSigStartValue" SG_ 2176872449 HDCT_GearSelDis 9;
BA_ "UserSigValidity" SG_ 2176872449 HDCT_GearSelDis 3;
BA_ "RoutingFactor" SG_ 2176872449 HDCT_GearSelDis 5;
BA_ "Version" SG_ 2176872449 HDCT_GearSelDis "19.10.01";
BA_ "GenMsgSendType" BO_ 2176872452 0;
BA_ "GenMsgCycleTime" BO_ 2176872452 50;
BA_ "GenMsgCycleTimeFast" BO_ 2176872452 0;
BA_ "GenMsgNrOfRepetition" BO_ 2176872452 0;
BA_ "VFrameFormat" BO_ 2176872452 1;
BA_ "GenMsgSendType" BO_ 2172675329 0;
BA_ "GenMsgCycleTime" BO_ 2172675329 50;
BA_ "GenMsgCycleTimeFast" BO_ 2172675329 0;
BA_ "GenMsgNrOfRepetition" BO_ 2172675329 0;
BA_ "VFrameFormat" BO_ 2172675329 1;
BA_ "Description" SG_ 2172675329 IEB_Crc1Val "The data area for CRC calculation is based on the data length (DLC) of the message DB.

The CRC shall be calculated over the entire data block (excluding the CRC bytes) including the user data, alive counter and Data ID



- CRC Polynomial (0x1021) , Initial Value : 0xFFFF, XOR value : 0x0000, Data ID : Message ID + 0xF800 

- The initial value is for CRC calculation and the message should be sent with the calculated result value. 

- The mathematical expression to 16 bit CRC polynomial is given here. G(x) = x16 + x12 + x5 + 1



<For CRC calculation of CAN-FD Msg for HS CAN domain ECUs>



- HS-CAN Messages that routed from CAN-FD domain are using 29 bit Extended CAN ID and splitted into 8 Byte Messages.

(from 1 to 4 Msgs, depending on source CAN-FD Msg¡¯s DLC)

- For splitted CAN-FD Msgs¡¯ CRC calculation, HS CAN ECUs should use source CAN-FD Msg¡¯s original STD ID. 

- The original STD ID can be read from Ext ID¡¯s 4~6th Byte.

Eg. STD 0x6AA : EXT SPLT 0x1A8[6AA]01 / 0x1A8[6AA]02 / 0x1A8[6AA]03 / 0x1A8[6AA]04 

(2~4th splitited Msgs can be omitted depending on source CAN-FD Msg¡¯s DLC)

- Aslo, HS-CAN ECUs should use merged data block (from whole splitted Msg) for CRC calculation.";
BA_ "GenSigStartValue" SG_ 2172675329 IEB_Crc1Val 65535;
BA_ "UserSigValidity" SG_ 2172675329 IEB_Crc1Val 3;
BA_ "RoutingFactor" SG_ 2172675329 IEB_Crc1Val 5;
BA_ "Version" SG_ 2172675329 IEB_Crc1Val "21.09.03";
BA_ "Description" SG_ 2172675329 IEB_AlvCnt1Val "For the first transmission request for a data element the counter shall be initialized with 0 and shall be incremented by 1 for every subsequent send request. 

When the counter reaches the maximum value(0xFF), then it shall restart with 0 for the next send request";
BA_ "UserSigValidity" SG_ 2172675329 IEB_AlvCnt1Val 3;
BA_ "RoutingFactor" SG_ 2172675329 IEB_AlvCnt1Val 5;
BA_ "Version" SG_ 2172675329 IEB_AlvCnt1Val "21.09.03";
BA_ "Description" SG_ 2172675329 IEB_SrvLmpDis "The signal indicates the status of the ¡°AHB Service lamp¡±";
BA_ "UserSigValidity" SG_ 2172675329 IEB_SrvLmpDis 3;
BA_ "RoutingFactor" SG_ 2172675329 IEB_SrvLmpDis 5;
BA_ "Version" SG_ 2172675329 IEB_SrvLmpDis "19.05.02";
BA_ "Description" SG_ 2172675329 IEB_DfctvSta "Information regarding the AHB 'defective' indication.";
BA_ "UserSigValidity" SG_ 2172675329 IEB_DfctvSta 3;
BA_ "RoutingFactor" SG_ 2172675329 IEB_DfctvSta 5;
BA_ "Version" SG_ 2172675329 IEB_DfctvSta "19.05.02";
BA_ "Description" SG_ 2172675329 IEB_ActvSta "Information regarding AHB ¡°Control Active¡± signal";
BA_ "UserSigValidity" SG_ 2172675329 IEB_ActvSta 3;
BA_ "RoutingFactor" SG_ 2172675329 IEB_ActvSta 5;
BA_ "Version" SG_ 2172675329 IEB_ActvSta "19.05.02";
BA_ "Description" SG_ 2172675329 IEB_DiagSta "Information regarding the AHB ¡°diagnostic mode¡± indication.";
BA_ "UserSigValidity" SG_ 2172675329 IEB_DiagSta 3;
BA_ "RoutingFactor" SG_ 2172675329 IEB_DiagSta 5;
BA_ "Version" SG_ 2172675329 IEB_DiagSta "19.05.02";
BA_ "Description" SG_ 2172675329 IEB_WrngLmpDis "The signal indicates the status of the ¡°AHB Warning lamp¡±";
BA_ "UserSigValidity" SG_ 2172675329 IEB_WrngLmpDis 3;
BA_ "RoutingFactor" SG_ 2172675329 IEB_WrngLmpDis 5;
BA_ "Version" SG_ 2172675329 IEB_WrngLmpDis "19.05.02";
BA_ "Description" SG_ 2172675329 IEB_MILReq "IEB sends this signal to turn on the Malfunction Indicator Lamp (MIL).";
BA_ "UserSigValidity" SG_ 2172675329 IEB_MILReq 3;
BA_ "RoutingFactor" SG_ 2172675329 IEB_MILReq 5;
BA_ "Version" SG_ 2172675329 IEB_MILReq "19.05.02";
BA_ "Description" SG_ 2172675329 IEB_DriftModeStaDis "This signal is for a pop-up display on restriction status of drift mode activation";
BA_ "UserSigValidity" SG_ 2172675329 IEB_DriftModeStaDis 3;
BA_ "RoutingFactor" SG_ 2172675329 IEB_DriftModeStaDis 5;
BA_ "Version" SG_ 2172675329 IEB_DriftModeStaDis "22.11.03";
BA_ "Description" SG_ 2172675329 IEB_StrkDpthmmVal "The signal indicates the depth of brake pedal";
BA_ "UserSigValidity" SG_ 2172675329 IEB_StrkDpthmmVal 3;
BA_ "RoutingFactor" SG_ 2172675329 IEB_StrkDpthmmVal 5;
BA_ "Version" SG_ 2172675329 IEB_StrkDpthmmVal "19.05.02";
BA_ "Description" SG_ 2172675329 IEB_BrkActvSta "This signal indicates that a brake switch is activated or not. When the brake switch is activated(pressed) its value is 02H otherwise its value is 01H.

If the ECU does not support this signal the value is 00H.



ÀÌ ½ÅÈ£´Â EV, FCEV ¿¡¼­¸¸ »ç¿ëµÉ ¼ö ÀÖÀ½.

This signal can be used in EV or FCEV vehicle.";
BA_ "UserSigValidity" SG_ 2172675329 IEB_BrkActvSta 3;
BA_ "RoutingFactor" SG_ 2172675329 IEB_BrkActvSta 5;
BA_ "Version" SG_ 2172675329 IEB_BrkActvSta "19.05.05";
BA_ "Description" SG_ 2172675329 IEB_PdlTrvlSnsrFailSta "Information regarding the pedal travel sensor fail status";
BA_ "UserSigValidity" SG_ 2172675329 IEB_PdlTrvlSnsrFailSta 3;
BA_ "RoutingFactor" SG_ 2172675329 IEB_PdlTrvlSnsrFailSta 5;
BA_ "Version" SG_ 2172675329 IEB_PdlTrvlSnsrFailSta "19.05.02";
BA_ "Description" SG_ 2172675329 IEB_PdlCalibSta "Information regarding the pedal travel sensor¡¯s calibration status";
BA_ "UserSigValidity" SG_ 2172675329 IEB_PdlCalibSta 3;
BA_ "RoutingFactor" SG_ 2172675329 IEB_PdlCalibSta 5;
BA_ "Version" SG_ 2172675329 IEB_PdlCalibSta "19.05.02";
BA_ "Description" SG_ 2172675329 IEB_BzrSta "The signal indicates the status of the ¡°Buzzer¡±";
BA_ "UserSigValidity" SG_ 2172675329 IEB_BzrSta 3;
BA_ "RoutingFactor" SG_ 2172675329 IEB_BzrSta 5;
BA_ "Version" SG_ 2172675329 IEB_BzrSta "19.05.02";
BA_ "GenMsgSendType" BO_ 2172675330 0;
BA_ "GenMsgCycleTime" BO_ 2172675330 50;
BA_ "GenMsgCycleTimeFast" BO_ 2172675330 0;
BA_ "GenMsgNrOfRepetition" BO_ 2172675330 0;
BA_ "VFrameFormat" BO_ 2172675330 1;
BA_ "Description" SG_ 2172675330 IEB_Sta "EBS Ready Status

¡Ø Àü/ÈÄ·û¿¡ ´ëÇÑ ±¸ºÐÀÌ ¾ø´Â °æ¿ì¿¡´Â 0x0 (Not Ready) / 0x1(Ready) ¸¸ »ç¿ëÇÑ´Ù.

     : Àü·û ±¸µ¿ È¸»ýÁ¦µ¿ Â÷·®ÀÇ °æ¿ì, 0x0 ´Â Front not Ready / 0x1Àº Front only Ready¸¦ ÀÇ¹ÌÇÔ.";
BA_ "UserSigValidity" SG_ 2172675330 IEB_Sta 3;
BA_ "RoutingFactor" SG_ 2172675330 IEB_Sta 5;
BA_ "Version" SG_ 2172675330 IEB_Sta "19.06.01";
BA_ "UserSigValidity" SG_ 2172675330 IEB_SnsrFailSta 3;
BA_ "RoutingFactor" SG_ 2172675330 IEB_SnsrFailSta 5;
BA_ "Version" SG_ 2172675330 IEB_SnsrFailSta "19.05.02";
BA_ "Description" SG_ 2172675330 IEB_EstTtlBrkFrcNmVal "Estimated Total Brake Force";
BA_ "UserSigValidity" SG_ 2172675330 IEB_EstTtlBrkFrcNmVal 3;
BA_ "RoutingFactor" SG_ 2172675330 IEB_EstTtlBrkFrcNmVal 5;
BA_ "Version" SG_ 2172675330 IEB_EstTtlBrkFrcNmVal "19.05.02";
BA_ "Description" SG_ 2172675330 IEB_RbsWrngLmpSta "This signal indicates RBS warning lamp status.";
BA_ "UserSigValidity" SG_ 2172675330 IEB_RbsWrngLmpSta 3;
BA_ "RoutingFactor" SG_ 2172675330 IEB_RbsWrngLmpSta 5;
BA_ "Version" SG_ 2172675330 IEB_RbsWrngLmpSta "19.05.02";
BA_ "Description" SG_ 2172675330 IEB_StrkDpthPcVal "Brake Pedal Stroke Depth";
BA_ "UserSigValidity" SG_ 2172675330 IEB_StrkDpthPcVal 3;
BA_ "RoutingFactor" SG_ 2172675330 IEB_StrkDpthPcVal 5;
BA_ "Version" SG_ 2172675330 IEB_StrkDpthPcVal "19.05.02";
BA_ "Description" SG_ 2172675330 IEB_EstDpthPcVal "Estimated Brake Pedal Depth for SCC";
BA_ "UserSigValidity" SG_ 2172675330 IEB_EstDpthPcVal 3;
BA_ "RoutingFactor" SG_ 2172675330 IEB_EstDpthPcVal 5;
BA_ "Version" SG_ 2172675330 IEB_EstDpthPcVal "19.05.02";
BA_ "Description" SG_ 2172675330 IEB_AbsNGearReq "indigates N gear position request while ABS activation";
BA_ "UserSigValidity" SG_ 2172675330 IEB_AbsNGearReq 3;
BA_ "RoutingFactor" SG_ 2172675330 IEB_AbsNGearReq 5;
BA_ "Version" SG_ 2172675330 IEB_AbsNGearReq "19.05.02";
BA_ "Description" SG_ 2172675330 IEB_EstBrkPdlValVldSta "Estimated Brake pedal value Validity";
BA_ "GenSigStartValue" SG_ 2172675330 IEB_EstBrkPdlValVldSta 1;
BA_ "UserSigValidity" SG_ 2172675330 IEB_EstBrkPdlValVldSta 3;
BA_ "RoutingFactor" SG_ 2172675330 IEB_EstBrkPdlValVldSta 5;
BA_ "Version" SG_ 2172675330 IEB_EstBrkPdlValVldSta "19.05.02";
BA_ "Description" SG_ 2172675330 IEB_VacSysDfctvSta "This signal indicates Vacuum pump ¡°defective¡±.";
BA_ "UserSigValidity" SG_ 2172675330 IEB_VacSysDfctvSta 3;
BA_ "RoutingFactor" SG_ 2172675330 IEB_VacSysDfctvSta 5;
BA_ "Version" SG_ 2172675330 IEB_VacSysDfctvSta "19.05.02";
BA_ "Description" SG_ 2172675330 IEB_FRAmode_Req "This signal requests braking load reduction logic when braking the ABS based on an electric vehicle";
BA_ "UserSigValidity" SG_ 2172675330 IEB_FRAmode_Req 3;
BA_ "RoutingFactor" SG_ 2172675330 IEB_FRAmode_Req 5;
BA_ "Version" SG_ 2172675330 IEB_FRAmode_Req "22.10.20";
BA_ "Description" SG_ 2172675330 IEB_DriftEscModSta_VDC "ESC/VDC mode command from DMIC by AVNT custom mode select";
BA_ "UserSigValidity" SG_ 2172675330 IEB_DriftEscModSta_VDC 3;
BA_ "RoutingFactor" SG_ 2172675330 IEB_DriftEscModSta_VDC 5;
BA_ "Version" SG_ 2172675330 IEB_DriftEscModSta_VDC "22.07.06";
BA_ "Description" SG_ 2172675330 IEB_RegenTqLimitNmVal_Frnt "Regen Brake Torque limit at front wheel";
BA_ "UserSigValidity" SG_ 2172675330 IEB_RegenTqLimitNmVal_Frnt 3;
BA_ "RoutingFactor" SG_ 2172675330 IEB_RegenTqLimitNmVal_Frnt 5;
BA_ "Version" SG_ 2172675330 IEB_RegenTqLimitNmVal_Frnt "19.05.03";
BA_ "GenMsgSendType" BO_ 2172675331 0;
BA_ "GenMsgCycleTime" BO_ 2172675331 50;
BA_ "GenMsgCycleTimeFast" BO_ 2172675331 0;
BA_ "GenMsgNrOfRepetition" BO_ 2172675331 0;
BA_ "VFrameFormat" BO_ 2172675331 1;
BA_ "Description" SG_ 2172675331 IEB_RegenTqLimitNmVal_Rear "Regen Brake Torque limit at rear wheel";
BA_ "UserSigValidity" SG_ 2172675331 IEB_RegenTqLimitNmVal_Rear 3;
BA_ "RoutingFactor" SG_ 2172675331 IEB_RegenTqLimitNmVal_Rear 5;
BA_ "Version" SG_ 2172675331 IEB_RegenTqLimitNmVal_Rear "19.05.03";
BA_ "Description" SG_ 2172675331 IEB_DrvWhlSlipFlg_Frnt "This signal is to indicate the slip status of the driving wheels.";
BA_ "UserSigValidity" SG_ 2172675331 IEB_DrvWhlSlipFlg_Frnt 3;
BA_ "RoutingFactor" SG_ 2172675331 IEB_DrvWhlSlipFlg_Frnt 5;
BA_ "Version" SG_ 2172675331 IEB_DrvWhlSlipFlg_Frnt "20.10.02";
BA_ "Description" SG_ 2172675331 IEB_IndDriftMode "Signal for feedback from AVNT drift mode ON/OFF command";
BA_ "UserSigValidity" SG_ 2172675331 IEB_IndDriftMode 3;
BA_ "RoutingFactor" SG_ 2172675331 IEB_IndDriftMode 5;
BA_ "Version" SG_ 2172675331 IEB_IndDriftMode "22.02.04";
BA_ "Description" SG_ 2172675331 IEB_IndDriftEcsModSta "Signal for feed back of  ECS mode command from DMIC by AVNT custom mode select";
BA_ "UserSigValidity" SG_ 2172675331 IEB_IndDriftEcsModSta 3;
BA_ "RoutingFactor" SG_ 2172675331 IEB_IndDriftEcsModSta 5;
BA_ "Version" SG_ 2172675331 IEB_IndDriftEcsModSta "22.07.06";
BA_ "Description" SG_ 2172675331 IEB_IndDriftElsdModSta "Signal for feed back of ELSD mode command from DMIC by AVNT custom mode select";
BA_ "UserSigValidity" SG_ 2172675331 IEB_IndDriftElsdModSta 3;
BA_ "RoutingFactor" SG_ 2172675331 IEB_IndDriftElsdModSta 5;
BA_ "Version" SG_ 2172675331 IEB_IndDriftElsdModSta "22.07.06";
BA_ "Description" SG_ 2172675331 IEB_TCS_Req "ÀÌ ½ÅÈ£´Â IEB_01_10ms ¸Þ½ÃÁöÀÇ TCS ÅäÅ© ½ÅÈ£¿¡ ´ëÇÑ Validity¸¦ ÀÇ¹ÌÇÑ´Ù.



0x1 : TCS_TqIntrvntnVal_Frnt, TCS_TqIntrvntnVal_Rear ½ÅÈ£¿¡ ÀÇÇÑ TCS Á¦¾î

0x2 : TCS_MtrTrgtRpm_Frnt, TCS_MtrTrgtRpm_Rear ½ÅÈ£¿¡ ÀÇÇÑ TCS Á¦¾î";
BA_ "UserSigValidity" SG_ 2172675331 IEB_TCS_Req 3;
BA_ "RoutingFactor" SG_ 2172675331 IEB_TCS_Req 5;
BA_ "Version" SG_ 2172675331 IEB_TCS_Req "20.04.05";
BA_ "Description" SG_ 2172675331 IEB_RSC_Req "Validity of RSC torque signal from IEB_01_10ms";
BA_ "UserSigValidity" SG_ 2172675331 IEB_RSC_Req 3;
BA_ "RoutingFactor" SG_ 2172675331 IEB_RSC_Req 5;
BA_ "Version" SG_ 2172675331 IEB_RSC_Req "22.01.02";
BA_ "Description" SG_ 2172675331 TCS_TqFlag_Frnt "ÀÌ ½ÅÈ£´Â IEB_01_10ms ¸Þ½ÃÁöÀÇ TCS Àü·û ÅäÅ© ½ÅÈ£¿¡ ´ëÇÑ ºÎÈ£¸¦ ÀÇ¹ÌÇÑ´Ù.";
BA_ "UserSigValidity" SG_ 2172675331 TCS_TqFlag_Frnt 3;
BA_ "RoutingFactor" SG_ 2172675331 TCS_TqFlag_Frnt 5;
BA_ "Version" SG_ 2172675331 TCS_TqFlag_Frnt "19.05.03";
BA_ "Description" SG_ 2172675331 TCS_TqFlag_Rear "ÀÌ ½ÅÈ£´Â IEB_01_10ms ¸Þ½ÃÁöÀÇ TCS ÈÄ·û ÅäÅ© ½ÅÈ£¿¡ ´ëÇÑ ºÎÈ£¸¦ ÀÇ¹ÌÇÑ´Ù.";
BA_ "UserSigValidity" SG_ 2172675331 TCS_TqFlag_Rear 3;
BA_ "RoutingFactor" SG_ 2172675331 TCS_TqFlag_Rear 5;
BA_ "Version" SG_ 2172675331 TCS_TqFlag_Rear "19.05.03";
BA_ "Description" SG_ 2172675331 RSC_TqFlag_Frnt "ÀÌ ½ÅÈ£´Â IEB_01_10ms ¸Þ½ÃÁöÀÇ RSC Àü·û ÅäÅ© ½ÅÈ£¿¡ ´ëÇÑ ºÎÈ£¸¦ ÀÇ¹ÌÇÑ´Ù.";
BA_ "UserSigValidity" SG_ 2172675331 RSC_TqFlag_Frnt 3;
BA_ "RoutingFactor" SG_ 2172675331 RSC_TqFlag_Frnt 5;
BA_ "Version" SG_ 2172675331 RSC_TqFlag_Frnt "19.05.03";
BA_ "Description" SG_ 2172675331 RSC_TqFlag_Rear "ÀÌ ½ÅÈ£´Â IEB_01_10ms ¸Þ½ÃÁöÀÇ RSC ÈÄ·û ÅäÅ© ½ÅÈ£¿¡ ´ëÇÑ ºÎÈ£¸¦ ÀÇ¹ÌÇÑ´Ù.";
BA_ "UserSigValidity" SG_ 2172675331 RSC_TqFlag_Rear 3;
BA_ "RoutingFactor" SG_ 2172675331 RSC_TqFlag_Rear 5;
BA_ "Version" SG_ 2172675331 RSC_TqFlag_Rear "19.05.03";
BA_ "Description" SG_ 2172675331 TCS_TqIntrvntnVal_Frnt "TCS Á¦¾î¸¦ À§ÇÑ Àü·û ±¸µ¿ÅäÅ©ÀÇ ¿ä±¸°ªÀ» ÀÇ¹Ì.

ºÎÈ£´Â TCS_TqFlag_Frnt ½ÅÈ£¸¦ ÂüÁ¶.";
BA_ "UserSigValidity" SG_ 2172675331 TCS_TqIntrvntnVal_Frnt 3;
BA_ "RoutingFactor" SG_ 2172675331 TCS_TqIntrvntnVal_Frnt 5;
BA_ "Version" SG_ 2172675331 TCS_TqIntrvntnVal_Frnt "19.05.03";
BA_ "Description" SG_ 2172675331 TCS_TqIntrvntnVal_Rear "TCS Á¦¾î¸¦ À§ÇÑ ÈÄ·û ±¸µ¿ÅäÅ©ÀÇ ¿ä±¸°ªÀ» ÀÇ¹Ì.

ºÎÈ£´Â TCS_TqFlag_Rear ½ÅÈ£¸¦ ÂüÁ¶.";
BA_ "UserSigValidity" SG_ 2172675331 TCS_TqIntrvntnVal_Rear 3;
BA_ "RoutingFactor" SG_ 2172675331 TCS_TqIntrvntnVal_Rear 5;
BA_ "Version" SG_ 2172675331 TCS_TqIntrvntnVal_Rear "19.05.03";
BA_ "Description" SG_ 2172675331 RSC_TqIntrvntnVal_Frnt "RSC Á¦¾î¸¦ À§ÇÑ Àü·û ±¸µ¿ÅäÅ©ÀÇ ¿ä±¸°ªÀ» ÀÇ¹Ì.

ºÎÈ£´Â RSC_TqFlag_Frnt ½ÅÈ£¸¦ ÂüÁ¶.";
BA_ "UserSigValidity" SG_ 2172675331 RSC_TqIntrvntnVal_Frnt 3;
BA_ "RoutingFactor" SG_ 2172675331 RSC_TqIntrvntnVal_Frnt 5;
BA_ "Version" SG_ 2172675331 RSC_TqIntrvntnVal_Frnt "19.05.03";
BA_ "Description" SG_ 2172675331 RSC_TqIntrvntnVal_Rear "RSC Á¦¾î¸¦ À§ÇÑ ÈÄ·û ±¸µ¿ÅäÅ©ÀÇ ¿ä±¸°ªÀ» ÀÇ¹Ì.

ºÎÈ£´Â RSC_TqFlag_Rear ½ÅÈ£¸¦ ÂüÁ¶.";
BA_ "UserSigValidity" SG_ 2172675331 RSC_TqIntrvntnVal_Rear 3;
BA_ "RoutingFactor" SG_ 2172675331 RSC_TqIntrvntnVal_Rear 5;
BA_ "Version" SG_ 2172675331 RSC_TqIntrvntnVal_Rear "19.05.03";
BA_ "GenMsgSendType" BO_ 2172675332 0;
BA_ "GenMsgCycleTime" BO_ 2172675332 50;
BA_ "GenMsgCycleTimeFast" BO_ 2172675332 0;
BA_ "GenMsgNrOfRepetition" BO_ 2172675332 0;
BA_ "VFrameFormat" BO_ 2172675332 1;
BA_ "Description" SG_ 2172675332 TCS_MtrTrgtRpm_Flag_Frnt "ÀÌ ½ÅÈ£´Â IEB_01_10ms ¸Þ½ÃÁöÀÇ TCS ÀÛµ¿½Ã Àü·û ¸ðÅÍÀÇ Å¸°Ù RPM ½ÅÈ£(TCS_MtrTrgtRpm_Frnt)¿¡ ´ëÇÑ ºÎÈ£¸¦ ÀÇ¹ÌÇÑ´Ù.";
BA_ "UserSigValidity" SG_ 2172675332 TCS_MtrTrgtRpm_Flag_Frnt 3;
BA_ "RoutingFactor" SG_ 2172675332 TCS_MtrTrgtRpm_Flag_Frnt 5;
BA_ "Version" SG_ 2172675332 TCS_MtrTrgtRpm_Flag_Frnt "20.04.05";
BA_ "Description" SG_ 2172675332 TCS_MtrTrgtRpm_Flag_Rear "ÀÌ ½ÅÈ£´Â IEB_01_10ms ¸Þ½ÃÁöÀÇ TCS ÀÛµ¿½Ã ÈÄ·û ¸ðÅÍÀÇ Å¸°Ù RPM ½ÅÈ£(TCS_MtrTrgtRpm_Rear)¿¡ ´ëÇÑ ºÎÈ£¸¦ ÀÇ¹ÌÇÑ´Ù.";
BA_ "UserSigValidity" SG_ 2172675332 TCS_MtrTrgtRpm_Flag_Rear 3;
BA_ "RoutingFactor" SG_ 2172675332 TCS_MtrTrgtRpm_Flag_Rear 5;
BA_ "Version" SG_ 2172675332 TCS_MtrTrgtRpm_Flag_Rear "20.04.05";
BA_ "Description" SG_ 2172675332 IEB_DriftElsdModSta "ELSD mode command from DMIC by AVNT custom mode select";
BA_ "UserSigValidity" SG_ 2172675332 IEB_DriftElsdModSta 3;
BA_ "RoutingFactor" SG_ 2172675332 IEB_DriftElsdModSta 5;
BA_ "Version" SG_ 2172675332 IEB_DriftElsdModSta "22.07.06";
BA_ "Description" SG_ 2172675332 TCS_MtrTrgtRpm_Rear "TCS Á¦¾î¸¦ À§ÇÑ ÈÄ·û ¸ðÅÍÀÇ RPM ¿ä±¸°ªÀ» ÀÇ¹Ì.

ºÎÈ£´Â TCS_MtrTrgtRpm_Flag_Rear ½ÅÈ£¸¦ ÂüÁ¶.";
BA_ "UserSigValidity" SG_ 2172675332 TCS_MtrTrgtRpm_Rear 3;
BA_ "RoutingFactor" SG_ 2172675332 TCS_MtrTrgtRpm_Rear 5;
BA_ "Version" SG_ 2172675332 TCS_MtrTrgtRpm_Rear "20.04.05";
BA_ "Description" SG_ 2172675332 IEB_DriftModeSta "This signal is for a pop-up display on drift mode.";
BA_ "UserSigValidity" SG_ 2172675332 IEB_DriftModeSta 3;
BA_ "RoutingFactor" SG_ 2172675332 IEB_DriftModeSta 5;
BA_ "Version" SG_ 2172675332 IEB_DriftModeSta "20.12.02";
BA_ "Description" SG_ 2172675332 IEB_DriftModeActSta "This signal is for drift mode ON/OFF status";
BA_ "UserSigValidity" SG_ 2172675332 IEB_DriftModeActSta 3;
BA_ "RoutingFactor" SG_ 2172675332 IEB_DriftModeActSta 5;
BA_ "Version" SG_ 2172675332 IEB_DriftModeActSta "20.12.02";
BA_ "Description" SG_ 2172675332 MCU_AntiJerk_Inhbtsta "MCU_AntiJerk_Inhbtsta is a signal to inform the MCU of anti-jerk control prohibition in order to prevent side effects caused by intervention in the IEB when ABS control and MCU anti-jerk control overlap.";
BA_ "UserSigValidity" SG_ 2172675332 MCU_AntiJerk_Inhbtsta 3;
BA_ "RoutingFactor" SG_ 2172675332 MCU_AntiJerk_Inhbtsta 5;
BA_ "Version" SG_ 2172675332 MCU_AntiJerk_Inhbtsta "22.11.03";
BA_ "Description" SG_ 2172675332 IEB_Motor_ProtectModSta "It is a signal to notify when the internal motor protection mode of the electric integrated booster is activated.

When the corresponding signal becomes a flag (0x1), the braking pressure is limited to a maximum of 60bar in the stop state.

It is not affected while driving, and the mode is released by itself after about 10 minutes.";
BA_ "UserSigValidity" SG_ 2172675332 IEB_Motor_ProtectModSta 3;
BA_ "RoutingFactor" SG_ 2172675332 IEB_Motor_ProtectModSta 5;
BA_ "Version" SG_ 2172675332 IEB_Motor_ProtectModSta "22.08.03";
BA_ "Description" SG_ 2172675332 IEB_DriftEcsModSta "ECS mode command from DMIC by AVNT custom mode select";
BA_ "UserSigValidity" SG_ 2172675332 IEB_DriftEcsModSta 3;
BA_ "RoutingFactor" SG_ 2172675332 IEB_DriftEcsModSta 5;
BA_ "Version" SG_ 2172675332 IEB_DriftEcsModSta "22.07.06";
BA_ "Description" SG_ 2172675332 IEB_EstBrkSacFrcNmVal "Estimated brake force value for stop assist control";
BA_ "UserSigValidity" SG_ 2172675332 IEB_EstBrkSacFrcNmVal 3;
BA_ "RoutingFactor" SG_ 2172675332 IEB_EstBrkSacFrcNmVal 5;
BA_ "Version" SG_ 2172675332 IEB_EstBrkSacFrcNmVal "21.11.00";
BA_ "Description" SG_ 2172675332 IEB_IndDriftEscModSta_TCS "Signal for feed back of TCS mode change from DMIC by AVNT custom mode select";
BA_ "UserSigValidity" SG_ 2172675332 IEB_IndDriftEscModSta_TCS 3;
BA_ "RoutingFactor" SG_ 2172675332 IEB_IndDriftEscModSta_TCS 5;
BA_ "Version" SG_ 2172675332 IEB_IndDriftEscModSta_TCS "22.07.06";
BA_ "Description" SG_ 2172675332 IEB_DriftMdpsModSta "MDPS mode command from DMIC by AVNT custom mode select";
BA_ "UserSigValidity" SG_ 2172675332 IEB_DriftMdpsModSta 3;
BA_ "RoutingFactor" SG_ 2172675332 IEB_DriftMdpsModSta 5;
BA_ "Version" SG_ 2172675332 IEB_DriftMdpsModSta "22.07.06";
BA_ "Description" SG_ 2172675332 IEB_IndDriftEscModSta_VDC "Signal for feed back of ESC/VDC mode command from DMIC by AVNT custom mode select";
BA_ "UserSigValidity" SG_ 2172675332 IEB_IndDriftEscModSta_VDC 3;
BA_ "RoutingFactor" SG_ 2172675332 IEB_IndDriftEscModSta_VDC 5;
BA_ "Version" SG_ 2172675332 IEB_IndDriftEscModSta_VDC "22.07.06";
BA_ "Description" SG_ 2172675332 IEB_IndDriftMdpsModSta "Signal for feed back of MDPS mode command from DMIC by AVNT custom mode select";
BA_ "UserSigValidity" SG_ 2172675332 IEB_IndDriftMdpsModSta 3;
BA_ "RoutingFactor" SG_ 2172675332 IEB_IndDriftMdpsModSta 5;
BA_ "Version" SG_ 2172675332 IEB_IndDriftMdpsModSta "22.07.06";
BA_ "Description" SG_ 2172675332 TCS_MtrTrgtRpm_Frnt "TCS Á¦¾î¸¦ À§ÇÑ Àü·û ¸ðÅÍÀÇ RPM ¿ä±¸°ªÀ» ÀÇ¹Ì.

ºÎÈ£´Â TCS_MtrTrgtRpm_Flag_Frnt ½ÅÈ£¸¦ ÂüÁ¶.";
BA_ "UserSigValidity" SG_ 2172675332 TCS_MtrTrgtRpm_Frnt 3;
BA_ "RoutingFactor" SG_ 2172675332 TCS_MtrTrgtRpm_Frnt 5;
BA_ "Version" SG_ 2172675332 TCS_MtrTrgtRpm_Frnt "20.04.05";
BA_ "GenMsgSendType" BO_ 761 0;
BA_ "Description" SG_ 761 SBCM_AST_Crc3Val "The data area for CRC calculation is based on the data length (DLC) of the message DB.

The CRC shall be calculated over the entire data block (excluding the CRC bytes) including the user data, alive counter and Data ID 

 

- CRC Polynomial (0x1D) , Initial Value : 0x00, XOR value : 0xFF, Data ID Mode : Both, Data ID : Message ID + 0xF800 

- The initial value is for CRC calculation and the message should be sent with the calculated result value. 

The mathematical expression to 8 bit CRC polynomial is given here. G(x) = x8 + x4 + x3 + x2 + 1";
BA_ "GenSigSendType" SG_ 761 SBCM_AST_Crc3Val 4;
BA_ "UserSigValidity" SG_ 761 SBCM_AST_Crc3Val 0;
BA_ "RoutingFactor" SG_ 761 SBCM_AST_Crc3Val 0;
BA_ "Version" SG_ 761 SBCM_AST_Crc3Val "22.05.03";
BA_ "GenSigSendType" SG_ 761 CDM_TypeOption_AST 4;
BA_ "UserSigValidity" SG_ 761 CDM_TypeOption_AST 7;
BA_ "NetworkRequest" SG_ 761 CDM_TypeOption_AST 0;
BA_ "NetworkRequestHoldingTime" SG_ 761 CDM_TypeOption_AST 5000;
BA_ "RoutingFactor" SG_ 761 CDM_TypeOption_AST 0;
BA_ "Version" SG_ 761 CDM_TypeOption_AST "21.07.07";
BA_ "Description" SG_ 761 SBCM_AST_AlvCnt3Val "For the first transmission request for a data element the counter shall be initialized with 0 and shall be incremented by 1

for every subsequent send request. When the counter reaches the maximum value(0xE), then it shall restart with 0 for the next send request";
BA_ "GenSigSendType" SG_ 761 SBCM_AST_AlvCnt3Val 4;
BA_ "UserSigValidity" SG_ 761 SBCM_AST_AlvCnt3Val 0;
BA_ "RoutingFactor" SG_ 761 SBCM_AST_AlvCnt3Val 0;
BA_ "Version" SG_ 761 SBCM_AST_AlvCnt3Val "22.05.03";
BA_ "GenSigSendType" SG_ 761 CDM_ImmeChgSw_AST 4;
BA_ "UserSigValidity" SG_ 761 CDM_ImmeChgSw_AST 7;
BA_ "NetworkRequest" SG_ 761 CDM_ImmeChgSw_AST 0;
BA_ "NetworkRequestHoldingTime" SG_ 761 CDM_ImmeChgSw_AST 5000;
BA_ "RoutingFactor" SG_ 761 CDM_ImmeChgSw_AST 0;
BA_ "Version" SG_ 761 CDM_ImmeChgSw_AST "21.07.07";
BA_ "GenSigSendType" SG_ 761 CDM_ChgDrSwFrt_AST 4;
BA_ "UserSigValidity" SG_ 761 CDM_ChgDrSwFrt_AST 7;
BA_ "NetworkRequest" SG_ 761 CDM_ChgDrSwFrt_AST 0;
BA_ "NetworkRequestHoldingTime" SG_ 761 CDM_ChgDrSwFrt_AST 5000;
BA_ "RoutingFactor" SG_ 761 CDM_ChgDrSwFrt_AST 0;
BA_ "Version" SG_ 761 CDM_ChgDrSwFrt_AST "21.07.07";
BA_ "GenSigSendType" SG_ 761 CDM_OpnClsState_AST 4;
BA_ "UserSigValidity" SG_ 761 CDM_OpnClsState_AST 7;
BA_ "NetworkRequest" SG_ 761 CDM_OpnClsState_AST 0;
BA_ "NetworkRequestHoldingTime" SG_ 761 CDM_OpnClsState_AST 5000;
BA_ "RoutingFactor" SG_ 761 CDM_OpnClsState_AST 0;
BA_ "Version" SG_ 761 CDM_OpnClsState_AST "21.07.07";
BA_ "GenSigSendType" SG_ 761 CDM_WarnMsg_AST 4;
BA_ "UserSigValidity" SG_ 761 CDM_WarnMsg_AST 7;
BA_ "NetworkRequest" SG_ 761 CDM_WarnMsg_AST 0;
BA_ "NetworkRequestHoldingTime" SG_ 761 CDM_WarnMsg_AST 5000;
BA_ "RoutingFactor" SG_ 761 CDM_WarnMsg_AST 0;
BA_ "Version" SG_ 761 CDM_WarnMsg_AST "21.07.07";
BA_ "GenSigSendType" SG_ 761 Mirror_RH_FoldingSta 4;
BA_ "UserSigValidity" SG_ 761 Mirror_RH_FoldingSta 0;
BA_ "NetworkRequest" SG_ 761 Mirror_RH_FoldingSta 0;
BA_ "NetworkRequestHoldingTime" SG_ 761 Mirror_RH_FoldingSta 5000;
BA_ "RoutingFactor" SG_ 761 Mirror_RH_FoldingSta 0;
BA_ "Version" SG_ 761 Mirror_RH_FoldingSta "21.07.07";
BA_ "GenSigSendType" SG_ 761 Mirror_RH_UnfoldingSta 4;
BA_ "UserSigValidity" SG_ 761 Mirror_RH_UnfoldingSta 0;
BA_ "NetworkRequest" SG_ 761 Mirror_RH_UnfoldingSta 0;
BA_ "NetworkRequestHoldingTime" SG_ 761 Mirror_RH_UnfoldingSta 5000;
BA_ "RoutingFactor" SG_ 761 Mirror_RH_UnfoldingSta 0;
BA_ "Version" SG_ 761 Mirror_RH_UnfoldingSta "21.07.07";
BA_ "GenSigSendType" SG_ 761 CDM_CmdStatus_AST 4;
BA_ "GenSigStartValue" SG_ 761 CDM_CmdStatus_AST 15;
BA_ "UserSigValidity" SG_ 761 CDM_CmdStatus_AST 7;
BA_ "NetworkRequest" SG_ 761 CDM_CmdStatus_AST 0;
BA_ "NetworkRequestHoldingTime" SG_ 761 CDM_CmdStatus_AST 5000;
BA_ "RoutingFactor" SG_ 761 CDM_CmdStatus_AST 0;
BA_ "Version" SG_ 761 CDM_CmdStatus_AST "22.08.03";
BA_ "GenSigSendType" SG_ 761 AST_CrashMRActAlarm 4;
BA_ "UserSigValidity" SG_ 761 AST_CrashMRActAlarm 0;
BA_ "NetworkRequest" SG_ 761 AST_CrashMRActAlarm 0;
BA_ "NetworkRequestHoldingTime" SG_ 761 AST_CrashMRActAlarm 5000;
BA_ "RoutingFactor" SG_ 761 AST_CrashMRActAlarm 0;
BA_ "Version" SG_ 761 AST_CrashMRActAlarm "21.07.07";
BA_ "GenSigSendType" SG_ 761 PwrDRBuzzerOut_AST 4;
BA_ "UserSigValidity" SG_ 761 PwrDRBuzzerOut_AST 0;
BA_ "NetworkRequest" SG_ 761 PwrDRBuzzerOut_AST 0;
BA_ "NetworkRequestHoldingTime" SG_ 761 PwrDRBuzzerOut_AST 5000;
BA_ "RoutingFactor" SG_ 761 PwrDRBuzzerOut_AST 0;
BA_ "Version" SG_ 761 PwrDRBuzzerOut_AST "21.07.07";
BA_ "GenSigSendType" SG_ 761 IMS_OSMirPlayBackSta_RH 4;
BA_ "UserSigValidity" SG_ 761 IMS_OSMirPlayBackSta_RH 0;
BA_REL_ "GenSigTimeoutTime" BU_SG_REL_ GW_DPSU SG_ 761 IMS_OSMirPlayBackSta_RH 1500;
BA_ "NetworkRequest" SG_ 761 IMS_OSMirPlayBackSta_RH 0;
BA_ "NetworkRequestHoldingTime" SG_ 761 IMS_OSMirPlayBackSta_RH 5;
BA_ "RoutingFactor" SG_ 761 IMS_OSMirPlayBackSta_RH 0;
BA_ "Version" SG_ 761 IMS_OSMirPlayBackSta_RH "21.07.07";
BA_ "GenSigSendType" SG_ 761 PwrDRClosingASTDrSta 4;
BA_ "UserSigValidity" SG_ 761 PwrDRClosingASTDrSta 0;
BA_ "NetworkRequest" SG_ 761 PwrDRClosingASTDrSta 0;
BA_ "NetworkRequestHoldingTime" SG_ 761 PwrDRClosingASTDrSta 5000;
BA_ "RoutingFactor" SG_ 761 PwrDRClosingASTDrSta 0;
BA_ "Version" SG_ 761 PwrDRClosingASTDrSta "22.04.01";
BA_ "Description" SG_ 761 CDM_OutsideOpnSwSta_AST "Charging Door O/S SW State";
BA_ "GenSigSendType" SG_ 761 CDM_OutsideOpnSwSta_AST 4;
BA_ "UserSigValidity" SG_ 761 CDM_OutsideOpnSwSta_AST 7;
BA_ "NetworkRequest" SG_ 761 CDM_OutsideOpnSwSta_AST 0;
BA_ "NetworkRequestHoldingTime" SG_ 761 CDM_OutsideOpnSwSta_AST 5000;
BA_ "RoutingFactor" SG_ 761 CDM_OutsideOpnSwSta_AST 0;
BA_ "Version" SG_ 761 CDM_OutsideOpnSwSta_AST "23.02.02";
BA_ "GenSigSendType" SG_ 761 SBCM_Longkey_ASTDrAtClsSwSta 4;
BA_ "UserSigValidity" SG_ 761 SBCM_Longkey_ASTDrAtClsSwSta 0;
BA_ "NetworkRequest" SG_ 761 SBCM_Longkey_ASTDrAtClsSwSta 0;
BA_ "NetworkRequestHoldingTime" SG_ 761 SBCM_Longkey_ASTDrAtClsSwSta 5000;
BA_ "RoutingFactor" SG_ 761 SBCM_Longkey_ASTDrAtClsSwSta 0;
BA_ "Version" SG_ 761 SBCM_Longkey_ASTDrAtClsSwSta "22.04.02";
BA_ "Description" SG_ 761 Hood_TypeOption_AST "If the E-Hood is applied, the signal will be send.

Frunk signal from SBCM_AST to SBCM_DRV (RHD specification)";
BA_ "GenSigSendType" SG_ 761 Hood_TypeOption_AST 4;
BA_ "UserSigValidity" SG_ 761 Hood_TypeOption_AST 0;
BA_ "NetworkRequest" SG_ 761 Hood_TypeOption_AST 0;
BA_ "NetworkRequestHoldingTime" SG_ 761 Hood_TypeOption_AST 5000;
BA_ "RoutingFactor" SG_ 761 Hood_TypeOption_AST 0;
BA_ "Version" SG_ 761 Hood_TypeOption_AST "22.10.19";
BA_ "Description" SG_ 761 Warn_HoodSwSta_AST "Frunk signal from SBCM_AST to SBCM_DRV (RHD specification)";
BA_ "GenSigSendType" SG_ 761 Warn_HoodSwSta_AST 4;
BA_ "UserSigValidity" SG_ 761 Warn_HoodSwSta_AST 0;
BA_ "NetworkRequest" SG_ 761 Warn_HoodSwSta_AST 0;
BA_ "NetworkRequestHoldingTime" SG_ 761 Warn_HoodSwSta_AST 5000;
BA_ "RoutingFactor" SG_ 761 Warn_HoodSwSta_AST 0;
BA_ "Version" SG_ 761 Warn_HoodSwSta_AST "22.10.19";
BA_ "Description" SG_ 761 FrunkWarning_AST "Frunk signal from SBCM_AST to SBCM_DRV (RHD specification)";
BA_ "GenSigSendType" SG_ 761 FrunkWarning_AST 4;
BA_ "UserSigValidity" SG_ 761 FrunkWarning_AST 0;
BA_ "NetworkRequest" SG_ 761 FrunkWarning_AST 0;
BA_ "NetworkRequestHoldingTime" SG_ 761 FrunkWarning_AST 5000;
BA_ "RoutingFactor" SG_ 761 FrunkWarning_AST 0;
BA_ "Version" SG_ 761 FrunkWarning_AST "22.10.19";
BA_ "Description" SG_ 761 SBCM_FrunkSta_AST "Frunk signal from SBCM_AST to SBCM_DRV (RHD specification)";
BA_ "GenSigSendType" SG_ 761 SBCM_FrunkSta_AST 4;
BA_ "UserSigValidity" SG_ 761 SBCM_FrunkSta_AST 0;
BA_ "NetworkRequest" SG_ 761 SBCM_FrunkSta_AST 0;
BA_ "NetworkRequestHoldingTime" SG_ 761 SBCM_FrunkSta_AST 5000;
BA_ "RoutingFactor" SG_ 761 SBCM_FrunkSta_AST 0;
BA_ "Version" SG_ 761 SBCM_FrunkSta_AST "22.10.19";
BA_ "GenSigSendType" SG_ 761 Ast_DrLkRetryFail_SBCM 4;
BA_ "TimeoutValue" SG_ 761 Ast_DrLkRetryFail_SBCM "0x0";
BA_ "UserSigValidity" SG_ 761 Ast_DrLkRetryFail_SBCM 0;
BA_ "NetworkRequest" SG_ 761 Ast_DrLkRetryFail_SBCM 0;
BA_ "NetworkRequestHoldingTime" SG_ 761 Ast_DrLkRetryFail_SBCM 5000;
BA_ "RoutingFactor" SG_ 761 Ast_DrLkRetryFail_SBCM 0;
BA_ "Version" SG_ 761 Ast_DrLkRetryFail_SBCM "23.03.00";
BA_ "Description" SG_ 761 DoorLock_AstLkOutSta_SBCM "- Door Lock or Unlock Output State 

0x0 : Off (Door lock/unlock output Off state)

0x1 : On (Door lock/unlock output On state)";
BA_ "GenSigSendType" SG_ 761 DoorLock_AstLkOutSta_SBCM 4;
BA_ "UserSigValidity" SG_ 761 DoorLock_AstLkOutSta_SBCM 0;
BA_ "NetworkRequest" SG_ 761 DoorLock_AstLkOutSta_SBCM 0;
BA_ "NetworkRequestHoldingTime" SG_ 761 DoorLock_AstLkOutSta_SBCM 5000;
BA_ "RoutingFactor" SG_ 761 DoorLock_AstLkOutSta_SBCM 0;
BA_ "Version" SG_ 761 DoorLock_AstLkOutSta_SBCM "23.02.09";
BA_ "GenSigSendType" SG_ 761 SBCM_AST_DiagSta 4;
BA_ "UserSigValidity" SG_ 761 SBCM_AST_DiagSta 0;
BA_ "NetworkRequest" SG_ 761 SBCM_AST_DiagSta 0;
BA_ "NetworkRequestHoldingTime" SG_ 761 SBCM_AST_DiagSta 5000;
BA_ "RoutingFactor" SG_ 761 SBCM_AST_DiagSta 0;
BA_ "Version" SG_ 761 SBCM_AST_DiagSta "21.07.07";
BA_ "GenMsgSendType" BO_ 758 0;
BA_ "Description" SG_ 758 SBCM_DRV_Crc2Val "The data area for CRC calculation is based on the data length (DLC) of the message DB.

The CRC shall be calculated over the entire data block (excluding the CRC bytes) including the user data, alive counter and Data ID 

 

- CRC Polynomial (0x1D) , Initial Value : 0x00, XOR value : 0xFF, Data ID Mode : Both, Data ID : Message ID + 0xF800 

- The initial value is for CRC calculation and the message should be sent with the calculated result value. 

The mathematical expression to 8 bit CRC polynomial is given here. G(x) = x8 + x4 + x3 + x2 + 1";
BA_ "GenSigSendType" SG_ 758 SBCM_DRV_Crc2Val 4;
BA_ "UserSigValidity" SG_ 758 SBCM_DRV_Crc2Val 0;
BA_ "RoutingFactor" SG_ 758 SBCM_DRV_Crc2Val 0;
BA_ "Version" SG_ 758 SBCM_DRV_Crc2Val "22.05.03";
BA_ "Description" SG_ 758 DoorLock_CtrlDrLkUnLkSwSta_SBCM "Central Door Lock/Unlock Switch State";
BA_ "GenSigSendType" SG_ 758 DoorLock_CtrlDrLkUnLkSwSta_SBCM 4;
BA_ "UserSigValidity" SG_ 758 DoorLock_CtrlDrLkUnLkSwSta_SBCM 0;
BA_ "NetworkRequest" SG_ 758 DoorLock_CtrlDrLkUnLkSwSta_SBCM 0;
BA_ "NetworkRequestHoldingTime" SG_ 758 DoorLock_CtrlDrLkUnLkSwSta_SBCM 5000;
BA_ "RoutingFactor" SG_ 758 DoorLock_CtrlDrLkUnLkSwSta_SBCM 0;
BA_ "Version" SG_ 758 DoorLock_CtrlDrLkUnLkSwSta_SBCM "21.07.07";
BA_ "Description" SG_ 758 SBCM_DRV_AlvCnt2Val "For the first transmission request for a data element the counter shall be initialized with 0 and shall be incremented by 1

for every subsequent send request. When the counter reaches the maximum value(0xE), then it shall restart with 0 for the next send request";
BA_ "GenSigSendType" SG_ 758 SBCM_DRV_AlvCnt2Val 4;
BA_ "UserSigValidity" SG_ 758 SBCM_DRV_AlvCnt2Val 0;
BA_ "RoutingFactor" SG_ 758 SBCM_DRV_AlvCnt2Val 0;
BA_ "Version" SG_ 758 SBCM_DRV_AlvCnt2Val "22.05.03";
BA_ "GenSigSendType" SG_ 758 SBCM_PsvDrLkReq 4;
BA_ "UserSigValidity" SG_ 758 SBCM_PsvDrLkReq 0;
BA_ "NetworkRequest" SG_ 758 SBCM_PsvDrLkReq 0;
BA_ "RoutingFactor" SG_ 758 SBCM_PsvDrLkReq 0;
BA_ "Version" SG_ 758 SBCM_PsvDrLkReq "21.07.07";
BA_ "GenSigSendType" SG_ 758 CDMAutoWashModeSet_SBCM 4;
BA_ "UserSigValidity" SG_ 758 CDMAutoWashModeSet_SBCM 3;
BA_ "RoutingFactor" SG_ 758 CDMAutoWashModeSet_SBCM 0;
BA_ "Version" SG_ 758 CDMAutoWashModeSet_SBCM "22.07.00";
BA_ "GenSigSendType" SG_ 758 USM_DrvGhostDoorSta 4;
BA_ "UserSigValidity" SG_ 758 USM_DrvGhostDoorSta 0;
BA_ "NetworkRequest" SG_ 758 USM_DrvGhostDoorSta 0;
BA_ "NetworkRequestHoldingTime" SG_ 758 USM_DrvGhostDoorSta 5000;
BA_ "RoutingFactor" SG_ 758 USM_DrvGhostDoorSta 0;
BA_ "Version" SG_ 758 USM_DrvGhostDoorSta "21.07.07";
BA_ "GenSigSendType" SG_ 758 Mirror_LH_FoldingSta 4;
BA_ "UserSigValidity" SG_ 758 Mirror_LH_FoldingSta 0;
BA_ "NetworkRequest" SG_ 758 Mirror_LH_FoldingSta 0;
BA_ "NetworkRequestHoldingTime" SG_ 758 Mirror_LH_FoldingSta 5000;
BA_ "RoutingFactor" SG_ 758 Mirror_LH_FoldingSta 0;
BA_ "Version" SG_ 758 Mirror_LH_FoldingSta "21.07.07";
BA_ "GenSigSendType" SG_ 758 Mirror_LH_UnfoldingSta 4;
BA_ "UserSigValidity" SG_ 758 Mirror_LH_UnfoldingSta 0;
BA_ "NetworkRequest" SG_ 758 Mirror_LH_UnfoldingSta 0;
BA_ "NetworkRequestHoldingTime" SG_ 758 Mirror_LH_UnfoldingSta 5000;
BA_ "RoutingFactor" SG_ 758 Mirror_LH_UnfoldingSta 0;
BA_ "Version" SG_ 758 Mirror_LH_UnfoldingSta "21.07.07";
BA_ "GenSigSendType" SG_ 758 DRV_CrashMRActAlarm 4;
BA_ "UserSigValidity" SG_ 758 DRV_CrashMRActAlarm 0;
BA_ "NetworkRequest" SG_ 758 DRV_CrashMRActAlarm 0;
BA_ "NetworkRequestHoldingTime" SG_ 758 DRV_CrashMRActAlarm 5000;
BA_ "RoutingFactor" SG_ 758 DRV_CrashMRActAlarm 0;
BA_ "Version" SG_ 758 DRV_CrashMRActAlarm "21.07.07";
BA_ "GenSigSendType" SG_ 758 MirrorFldReq 4;
BA_ "UserSigValidity" SG_ 758 MirrorFldReq 0;
BA_ "NetworkRequest" SG_ 758 MirrorFldReq 0;
BA_ "NetworkRequestHoldingTime" SG_ 758 MirrorFldReq 5;
BA_ "RoutingFactor" SG_ 758 MirrorFldReq 0;
BA_ "Version" SG_ 758 MirrorFldReq "21.07.07";
BA_ "GenSigSendType" SG_ 758 OMU_TypeOption_DRV 4;
BA_ "UserSigValidity" SG_ 758 OMU_TypeOption_DRV 0;
BA_ "NetworkRequest" SG_ 758 OMU_TypeOption_DRV 0;
BA_ "NetworkRequestHoldingTime" SG_ 758 OMU_TypeOption_DRV 5000;
BA_ "RoutingFactor" SG_ 758 OMU_TypeOption_DRV 0;
BA_ "Version" SG_ 758 OMU_TypeOption_DRV "21.07.07";
BA_ "GenSigSendType" SG_ 758 IMS_OSMirPlayBackSta_LH 4;
BA_ "UserSigValidity" SG_ 758 IMS_OSMirPlayBackSta_LH 0;
BA_REL_ "GenSigTimeoutTime" BU_SG_REL_ GW_DPSU SG_ 758 IMS_OSMirPlayBackSta_LH 1500;
BA_ "NetworkRequest" SG_ 758 IMS_OSMirPlayBackSta_LH 0;
BA_ "NetworkRequestHoldingTime" SG_ 758 IMS_OSMirPlayBackSta_LH 5;
BA_ "RoutingFactor" SG_ 758 IMS_OSMirPlayBackSta_LH 0;
BA_ "Version" SG_ 758 IMS_OSMirPlayBackSta_LH "21.07.07";
BA_ "Description" SG_ 758 ECMMRR_PLUS "This signal for passenger outside mirror OEC function(or ECM)

SBCM_DRV receive the ECM voltage value via H/wiring and then send this signal to SBCM_AST";
BA_ "GenSigSendType" SG_ 758 ECMMRR_PLUS 4;
BA_ "UserSigValidity" SG_ 758 ECMMRR_PLUS 0;
BA_ "NetworkRequest" SG_ 758 ECMMRR_PLUS 0;
BA_ "NetworkRequestHoldingTime" SG_ 758 ECMMRR_PLUS 5000;
BA_ "RoutingFactor" SG_ 758 ECMMRR_PLUS 0;
BA_ "Version" SG_ 758 ECMMRR_PLUS "21.07.07";
BA_ "GenSigSendType" SG_ 758 SBCM_DRV_DiagSta 4;
BA_ "UserSigValidity" SG_ 758 SBCM_DRV_DiagSta 0;
BA_ "NetworkRequest" SG_ 758 SBCM_DRV_DiagSta 0;
BA_ "NetworkRequestHoldingTime" SG_ 758 SBCM_DRV_DiagSta 5000;
BA_ "RoutingFactor" SG_ 758 SBCM_DRV_DiagSta 0;
BA_ "Version" SG_ 758 SBCM_DRV_DiagSta "21.07.07";
BA_ "GenMsgSendType" BO_ 763 0;
BA_ "Description" SG_ 763 SBCM_DRV_Crc3Val "The data area for CRC calculation is based on the data length (DLC) of the message DB.

The CRC shall be calculated over the entire data block (excluding the CRC bytes) including the user data, alive counter and Data ID 

 

- CRC Polynomial (0x1D) , Initial Value : 0x00, XOR value : 0xFF, Data ID Mode : Both, Data ID : Message ID + 0xF800 

- The initial value is for CRC calculation and the message should be sent with the calculated result value. 

The mathematical expression to 8 bit CRC polynomial is given here. G(x) = x8 + x4 + x3 + x2 + 1";
BA_ "GenSigSendType" SG_ 763 SBCM_DRV_Crc3Val 4;
BA_ "UserSigValidity" SG_ 763 SBCM_DRV_Crc3Val 0;
BA_ "Version" SG_ 763 SBCM_DRV_Crc3Val "22.05.03";
BA_ "Description" SG_ 763 CDM_TypeOption "0x1 : On (CDM is applied)

0x2 : On_2EA (CDM 2EA are applied)";
BA_ "GenSigSendType" SG_ 763 CDM_TypeOption 4;
BA_ "UserSigValidity" SG_ 763 CDM_TypeOption 0;
BA_ "NetworkRequest" SG_ 763 CDM_TypeOption 0;
BA_ "NetworkRequestHoldingTime" SG_ 763 CDM_TypeOption 5000;
BA_ "Version" SG_ 763 CDM_TypeOption "23.04.02";
BA_ "Description" SG_ 763 SBCM_DRV_AlvCnt3Val "For the first transmission request for a data element the counter shall be initialized with 0 and shall be incremented by 1

for every subsequent send request. When the counter reaches the maximum value(0xE), then it shall restart with 0 for the next send request";
BA_ "GenSigSendType" SG_ 763 SBCM_DRV_AlvCnt3Val 4;
BA_ "UserSigValidity" SG_ 763 SBCM_DRV_AlvCnt3Val 0;
BA_ "Version" SG_ 763 SBCM_DRV_AlvCnt3Val "22.05.03";
BA_ "Description" SG_ 763 CDM_ImmeChgSw_SBCM "State of Immediate Charging Switch";
BA_ "GenSigSendType" SG_ 763 CDM_ImmeChgSw_SBCM 4;
BA_ "UserSigValidity" SG_ 763 CDM_ImmeChgSw_SBCM 7;
BA_ "Version" SG_ 763 CDM_ImmeChgSw_SBCM "21.07.07";
BA_ "Description" SG_ 763 CDM_ChgDrSwFrt_SBCM "State of Front Charging Door Open Switch";
BA_ "GenSigSendType" SG_ 763 CDM_ChgDrSwFrt_SBCM 4;
BA_ "UserSigValidity" SG_ 763 CDM_ChgDrSwFrt_SBCM 7;
BA_ "Version" SG_ 763 CDM_ChgDrSwFrt_SBCM "21.07.07";
BA_ "Description" SG_ 763 CDM_OpnClsState_SBCM "This signal indicates CDM Open/Close Status";
BA_ "GenSigSendType" SG_ 763 CDM_OpnClsState_SBCM 4;
BA_ "UserSigValidity" SG_ 763 CDM_OpnClsState_SBCM 7;
BA_ "Version" SG_ 763 CDM_OpnClsState_SBCM "21.07.07";
BA_ "Description" SG_ 763 CDM_WarnMsg_SBCM "Command for CDM Warning on cluster";
BA_ "GenSigSendType" SG_ 763 CDM_WarnMsg_SBCM 4;
BA_ "UserSigValidity" SG_ 763 CDM_WarnMsg_SBCM 7;
BA_ "Version" SG_ 763 CDM_WarnMsg_SBCM "21.07.07";
BA_ "GenSigSendType" SG_ 763 CDM_AutoWashModeSta 4;
BA_ "UserSigValidity" SG_ 763 CDM_AutoWashModeSta 0;
BA_ "NetworkRequest" SG_ 763 CDM_AutoWashModeSta 0;
BA_ "NetworkRequestHoldingTime" SG_ 763 CDM_AutoWashModeSta 5000;
BA_ "Version" SG_ 763 CDM_AutoWashModeSta "22.02.00";
BA_ "Description" SG_ 763 CDM_CmdStatus_SBCM "User Condition Check For CDM Operation";
BA_ "GenSigSendType" SG_ 763 CDM_CmdStatus_SBCM 4;
BA_ "GenSigStartValue" SG_ 763 CDM_CmdStatus_SBCM 15;
BA_ "UserSigValidity" SG_ 763 CDM_CmdStatus_SBCM 7;
BA_ "Version" SG_ 763 CDM_CmdStatus_SBCM "22.08.03";
BA_ "Description" SG_ 763 CDM_OutsideOpnSwSta "Charing Dorr O/S SW State";
BA_ "GenSigSendType" SG_ 763 CDM_OutsideOpnSwSta 4;
BA_ "UserSigValidity" SG_ 763 CDM_OutsideOpnSwSta 7;
BA_ "NetworkRequest" SG_ 763 CDM_OutsideOpnSwSta 0;
BA_ "NetworkRequestHoldingTime" SG_ 763 CDM_OutsideOpnSwSta 5000;
BA_ "Version" SG_ 763 CDM_OutsideOpnSwSta "23.02.02";
BA_ "GenSigSendType" SG_ 763 PwrDRBuzzerOut_DRV 4;
BA_ "UserSigValidity" SG_ 763 PwrDRBuzzerOut_DRV 0;
BA_ "NetworkRequest" SG_ 763 PwrDRBuzzerOut_DRV 0;
BA_ "NetworkRequestHoldingTime" SG_ 763 PwrDRBuzzerOut_DRV 5000;
BA_ "Version" SG_ 763 PwrDRBuzzerOut_DRV "21.07.07";
BA_ "GenSigSendType" SG_ 763 Warn_HoodSwSta_SBCM 4;
BA_ "UserSigValidity" SG_ 763 Warn_HoodSwSta_SBCM 0;
BA_REL_ "GenSigTimeoutTime" BU_SG_REL_ BLTN_CAM SG_ 763 Warn_HoodSwSta_SBCM 1500;
BA_ "NetworkRequest" SG_ 763 Warn_HoodSwSta_SBCM 0;
BA_ "NetworkRequestHoldingTime" SG_ 763 Warn_HoodSwSta_SBCM 5000;
BA_ "Version" SG_ 763 Warn_HoodSwSta_SBCM "21.09.08";
BA_ "Description" SG_ 763 Hood_TypeOption "If the E-Hood is applied, the signal will be send.";
BA_ "GenSigSendType" SG_ 763 Hood_TypeOption 4;
BA_ "UserSigValidity" SG_ 763 Hood_TypeOption 0;
BA_REL_ "GenSigTimeoutTime" BU_SG_REL_ BLTN_CAM SG_ 763 Hood_TypeOption 1500;
BA_ "NetworkRequest" SG_ 763 Hood_TypeOption 0;
BA_ "NetworkRequestHoldingTime" SG_ 763 Hood_TypeOption 5000;
BA_ "Version" SG_ 763 Hood_TypeOption "22.03.01";
BA_ "GenSigSendType" SG_ 763 SBCM_FrunkSta 4;
BA_ "UserSigValidity" SG_ 763 SBCM_FrunkSta 0;
BA_ "NetworkRequest" SG_ 763 SBCM_FrunkSta 0;
BA_ "NetworkRequestHoldingTime" SG_ 763 SBCM_FrunkSta 5000;
BA_ "Version" SG_ 763 SBCM_FrunkSta "22.01.06";
BA_ "GenSigSendType" SG_ 763 Warn_HoodSwFullSta_SBCM 4;
BA_ "UserSigValidity" SG_ 763 Warn_HoodSwFullSta_SBCM 0;
BA_ "NetworkRequest" SG_ 763 Warn_HoodSwFullSta_SBCM 0;
BA_ "NetworkRequestHoldingTime" SG_ 763 Warn_HoodSwFullSta_SBCM 5000;
BA_ "Version" SG_ 763 Warn_HoodSwFullSta_SBCM "22.01.06";
BA_ "GenSigSendType" SG_ 763 FrunkWarning_SBCM 4;
BA_ "UserSigValidity" SG_ 763 FrunkWarning_SBCM 0;
BA_ "NetworkRequest" SG_ 763 FrunkWarning_SBCM 0;
BA_ "NetworkRequestHoldingTime" SG_ 763 FrunkWarning_SBCM 5000;
BA_ "Version" SG_ 763 FrunkWarning_SBCM "22.03.01";
BA_ "Description" SG_ 763 SBCM_Longkey_DRVDrAtClsSwSta "FCS Power Door Long key Status";
BA_ "GenSigSendType" SG_ 763 SBCM_Longkey_DRVDrAtClsSwSta 4;
BA_ "UserSigValidity" SG_ 763 SBCM_Longkey_DRVDrAtClsSwSta 0;
BA_ "NetworkRequest" SG_ 763 SBCM_Longkey_DRVDrAtClsSwSta 0;
BA_ "NetworkRequestHoldingTime" SG_ 763 SBCM_Longkey_DRVDrAtClsSwSta 5000;
BA_ "Version" SG_ 763 SBCM_Longkey_DRVDrAtClsSwSta "22.04.02";
BA_ "GenSigSendType" SG_ 763 PwrDRClosingDRVDrSta 4;
BA_ "UserSigValidity" SG_ 763 PwrDRClosingDRVDrSta 0;
BA_ "NetworkRequest" SG_ 763 PwrDRClosingDRVDrSta 0;
BA_ "NetworkRequestHoldingTime" SG_ 763 PwrDRClosingDRVDrSta 5000;
BA_ "Version" SG_ 763 PwrDRClosingDRVDrSta "22.04.01";
BA_ "GenSigSendType" SG_ 763 Drv_DrLkRetryFail_SBCM 4;
BA_ "TimeoutValue" SG_ 763 Drv_DrLkRetryFail_SBCM "0x0";
BA_ "UserSigValidity" SG_ 763 Drv_DrLkRetryFail_SBCM 0;
BA_ "NetworkRequest" SG_ 763 Drv_DrLkRetryFail_SBCM 0;
BA_ "NetworkRequestHoldingTime" SG_ 763 Drv_DrLkRetryFail_SBCM 5000;
BA_ "Version" SG_ 763 Drv_DrLkRetryFail_SBCM "23.03.00";
BA_ "Description" SG_ 763 CDM_GbtImmeChgSw_SBCM "State of Immediate Charging Switch";
BA_ "GenSigSendType" SG_ 763 CDM_GbtImmeChgSw_SBCM 4;
BA_ "UserSigValidity" SG_ 763 CDM_GbtImmeChgSw_SBCM 0;
BA_ "Version" SG_ 763 CDM_GbtImmeChgSw_SBCM "23.04.02";
BA_ "Description" SG_ 763 CDM_GbtOpnClsState_SBCM "This signal indicates CDM Open/Close Status(Gbt)";
BA_ "GenSigSendType" SG_ 763 CDM_GbtOpnClsState_SBCM 4;
BA_ "UserSigValidity" SG_ 763 CDM_GbtOpnClsState_SBCM 0;
BA_ "Version" SG_ 763 CDM_GbtOpnClsState_SBCM "23.04.02";
BA_ "Description" SG_ 763 CDM_GbtWarnMsg_SBCM "Command for CDM Warning on cluster(Gbt)";
BA_ "GenSigSendType" SG_ 763 CDM_GbtWarnMsg_SBCM 4;
BA_ "UserSigValidity" SG_ 763 CDM_GbtWarnMsg_SBCM 0;
BA_ "Version" SG_ 763 CDM_GbtWarnMsg_SBCM "23.04.02";
BA_ "Description" SG_ 763 DoorLock_DrvLkOutSta_SBCM "- Door Lock or Unlock Output State 

0x0 : Off (Door lock/unlock output Off state)

0x1 : On (Door lock/unlock output On state)";
BA_ "GenSigSendType" SG_ 763 DoorLock_DrvLkOutSta_SBCM 4;
BA_ "UserSigValidity" SG_ 763 DoorLock_DrvLkOutSta_SBCM 0;
BA_ "NetworkRequest" SG_ 763 DoorLock_DrvLkOutSta_SBCM 0;
BA_ "NetworkRequestHoldingTime" SG_ 763 DoorLock_DrvLkOutSta_SBCM 5000;
BA_ "Version" SG_ 763 DoorLock_DrvLkOutSta_SBCM "23.02.09";
BA_ "GenSigSendType" SG_ 763 CDM_InsideOpnSwSta 4;
BA_ "UserSigValidity" SG_ 763 CDM_InsideOpnSwSta 7;
BA_ "NetworkRequest" SG_ 763 CDM_InsideOpnSwSta 0;
BA_ "NetworkRequestHoldingTime" SG_ 763 CDM_InsideOpnSwSta 5000;
BA_ "Version" SG_ 763 CDM_InsideOpnSwSta "21.07.07";
BA_ "GenMsgSendType" BO_ 742 0;
BA_ "Description" SG_ 742 SGU_OptTyp "This signal indicates if smart glass is installed and whta kind of smart glass is.

bit0 : Smart Glass Installation

bit1 : Smart Roof Glass

bit2 : Rear Smart Door Glass

bit3~bit7 : Reserved";
BA_ "GenSigSendType" SG_ 742 SGU_OptTyp 4;
BA_ "UserSigValidity" SG_ 742 SGU_OptTyp 0;
BA_ "RoutingFactor" SG_ 742 SGU_OptTyp 0;
BA_ "Version" SG_ 742 SGU_OptTyp "21.06.12";
BA_ "Description" SG_ 742 SGU_FltSta "SGU Fault Status";
BA_ "GenSigSendType" SG_ 742 SGU_FltSta 4;
BA_ "UserSigValidity" SG_ 742 SGU_FltSta 0;
BA_ "RoutingFactor" SG_ 742 SGU_FltSta 0;
BA_ "Version" SG_ 742 SGU_FltSta "21.07.04";
BA_ "Description" SG_ 742 SGU_BlindOnOffSet "Roll Blind Open/Close Control Set Value";
BA_ "GenSigSendType" SG_ 742 SGU_BlindOnOffSet 4;
BA_ "UserSigValidity" SG_ 742 SGU_BlindOnOffSet 0;
BA_REL_ "GenSigTimeoutTime" BU_SG_REL_ CGW_CCU SG_ 742 SGU_BlindOnOffSet 1500;
BA_ "RoutingFactor" SG_ 742 SGU_BlindOnOffSet 0;
BA_ "Version" SG_ 742 SGU_BlindOnOffSet "21.07.05";
BA_ "Description" SG_ 742 SGU_BlindOpenReq "This signal is for controlling a blind when SGU controls transparency of smart glass.";
BA_ "GenSigSendType" SG_ 742 SGU_BlindOpenReq 4;
BA_ "UserSigValidity" SG_ 742 SGU_BlindOpenReq 0;
BA_REL_ "GenSigTimeoutTime" BU_SG_REL_ RCM SG_ 742 SGU_BlindOpenReq 1500;
BA_ "RoutingFactor" SG_ 742 SGU_BlindOpenReq 0;
BA_ "Version" SG_ 742 SGU_BlindOpenReq "21.09.05";
BA_ "Description" SG_ 742 SGU_FltVal "SGU Fault Value";
BA_ "GenSigSendType" SG_ 742 SGU_FltVal 4;
BA_ "UserSigValidity" SG_ 742 SGU_FltVal 0;
BA_ "RoutingFactor" SG_ 742 SGU_FltVal 0;
BA_ "Version" SG_ 742 SGU_FltVal "21.07.04";
BA_ "Description" SG_ 742 SGU_Roof_OprLv "Roof Smart Glass Operation Level";
BA_ "GenSigSendType" SG_ 742 SGU_Roof_OprLv 4;
BA_ "UserSigValidity" SG_ 742 SGU_Roof_OprLv 0;
BA_REL_ "GenSigTimeoutTime" BU_SG_REL_ CGW_CCU SG_ 742 SGU_Roof_OprLv 1500;
BA_ "RoutingFactor" SG_ 742 SGU_Roof_OprLv 0;
BA_ "Version" SG_ 742 SGU_Roof_OprLv "21.09.00";
BA_ "Description" SG_ 742 SGU_2ndLeftDoor_OprLv "2nd Row Left Door Smart Glass Operation Level";
BA_ "GenSigSendType" SG_ 742 SGU_2ndLeftDoor_OprLv 4;
BA_ "UserSigValidity" SG_ 742 SGU_2ndLeftDoor_OprLv 0;
BA_REL_ "GenSigTimeoutTime" BU_SG_REL_ CGW_CCU SG_ 742 SGU_2ndLeftDoor_OprLv 1500;
BA_ "RoutingFactor" SG_ 742 SGU_2ndLeftDoor_OprLv 0;
BA_ "Version" SG_ 742 SGU_2ndLeftDoor_OprLv "21.09.00";
BA_ "Description" SG_ 742 SGU_2ndRightDoor_OprLv "2nd Row Right Door Smart Glass Operation Level";
BA_ "GenSigSendType" SG_ 742 SGU_2ndRightDoor_OprLv 4;
BA_ "UserSigValidity" SG_ 742 SGU_2ndRightDoor_OprLv 0;
BA_REL_ "GenSigTimeoutTime" BU_SG_REL_ CGW_CCU SG_ 742 SGU_2ndRightDoor_OprLv 1500;
BA_ "RoutingFactor" SG_ 742 SGU_2ndRightDoor_OprLv 0;
BA_ "Version" SG_ 742 SGU_2ndRightDoor_OprLv "21.09.00";
BA_ "Description" SG_ 742 SGU_3rdLeftDoor_OprLv "3rd Row Left Door Smart Glass Operation Level";
BA_ "GenSigSendType" SG_ 742 SGU_3rdLeftDoor_OprLv 4;
BA_ "UserSigValidity" SG_ 742 SGU_3rdLeftDoor_OprLv 0;
BA_REL_ "GenSigTimeoutTime" BU_SG_REL_ CGW_CCU SG_ 742 SGU_3rdLeftDoor_OprLv 1500;
BA_ "RoutingFactor" SG_ 742 SGU_3rdLeftDoor_OprLv 0;
BA_ "Version" SG_ 742 SGU_3rdLeftDoor_OprLv "21.09.00";
BA_ "Description" SG_ 742 SGU_3rdRightDoor_OprLv "3rd Row Right Door Smart Glass Operation Level";
BA_ "GenSigSendType" SG_ 742 SGU_3rdRightDoor_OprLv 4;
BA_ "UserSigValidity" SG_ 742 SGU_3rdRightDoor_OprLv 0;
BA_REL_ "GenSigTimeoutTime" BU_SG_REL_ CGW_CCU SG_ 742 SGU_3rdRightDoor_OprLv 1500;
BA_ "RoutingFactor" SG_ 742 SGU_3rdRightDoor_OprLv 0;
BA_ "Version" SG_ 742 SGU_3rdRightDoor_OprLv "21.09.00";
BA_ "Description" SG_ 742 SGU_RearWindow_OprLv "Rear Window Smart Glass Operation Level";
BA_ "GenSigSendType" SG_ 742 SGU_RearWindow_OprLv 4;
BA_ "UserSigValidity" SG_ 742 SGU_RearWindow_OprLv 0;
BA_REL_ "GenSigTimeoutTime" BU_SG_REL_ CGW_CCU SG_ 742 SGU_RearWindow_OprLv 1500;
BA_ "RoutingFactor" SG_ 742 SGU_RearWindow_OprLv 0;
BA_ "Version" SG_ 742 SGU_RearWindow_OprLv "21.09.00";
BA_ "Description" SG_ 742 SGU_OprLvVehicleSet "Smart Glass Maximum Operation Level Setting Value for each vechicles";
BA_ "GenSigSendType" SG_ 742 SGU_OprLvVehicleSet 4;
BA_ "UserSigValidity" SG_ 742 SGU_OprLvVehicleSet 0;
BA_REL_ "GenSigTimeoutTime" BU_SG_REL_ CGW_CCU SG_ 742 SGU_OprLvVehicleSet 1500;
BA_ "RoutingFactor" SG_ 742 SGU_OprLvVehicleSet 0;
BA_ "Version" SG_ 742 SGU_OprLvVehicleSet "21.11.05";
BA_ "Description" SG_ 742 SGU_CH1_VoltageVal "SGU Channel 1 AC Voltage Value

0x0~0x3B:Valid Range  (AC Voltage Value 0.0 ~ 6.0V)

0x0~0x40:Not Used";
BA_ "GenSigSendType" SG_ 742 SGU_CH1_VoltageVal 4;
BA_ "UserSigValidity" SG_ 742 SGU_CH1_VoltageVal 0;
BA_ "RoutingFactor" SG_ 742 SGU_CH1_VoltageVal 0;
BA_ "Version" SG_ 742 SGU_CH1_VoltageVal "22.05.03";
BA_ "Description" SG_ 742 SGU_CH2_VoltageVal "SGU Channel 2 AC Voltage Value

0x0~0x3B:Valid Range  (AC Voltage Value 0.0 ~ 6.0V)

0x0~0x40:Not Used";
BA_ "GenSigSendType" SG_ 742 SGU_CH2_VoltageVal 4;
BA_ "UserSigValidity" SG_ 742 SGU_CH2_VoltageVal 0;
BA_ "RoutingFactor" SG_ 742 SGU_CH2_VoltageVal 0;
BA_ "Version" SG_ 742 SGU_CH2_VoltageVal "22.05.03";
BA_ "Description" SG_ 742 SGU_RdySta "SGU Ready Status";
BA_ "GenSigSendType" SG_ 742 SGU_RdySta 4;
BA_ "UserSigValidity" SG_ 742 SGU_RdySta 0;
BA_ "RoutingFactor" SG_ 742 SGU_RdySta 0;
BA_ "Version" SG_ 742 SGU_RdySta "21.07.04";
VAL_ 694 ASAU_NotFootMsgOperStaWarn 0 "OFF" 1 "ON" 2 "Reserved" 3 "Reserved" ;
VAL_ 2344811009 BMS_Crc2Val 0 "0x0x0~0xFFFF:CRCValue" 65535 "0x0x0~0xFFFF:CRCValue" ;
VAL_ 2344811009 BMS_AlvCnt2Val 0 "0x0x0~0xFF:AlvCntValue" 255 "0x0x0~0xFF:AlvCntValue" ;
VAL_ 2344811009 xEV_SrvLmpReq 0 "Off" 1 "Service Lamp On" 2 "Not used" 3 "Error indicator" ;
VAL_ 2344811009 xEV_MainRlyOnSta 0 "Open" 1 "Close" 2 "Not used" 3 "Error indicator" ;
VAL_ 2344811009 xEV_SysFltSta 0 "Normal" 1 "Fault" 2 "Not used" 3 "Error indicator" ;
VAL_ 2344811009 EV_Unreliable_SOC 0 "Normal" 1 "Warning(30%)" 2 "Warning(70%)" 3 "Fault(100%)" ;
VAL_ 2344811009 xEV_InltTempVal 127 "Error value" ;
VAL_ 2344811009 xEV_MinBattCelVoltVal 255 "Error indicator" ;
VAL_ 2344811009 xEV_MaxBattCelVoltVal 255 "Error indicator" ;
VAL_ 2344811010 xEV_BattCurrVal 32767 "Error indicator" ;
VAL_ 2344811010 xEV_MinBattTempVal 127 "Error indicator" ;
VAL_ 2344811010 xEV_MaxBattTempVal 127 "Error indicator" ;
VAL_ 2344811010 xEV_FanSpdStpSta 0 "None" 1 "1step" 2 "2step" 3 "3step" 4 "4step" 5 "5step" 6 "6step" 7 "7step" 8 "8step" 9 "9step" ;
VAL_ 2344811010 xEV_12VRlyOffAlrmReq 0 "Normal" 1 "Pop up Request" 2 "Not used" 3 "Error indicator" ;
VAL_ 2344811010 xEV_12VRlyOnAlrmReq 0 "Normal" 1 "Pop up Request" 2 "Not used" 3 "Error indicator" ;
VAL_ 2344811010 xEV_SocDis 255 "Error value" ;
VAL_ 2344811011 xEV_12VAlarmReqForICU 0 "Normal" 1 "3rd cut off" 2 "Warn. msg & 3rd cut off req" 3 "reserved" ;
VAL_ 2344811011 xEV_AuxBattChrgReq 0 "Charge Finish Request" 1 "LV2 Charge Request" 2 "LV1 Charge Request" 3 "Error Indicator" ;
VAL_ 2344811011 xEV_12VDarkCurrAlarmForICU 0 "Normal" 1 "Alarm Flag set" 2 "Not used" 3 "Error indicator" ;
VAL_ 2344811011 xEV_12VBatVLmt 255 "Error indicator" ;
VAL_ 2344811011 xEV_CharBatInfoReqForSDC 0 "Default(no request)" 1 "High volt bat. First" 2 "12 volt bat. First" 3 "Both of them possible" ;
VAL_ 2344811011 xEV_ClimateOffReq 0 "Default" 1 "Flag set" 2 "Not used" 3 "Error indicator" ;
VAL_ 2344811011 xEV_MainRlyOnRetrySta 0 "Normal" 1 "Relay ON Retry Operation" 2 "Not used" 3 "Error indicator" ;
VAL_ 2344811011 xEV_Bms_BlackBox_Data_req 0 "Default" 1 "Data Save Req (Isolation)" 2 "Data Set Clear" 3 "Error Indicator" ;
VAL_ 2344811011 xEV_12V_BatDchCurrLmt 255 "Error indicator" ;
VAL_ 2344811011 xEV_12VChargeReq 0 "Not Request(Normal)" 1 "Request" 2 "Not used" 3 "Error indicator" ;
VAL_ 2344811011 xEV_BmsRomType 0 "No Definition" 1 "Normal Battery Pack with Heater System" 2 "Normal Battery Pack without Heater System" 3 "Economy Battery Pack with Heater System" 4 "Economy Battery Pack without Heater System" 5 "Extented Battery Pack with Heater System" 6 "Extented Battery Pack without Heater System" 7 "Performance Battery Pack (Heater or Non Heater)" ;
VAL_ 2344811011 xEV_12V_CurrFltDetectReq 0 "Normal" 1 "Request" 2 "Not used" 3 "Error indicator" ;
VAL_ 2344811011 xEV_PRATempSnsVal_ 127 "Error indicator" ;
VAL_ 2344811011 xEV_PRATempSns2Val_ 127 "Error indicator" ;
VAL_ 2344811011 xEV_12VRlyOnSwReq 0 "Normal" 1 "Request" 2 "Not used" 3 "Error indicator" ;
VAL_ 2344811012 xEV_Bms_IsolDetDeactFuncSta 0 "Function disabled state" 1 "Functional activated state" 2 "Not used" 3 "Error indicator" ;
VAL_ 2344811012 xEV_Bms_CellBalDeactFuncSta 0 "Function disabled state" 1 "Functional activated state" 2 "Not used" 3 "Error indicator" ;
VAL_ 2344811012 xEV_BMS_SOC_2nd 65535 "Error Value" ;
VAL_ 2315421697 CCU_AP_OTA_Crc1Val 0 "0x0x0~0xFFFF:CRCValue" 65535 "0x0x0~0xFFFF:CRCValue" ;
VAL_ 2315421697 CCU_AP_OTA_AlvCnt1Val 0 "0x0x0~0xFF:AlvCntValue" 255 "0x0x0~0xFF:AlvCntValue" ;
VAL_ 2315421697 CCU_OTA_mode 0 "idle" 1 "Download" 2 "BackgroundSend" 3 "UpdateReady_bf_apv" 4 "UpdateReady_af_apv" 5 "Update_preprocess" 6 "Update_PE" 7 "Update_other" ;
VAL_ 2315421697 CCU_OTA_IG3On_request 0 "off(Default)" 1 "on" 2 "Not used" 3 "Error Indicator" ;
VAL_ 2315421697 OTA_Cond_Vehicle_Pwr 0 "NoDisplay" 1 "OK" 2 "NOK" 3 "Reserved" ;
VAL_ 2315421697 OTA_Cond_Gear_P 0 "NoDisplay" 1 "OK" 2 "NOK" 3 "Reserved" ;
VAL_ 2315421697 OTA_Cond_Parking_Brk 0 "NoDisplay" 1 "OK" 2 "NOK" 3 "Reserved" ;
VAL_ 2315421697 OTA_Cond_Ext_Lamp 0 "NoDisplay" 1 "OK" 2 "NOK" 3 "Reserved" ;
VAL_ 2315421697 OTA_Cond_Hood_Closed 0 "NoDisplay" 1 "OK" 2 "NOK" 3 "Reserved" ;
VAL_ 2315421697 CCU_OTA_Cond_Request 0 "No Request" 1 "Request" 2 "Not Used" 3 "Error Indicator" ;
VAL_ 2315421697 CCU_OTA_Tele_Cranking 0 "default (off)" 1 "IGN1 on, Cranking" 2 "IGN1 on" 3 "Stop" 7 "Error Indicator" ;
VAL_ 2315421697 OTA_UI_Ready_request 0 "off (default)" 1 "ON" 2 "Not Used" 3 "Error Indicator" ;
VAL_ 2315421697 OTA_Result 0 "Default" 1 "Success" 2 "failed_rollback_complete" 3 "failed_rollback_failed" ;
VAL_ 2315421697 CF_AVN_InterAutoLockMode_Set2_Copy_1 0 "Default" 1 "Auto Mode" 2 "Lock Mode" 3 "Unlock Mode" 4 "Reserved" 5 "Reserved" 6 "Reserved" 7 "Invalid" ;
VAL_ 2315421697 CCU_OTA_EOU 0 "OFF" 1 "ON" 2 "Reserved" 3 "Invalid" ;
VAL_ 2290230529 CLU_Crc2Val 0 "0x0x0~0xFFFF:CRCValue" 65535 "0x0x0~0xFFFF:CRCValue" ;
VAL_ 2290230529 CLU_AlvCnt2Val 0 "0x0x0~0xFF:AlvCntValue" 255 "0x0x0~0xFF:AlvCntValue" ;
VAL_ 2290230529 CLU_DTEVal 0 "Valid DTE 0 (Display '---')" 1 "0x1~0xFFE:Valid DTE (1 ~ 4094 km)" 4094 "0x1~0xFFE:Valid DTE (1 ~ 4094 km)" 4095 "Invalid(Display '---' Blink)" ;
VAL_ 2290230529 CLU_TripUnitSta 0 "Not Used" 1 "km" 2 "mile" 3 "Invailid" ;
VAL_ 2290230529 CLU_LoFuelWrngSta 0 "Low fuel Warning is off" 1 "Low fuel Warning is on" 2 "Not used" 3 "Invalid" ;
VAL_ 2290230529 CLU_RefuelDetSta 0 "Non refuel detected" 1 "Refuel detected" 2 "Not used" 3 "Error Indicator" ;
VAL_ 2290230529 CLU_TerrainMainSwSta 0 "Default" 1 "On-Road" 2 "Off-Road" 3 "Reserved" ;
VAL_ 2290230530 CLU_RefuelWrnSta 0 "Refuel Popup is off" 1 "Refuel Popup is on" 2 "Reserved" 3 "Invalid" ;
VAL_ 2290230530 CLU_DrvngModSwSta 0 "Off" 1 "Normal" 2 "Eco" 3 "Sport" 4 "Sport+" 5 "Smart" 6 "Custom(Custom#1_N)" 7 "N-mode" 8 "Reserved" 9 "Custom#2_N" 10 "Reserved" 11 "Reserved" 12 "Reserved" 13 "Reserved" 14 "Reserved" 15 "Invalid" ;
VAL_ 2290230530 CLU_FuelLvlSta 0 "0x0x0~0x64:0%~100%" 100 "0x0x0~0x64:0%~100%" 101 "Reserved" 102 "Reserved" 103 "Reserved" 104 "Reserved" 105 "Reserved" 106 "Reserved" 107 "Reserved" 108 "Reserved" 109 "Reserved" 110 "Reserved" 111 "Reserved" 112 "Reserved" 113 "Reserved" 114 "Reserved" 115 "Reserved" 116 "Reserved" 117 "Reserved" 118 "Reserved" 119 "Reserved" 120 "Reserved" 121 "Reserved" 122 "Reserved" 123 "Reserved" 124 "Reserved" 125 "Reserved" 126 "Reserved" 127 "Invalid(Error)" ;
VAL_ 2290230530 CLU_SRSWrngLmpSta 0 "Lamp OFF" 1 "Lamp On" 2 "Lamp Flashing" 3 "ACU message error" 6 "Initialization" 7 "Lamp Circuit Failure" ;
VAL_ 2290230530 CLU_TerrainModSwSta 0 "Default" 1 "Snow" 2 "Sand" 3 "Mud" 4 "Auto" 5 "Deep Snow" 6 "Reserved" 7 "Reserved" ;
VAL_ 2290230530 CLU_OdoVal 16777215 "Error" ;
VAL_ 2470763009 CLU_Crc9Val 0 "0x0x0~0xFFFF:CRCValue" 65535 "0x0x0~0xFFFF:CRCValue" ;
VAL_ 2470763009 CLU_AlvCnt9Val 0 "0x0x0~0xFF:AlvCntValue" 255 "0x0x0~0xFF:AlvCntValue" ;
VAL_ 2470763009 USM_MdLmpClrSetReq 0 "Default" 1 "color 1" 2 "color 2" 3 "color 3" 4 "color 4" 5 "color 5" 6 "color 6" 7 "color 7" 8 "color 8" 9 "color 9" 10 "color 10" 11 "reserved" 12 "reserved" 13 "reserved" 14 "reserved" 15 "Invalid" ;
VAL_ 2470763009 USM_RrWiperRevSetReq 0 "Default" 1 "Rear Wiper(reverse) Off" 2 "Rear Wiper(reverse) On" 3 "Invalid" ;
VAL_ 2470763009 USM_RrStRemindSetReq 0 "Default" 1 "Off(Disable)" 2 "On(Enable)" 3 "Invalid" ;
VAL_ 2470763009 USM_RrWpcSetReq 0 "Default" 1 "Off(Disable)" 2 "On(Enable)" 3 "Invalid" ;
VAL_ 2470763009 USM_WpcSetReq 0 "Default" 1 "Off(Disable)" 2 "On(Enable)" 3 "Invalid" ;
VAL_ 2470763009 USM_SeqLmpSetReq 0 "Default" 1 "Off" 2 "On" 3 "Invalid" ;
VAL_ 2470763009 USM_UnlckWlcmSetReq 0 "Default Value" 1 "Off" 2 "On" 3 "Invalid" ;
VAL_ 2470763009 USM_SmrtWlcmSetReq 0 "Default Value" 1 "Off" 2 "On" 3 "Invalid" ;
VAL_ 2470763009 USM_UipSetReq 0 "Default(USM¹Ì±¸¼º)" 1 "Off(Disable)" 2 "On(Enable)" 3 "Invalid" ;
VAL_ 2470763009 USM_DigitalKeyEnblSetReq 0 "Default(¹Ì±¸¼º)" 1 "Disable" 2 "Enable" 3 "Invalid" ;
VAL_ 2470763009 USM_OwnerPhnRegSetReq 0 "Default(¹Ì±¸¼º)" 1 "Deleter" 2 "Register" 3 "Invalid" ;
VAL_ 2470763009 USM_NFCCard1RegSetReq 0 "Default(¹Ì±¸¼º)" 1 "Disable" 2 "Enable" 3 "Invalid" ;
VAL_ 2470763009 USM_NFCCard2RegSetReq 0 "Default(¹Ì±¸¼º)" 1 "Disable" 2 "Enable" 3 "Invalid" ;
VAL_ 2470763009 USM_ProcStpReq 0 "Default" 1 "StopReq" ;
VAL_ 2470763009 USM_PwrAutoOffTimeSetReq 0 "Default" 1 "Timer1" 2 "Timer2" 3 "Timer3" 4 "Timer4" 5 "Reserved" 6 "Reserved" 7 "Invalid" ;
VAL_ 2470763009 USM_RrStRemindSetReq_RestMode 0 "Default" 1 "Off(Disable)" 2 "On(Enable)" 3 "Invalid" 4 "Reserved" 5 "Reserved" 6 "Not Used" 7 "Error Indicator" ;
VAL_ 2470763009 USM_1stRrStRemindSetReq 0 "Default" 1 "Off(Disable)" 2 "On(Enable)" 3 "Invalid" ;
VAL_ 2470763009 USM_Wpc2SetReq 0 "Default" 1 "Off(Disable)" 2 "On(Enable)" 3 "Invalid" ;
VAL_ 2231452929 DATC_Crc1Val 0 "0x0x0~0xFFFF:CRCValue" 65535 "0x0x0~0xFFFF:CRCValue" ;
VAL_ 2231452929 DATC_AlvCnt1Val 0 "0x0x0~0xFF:AlvCntValue" 255 "0x0x0~0xFF:AlvCntValue" ;
VAL_ 2231452929 DATC_PtcRlySta 0 "PTC OFF" 1 "PTC ON Lv1" 2 "PTC ON Lv1&2" 3 "PTC ON Lv1&2&3" 4 "Not used" 5 "Not used" 6 "Not used" 7 "Error Indicator" ;
VAL_ 2231452929 DATC_ManufacturerTyp 0 "FATC Type 0 (default)" 1 "FATC Type 1 (Doowon)" 2 "FATC Type 2 (Hanon)/0X3:FATC Type 3(DENSO)" 4 "Not used" 5 "Not used" 6 "Not used" 7 "Error Indicator" ;
VAL_ 2231452929 DATC_DatcPwmSts 0 "Default" 1 "PWM Off" 2 "PWM On" 3 "Error Indicator" ;
VAL_ 2231452929 DATC_AcnCompTyp 0 "Internal Compressor" 1 "External Compressor with Comp clutch" 2 "External Compressor without Comp clutch" 3 "Fixed Compressor" 4 "electrical Compressor" 6 "Not used" 7 "Error Indicator" ;
VAL_ 2231452929 DATC_EewpRpmLvlReq 0 "MAX A/C" 1 "LOW" 2 "MID" 3 "HIGH" 4 "Not used" 5 "Not used" 6 "Not used" 7 "Error Indicator" ;
VAL_ 2231452929 DATC_Cooldown 0 "Default" 1 "Initial" 2 "Cool down" 3 "Error Indicator" ;
VAL_ 2231452929 DATC_AcnReq 0 "A/C Non-Request" 1 "A/C Request" 2 "Not used" 3 "Error Indicator" ;
VAL_ 2231452929 DATC_BlwSta 0 "Blower Off" 1 "Blower On" 2 "Not used" 3 "Error Indicator" ;
VAL_ 2231452929 DATC_BlwMaxSta 0 "NOT Max blower speed" 1 "Max blower speed" 2 "Not used" 3 "Error Indicator" ;
VAL_ 2231452929 DATC_EngStrtReq 0 "Engine Not on Request" 1 "Engine Auto Start Request" 2 "Not used" 3 "Error Indicator" ;
VAL_ 2231452929 DATC_IsgInhbtReq 0 "ISG Inhibit Request Off" 1 "ISG Inhibit Request ON" 2 "Not used" 3 "Error Indicator" ;
VAL_ 2231452929 DATC_AcnCompOnReq 0 "A/C COMP Request Off" 1 "A/C COMP Request ON" 2 "Not used" 3 "Error Indicator" ;
VAL_ 2231452929 DATC_SrvLmpReq 0 "Off" 1 "Service Lamp On" 2 "Not used" 3 "Error Indicator" ;
VAL_ 2231452929 DATC_EcvFltSta 0 "Normal(No fault)" 1 "ECV Control Fault" 2 "Not used" 3 "Error Indicator" ;
VAL_ 2231452929 DATC_CalcAcnCompTqVal 254 "Not used" 255 "Error Indicator" ;
VAL_ 2231452930 DATC_AcnECompOpSta 0 "E-Compressor Not-Operation" 1 "E-Compressor Operation" 2 "Not used" 3 "Error Indicator" ;
VAL_ 2231452930 DATC_HVCompIntlkSta 0 "Disconnect" 1 "Connect" 2 "Not used" 3 "Error Indicator" ;
VAL_ 2231452930 DATC_HVIntDischrgLkReq 0 "Not Request" 1 "Request" 2 "Not used" 3 "Error Indicator" ;
VAL_ 2231452930 DATC_AcnECompMaxReqPwrVal 1023 "Error Indicator" ;
VAL_ 2231452930 DATC_AcnCompFltSta 0 "A/C E-Compressor Normal" 1 "A/C E-Compressor Fail" 2 "Not used" 3 "Error Indicator" ;
VAL_ 2231452930 DATC_AcnECompCnsmptPwrVal 1023 "Error Indicator" ;
VAL_ 2231452930 DATC_MainRlyOffReq 0 "Non-Request" 1 "Request" 2 "Not used" 3 "Error Indicator" ;
VAL_ 2231452930 DATC_MixDfgSelSta 0 "Battery FAN Non-on Request" 1 "Battery FAN On Request" 2 "Not used" 3 "Error Indicator" ;
VAL_ 2231452930 DATC_BattChlrVlvSta 0 "Dafault" 1 "OPEN" 2 "CLOSE" 3 "Error Indicator" ;
VAL_ 2231452930 DATC_WaterPmpOnReq 0 "Engine Water Pump Non request" 1 "Engine Water Pump On request" 2 "Not used" 3 "Error Indicator" ;
VAL_ 2231452930 DATC_AcnECompSpdVal 65534 "Not used" 65535 "Error Indicator" ;
VAL_ 2231452930 DATC_AcnCompSlpModCodVal 0 "Normal" 1 "Thermistor open" 2 "Thermister short" 4 "Over torque stall" 8 "Short circuit current" 16 "Driver voltage" 32 "Current measuring" 64 "Max Temperature Gradient" 128 "Internal Error" 255 "Error" ;
VAL_ 2231452931 DATC_AcnCompWaitCodVal 0 "Normal" 1 "Low_Voltage" 2 "High_Voltage" 4 "Over_Heat_Protection" 8 "Over_Loaded" 16 "Over_Current_Protection" 32 "Abnormal(not receiving)" 64 "Missed_Restart" ;
VAL_ 2231452931 DATC_RadFanReq_Duty 254 "EMS Wake Up Req" ;
VAL_ 2231452931 DATC_OutTempSnsrVal 0 "0x0x00~0xC8:-40¡É~60¡É" 200 "0x0x00~0xC8:-40¡É~60¡É" 201 "Reserved" 202 "Reserved" 203 "Reserved" 204 "Reserved" 205 "Reserved" 206 "Reserved" 207 "Reserved" 208 "Reserved" 209 "Reserved" 210 "Reserved" 211 "Reserved" 212 "Reserved" 213 "Reserved" 214 "Reserved" 215 "Reserved" 216 "Reserved" 217 "Reserved" 218 "Reserved" 219 "Reserved" 220 "Reserved" 221 "Reserved" 222 "Reserved" 223 "Reserved" 224 "Reserved" 225 "Reserved" 226 "Reserved" 227 "Reserved" 228 "Reserved" 229 "Reserved" 230 "Reserved" 231 "Reserved" 232 "Reserved" 233 "Reserved" 234 "Reserved" 235 "Reserved" 236 "Reserved" 237 "Reserved" 238 "Reserved" 239 "Reserved" 240 "Reserved" 241 "Reserved" 242 "Reserved" 243 "Reserved" 244 "Reserved" 245 "Reserved" 246 "Reserved" 247 "Reserved" 248 "Reserved" 249 "Reserved" 250 "Reserved" 251 "Reserved" 252 "Reserved" 253 "Reserved" 254 "Default" 255 "Error Indicator" ;
VAL_ 2231452931 DATC_ActvEco 0 "Active ECO Button is not selected" 1 "Active ECO Button is selected" 2 "Not used" 3 "Error Indicator" ;
VAL_ 2231452931 DATC_AUTOActv 0 "Default" 1 "Automatic control is Active" 2 "Not used" 3 "Error Indicator" ;
VAL_ 2231452931 DATC_DfgSw 0 "FRONT DEF switch is not selected" 1 "FRONT DEF switch is selected" 2 "Not Used" 3 "Error Indicator" ;
VAL_ 2231452931 DATC_BattChlrVlv_FltCode 0 "Dafault" 1 "No Error" 2 "Error" 3 "Error Indicator" ;
VAL_ 2231452931 DATC_BattEvapVlvSta 0 "Default" 1 "Valve Off (OPEN)" 2 "Valve On (CLOSE)" 3 "Error Indicator" ;
VAL_ 2231452931 DATC_BattEvapVlv_FltCode 0 "Default" 1 "No Error" 2 "Error" 3 "Error Indicator" ;
VAL_ 2231452931 DATC_Wrmup 0 "Default" 1 "Initial" 2 "Warm Up" 3 "Error Indicator" ;
VAL_ 2231452931 DATC_SSC_EngStrtReq 0 "Normal (Default)" 1 "Engine Auto Start Request" 2 "Reserved" 3 "Error Indicator" ;
VAL_ 2231452932 DATC_SSC_InhbtReq 0 "Normal (Default)" 1 "Inhibit Engine Stop" 2 "Reserved" 3 "Error Indicator" ;
VAL_ 2231452932 DATC_EngIdlRpmUpReq 0 "Off" 1 "A/C Off request" 2 "A/C On request" 3 "A/C On and Engine Speed 1 stage up request" 4 "A/C On and Engine Speed 2 stage up request" 5 "Warmup_Idle RPM_Up" 6 "Reserved" 7 "Error Indicator" ;
VAL_ 2231452932 DATC_MaxBlwVolt 0 "Default" 1 "OFF" 2 "ON (B+)" 3 "Error Indicator" ;
VAL_ 2231452932 DATC_HVACPmpOpSta 0 "Default" 1 "Pump Not Operation" 2 "Pump Operation" 3 "Error Indicator" ;
VAL_ 2231452932 DATC_MildCooldown 0 "Default" 1 "Initial State" 2 "Mild Cooldown" 3 "Error Indicator" ;
VAL_ 2231452932 DATC_MildWrmup 0 "Default" 1 "Initial" 2 "Mild Warm Up" 3 "Error Indicator" ;
VAL_ 2231452932 DATC_BlwrLvl 0 "OFF" 1 "0 level" 2 "1 level" 3 "2 level" 4 "3 level" 5 "4 level" 6 "5 level" 7 "6 level" 8 "7 evel" 9 "8 level" 10 "Reserved" 11 "Reserved" 12 "Reserved" 13 "Reserved" 14 "Reserved" 15 "Error Indicator" ;
VAL_ 2231452932 DATC_AAFOpenReq 0 "Default" 1 "1 st" 2 "2 nd" 3 "Open" 4 "Reserved" 5 "Reserved" 6 "Reserved" 7 "Error indicator" ;
VAL_ 2231452932 DATC_BlwSta_Rr 0 "Blower Off(Default)" 1 "Blower On" 2 "RESERVED" 3 "Error Indicator" ;
VAL_ 2231452932 DATC_BattEwpOpReq 255 "Error Indicator" ;
VAL_ 2382594561 DATC_Crc5Val 0 "0x0x0~0xFFFF:CRCValue" 65535 "0x0x0~0xFFFF:CRCValue" ;
VAL_ 2382594561 DATC_AlvCnt5Val 0 "0x0x0~0xFF:AlvCntValue" 255 "0x0x0~0xFF:AlvCntValue" ;
VAL_ 2382594561 DATC_FrDrvModDis 0 "Off(Blank Display, ÅäÃâ¸ðµå ¹ÌÇ¥½Ã ¿¹) Auto ½Ã)" 1 "VENT" 2 "B_L" 3 "FLOOR" 4 "MIX (7 MODE DEF FLOOR)" 5 "DEF (MAX DEF)" 6 "AUTO DEFOG" 7 "7 MODE DEF VENT" 8 "MODE AUTO" 9 "7 MODE DEF VENT FLOOR" 10 "7 MODE DEF" 11 "DEF VENT (Arrow)" 12 "DEF FLOOR (Arrow)" 13 "DEF VENT FLOOR (Arrow)" 14 "DEF (Arrow)" 15 "Error Indicator" ;
VAL_ 2382594561 DATC_FrPassModDis 0 "Off(Blank Display, ÅäÃâ¸ðµå ¹ÌÇ¥½Ã ¿¹) Auto ½Ã)" 1 "VENT" 2 "B_L" 3 "FLOOR" 4 "MIX (7 MODE DEF FLOOR)" 5 "DEF (MAX DEF)" 6 "AUTO DEFOG" 7 "7 MODE DEF VENT" 8 "MODE AUTO" 9 "7 MODE DEF VENT FLOOR" 10 "7 MODE DEF" 11 "DEF VENT (Arrow)" 12 "DEF FLOOR (Arrow)" 13 "DEF VENT FLOOR (Arrow)" 14 "DEF (Arrow)" 15 "Error Indicator" ;
VAL_ 2382594561 DATC_ClmtTxtPopupOSD 0 "Default" 1 "AirCleaning SYS ON" 2 "AirCleaning SYS OFF" 3 "High Dust AirCleaning ON" 4 "High Dust AirCleaning OFF" 5 "Sensor AirCleaning SYS ON & Closing Window" 6 "Opening Warning" 7 "Auto AirCleaning SYS ON" 8 "Smart Ventilation On" 9 "Washer Intake On" 10 "Rear Climate OFF by ROA" 11 "0x0B~0xFE:Reserved" 254 "0x0B~0xFE:Reserved" 255 "Error Indicator" ;
VAL_ 2382594561 DATC_TempDispUnitSta 0 "Centigrade(¡É)" 1 "Fahrenheit(¢µ)" 2 "Not used" 3 "Error Indicator" ;
VAL_ 2382594561 DATC_DrvAutoDis 0 "AUTO Off" 1 "AUTO On" 2 "Not used" 3 "Error Indicator" ;
VAL_ 2382594561 DATC_FrChgReqDis 0 "OFF" 1 "User Input" 2 "Not used" 3 "Error Indicator" ;
VAL_ 2382594561 DATC_FrClmtScrnDis 0 "Deactived" 1 "Actived" 2 "Not used" 3 "Error Indicator" ;
VAL_ 2382594561 DATC_AcDis 0 "A/C Off" 1 "A/C ON" 2 "Not used" 3 "Error Indicator" ;
VAL_ 2382594561 DATC_IntakeSta 0 "Default" 1 "REC (Fresh off)" 2 "FRE (REC off)" 3 "Error Indicator" ;
VAL_ 2382594561 DATC_TempDrLvl 0 "Default" 1 "Max Cool" 2 "Cool2" 3 "Cool1" 4 "Warm1" 5 "Warm2" 6 "Max Hot" 7 "Not Used" 8 "Not Used" 9 "Not Used" 10 "Not Used" 11 "Not Used" 12 "Not Used" 13 "Not Used" 14 "Not Used" 15 "Error Indicator" ;
VAL_ 649 DLBCU_SmartCtrl_1h 0 "Default" 1 "Group1" 2 "Group2" 3 "Group3" 4 "Group4" 5 "Group5" 6 "Group6" 7 "Group7" 8 "Group8" 9 "Group9" 10 "General Group" 11 "RESERVED" 12 "RESERVED" 13 "RESERVED" 14 "RESERVED" 15 "Invalid" ;
VAL_ 649 DLBCU_SmartCtrl_2h 0 "Default" 1 "Group1" 2 "Group2" 3 "Group3" 4 "Group4" 5 "Group5" 6 "Group6" 7 "Group7" 8 "Group8" 9 "Group9" 10 "General Group" 11 "RESERVED" 12 "RESERVED" 13 "RESERVED" 14 "RESERVED" 15 "Invalid" ;
VAL_ 649 DLBCU_SmartCtrl_Status 0 "Default" 1 "Start" 2 "Finished" 3 "Stop" 4 "RESERVED" 5 "RESERVED" 6 "RESERVED" 7 "Invalid" ;
VAL_ 2176872449 HDCT_OBDErrSta 0 "No error" 1 "OBD error" 2 "Not used" 3 "Error Indicator" ;
VAL_ 2176872449 HDCT_StcShftLrchCtrl 0 "No DR or RD lurch control" 1 "DR lurch control active" 2 "RD lurch control active" 3 "Error Indicator" ;
VAL_ 2176872449 HDCT_EngCltchLmphmMod 0 "Inactive" 1 "Active" 2 "Not used" 3 "Error Indicator" ;
VAL_ 2176872449 HDCT_CurrPrgrm 0 "SOS" 1 "ECO" 16 "ACC_NLD" 17 "ACC_LD1" 18 "ACC_LD2" 19 "ACC_LD3" 20 "Manual" 21 "Manual_LD" 22 "CLT_PRT" 23 "TCS_NLD" 24 "TCS_LD" 25 "NORMAL" 26 "ECO_DLD" 27 "DS_DLD" 28 "EVEN" 29 "ODD" 30 "CD (EV Mode)" 31 "Reserve" 2 "DS" 3 "ECO_LD1" 4 "ECO_LD2" 5 "ECO_LD3" 6 "ECO_LD1_HAT" 7 "ECO_LD2_HAT" 8 "ECO_LD3_HAT" 9 "DS_LD1" 10 "DS_LD2" 11 "DS_LD3" 12 "SOC_L" 13 "SOC_N" 14 "SOC_H" 15 "Highway" ;
VAL_ 2176872449 HDCT_FltSta 0 "No fault" 1 "TCU Diagnostic failure" 2 "" 3 "TCU Diagnostic faulure & Limphome activated" 4 "OPU/EOP Diagnostic failure" 5 "" 6 "" 7 "" ;
VAL_ 2176872449 HDCT_MCUAntJrkInhbt 0 "Anti-jerk not inhibit" 1 "Anti-jerk inhibit" 2 "Not used" 3 "Error Indicator" ;
VAL_ 2176872449 HDCT_TrgtGear 0 "If N or P are detected(No frictional conncetion)" 1 "1st speed" 2 "2nd speed" 3 "3rd speed" 4 "4th speed" 5 "5th speed" 6 "6th speed" 15 "Reverse" ;
VAL_ 2176872449 HDCT_CurrGear 0 "if N or P are detected (no frictional connection)" 1 "1st speed" 2 "2nd speed" 3 "3rd speed" 4 "4th speed" 5 "5th speed" 6 "6th speed" 15 "Reverse speed" ;
VAL_ 2176872449 HDCT_GearSelDis 0 "P" 1 "L" 2 "2" 3 "3" 4 "DS Mode (by TGS lever)" 5 "D" 6 "N" 7 "R" 8 "Sports/Manual Mode" 9 "Not display at Cluster" 10 "DS Mode (by Drive Mode button)" 11 "Reserved" 12 "Paddle shift" 13 "Reserved" 14 "Intermediate Position" 15 "Fault" ;
VAL_ 2172675329 IEB_Crc1Val 0 "0x0x0~0xFFFF:CRCValue" 65535 "0x0x0~0xFFFF:CRCValue" ;
VAL_ 2172675329 IEB_AlvCnt1Val 0 "0x0x0~0xFF:AlvCntValue" 255 "0x0x0~0xFF:AlvCntValue" ;
VAL_ 2172675329 IEB_SrvLmpDis 0 "AHB Service Lamp is Off" 1 "AHB Service Lamp is On" 2 "AHB Service Lamp is BLINKING(2HZ)" 3 "Error Indicator" ;
VAL_ 2172675329 IEB_DfctvSta 0 "AHB is normal mode" 1 "AHB is degraded mode" 2 "AHB is defective mode" 3 "Error Indicator" ;
VAL_ 2172675329 IEB_ActvSta 0 "All Control Inactive" 1 "Charging Active" 2 "AHB Control Active" 3 "Chaging Active + AHB Control Active" ;
VAL_ 2172675329 IEB_DiagSta 0 "AHB is not diagnostic mode" 1 "AHB is diagnostic mode" 2 "Not used" 3 "Error Indicator" ;
VAL_ 2172675329 IEB_WrngLmpDis 0 "AHB Warning Lamp is Off" 1 "AHB Warning Lamp is On" 2 "Not used" 3 "Error Indicator" ;
VAL_ 2172675329 IEB_MILReq 0 "No Request" 1 "MIL On Request" 2 "Reserved" 3 "Reserved" ;
VAL_ 2172675329 IEB_DriftModeStaDis 0 "Default" 1 "Restriction state of Drift" 2 "RESERVED" 3 "RESERVED" 4 "RESERVED" 5 "RESERVED" 6 "RESERVED" 7 "RESERVED" ;
VAL_ 2172675329 IEB_BrkActvSta 0 "ECU does not support this function." 1 "Brake switch is not pressed (OFF)" 2 "Brake switch is pressed (ON)" 3 "Brake switch failure" ;
VAL_ 2172675329 IEB_PdlTrvlSnsrFailSta 0 "Normal" 1 "Fail" 2 "Not used" 3 "Error Indicator" ;
VAL_ 2172675329 IEB_PdlCalibSta 0 "Not complete" 1 "Complete" 2 "Not used" 3 "Error Indicator" ;
VAL_ 2172675329 IEB_BzrSta 0 "Buzzer is Off" 1 "Buzzer is On" 2 "Not used" 3 "Error Indicator" ;
VAL_ 2172675330 IEB_Sta 0 "Not Ready" 1 "Ready" 2 "Ready (Front only) & Not Ready(Rear)" 3 "Ready (Rear only) & Not Ready(Front)" ;
VAL_ 2172675330 IEB_SnsrFailSta 0 "Normal" 1 "Fail" 2 "Not used" 3 "Error Indicator" ;
VAL_ 2172675330 IEB_RbsWrngLmpSta 0 "RBS Warning Lamp OFF" 1 "RBS Warning Lamp ON" 2 "Not used" 3 "Error Indicator" ;
VAL_ 2172675330 IEB_AbsNGearReq 0 "Inactive" 1 "N Gear position Request Active" 2 "Not used" 3 "Error Indicator" ;
VAL_ 2172675330 IEB_EstBrkPdlValVldSta 0 "Invalid" 1 "Valid" 2 "Not used" 3 "Error Indicator" ;
VAL_ 2172675330 IEB_VacSysDfctvSta 0 "Vacuum pump NOT defective" 1 "Vacuum pump defective (failed)" 2 "Not used" 3 "Error Indicator" ;
VAL_ 2172675330 IEB_FRAmode_Req 0 "No Request" 1 "Inhibit Transition To 4WD" 2 "Request FRA mode" 3 "Not used" ;
VAL_ 2172675330 IEB_DriftEscModSta_VDC 0 "Default" 1 "Beginner" 2 "Intermediate" 3 "Expert" ;
VAL_ 2172675331 IEB_DrvWhlSlipFlg_Frnt 0 "No slip occurred at the driving wheels" 1 "Slip occurred at the driving wheels" ;
VAL_ 2172675331 IEB_IndDriftMode 0 "Default" 1 "off" 2 "on" 3 "RESERVED" 4 "RESERVED" 5 "RESERVED" 6 "RESERVED" 7 "Invaild" ;
VAL_ 2172675331 IEB_IndDriftEcsModSta 0 "Default" 1 "N-Mode" 2 "Drift Mode" 3 "Reserved" ;
VAL_ 2172675331 IEB_IndDriftElsdModSta 0 "Default" 1 "Drift 1.5 way" 2 "Drift 2.0 way" 3 "Reserved" ;
VAL_ 2172675331 IEB_TCS_Req 0 "TCS control is not active" 1 "TCS control is active by requested TORQUE based" 2 "TCS control is active by requested RPM based" 3 "Not used" ;
VAL_ 2172675331 IEB_RSC_Req 0 "RSC is not active" 1 "RSC is active" 2 "RESERVED" 3 "RESERVED" ;
VAL_ 2172675331 TCS_TqFlag_Frnt 0 "Positive" 1 "Negative" ;
VAL_ 2172675331 TCS_TqFlag_Rear 0 "Positive" 1 "Negative" ;
VAL_ 2172675331 RSC_TqFlag_Frnt 0 "Positive" 1 "Negative" ;
VAL_ 2172675331 RSC_TqFlag_Rear 0 "Positive" 1 "Negative" ;
VAL_ 2172675332 TCS_MtrTrgtRpm_Flag_Frnt 0 "Positive" 1 "Negative" ;
VAL_ 2172675332 TCS_MtrTrgtRpm_Flag_Rear 0 "Positive" 1 "Negative" ;
VAL_ 2172675332 IEB_DriftElsdModSta 0 "Default" 1 "N-Mode" 2 "Drift Mode" 3 "Reserved" ;
VAL_ 2172675332 TCS_MtrTrgtRpm_Rear 0 "0x0x000~0xFFE:Motor RPM Target" 4094 "0x0x000~0xFFE:Motor RPM Target" 4095 "Error Value" ;
VAL_ 2172675332 IEB_DriftModeSta 0 "Default" 1 "Drift Mode Activate (ON)" 2 "Drift Mode Deactivate (OFF)" 3 "Defective" ;
VAL_ 2172675332 IEB_DriftModeActSta 0 "Default" 1 "Drift Mode ON" 2 "Drift Mode OFF" 3 "Reserved" ;
VAL_ 2172675332 MCU_AntiJerk_Inhbtsta 0 "Allow Anti Jerk Control" 1 "Inhibit Anti Jerk control" ;
VAL_ 2172675332 IEB_Motor_ProtectModSta 0 "default" 1 "Protection mode operation" ;
VAL_ 2172675332 IEB_DriftEcsModSta 0 "Default" 1 "N-Mode" 2 "Drift Mode" 3 "Reserved" ;
VAL_ 2172675332 IEB_EstBrkSacFrcNmVal 0 "0x0x0~0xFFFF:friction brake torque for stop assist control" 65535 "0x0x0~0xFFFF:friction brake torque for stop assist control" ;
VAL_ 2172675332 IEB_IndDriftEscModSta_TCS 0 "Default" 1 "Slip level_01" 2 "Slip level_02" 3 "Slip level_03" 4 "Slip level_04" 5 "Slip level_05" 6 "Slip level_06" 7 "Slip level_07" 8 "Slip level_08" 9 "Slip level_09" 10 "Slip level_10" 11 "Reserved" 12 "Reserved" 13 "Reserved" 14 "Reserved" 15 "Reserved" ;
VAL_ 2172675332 IEB_DriftMdpsModSta 0 "Default" 1 "N-Mode" 2 "Drift Mode" 3 "Reserved" ;
VAL_ 2172675332 IEB_IndDriftEscModSta_VDC 0 "Default" 1 "Beginner" 2 "Intermediate" 3 "Expert" ;
VAL_ 2172675332 IEB_IndDriftMdpsModSta 0 "Default" 1 "N-Mode" 2 "Drift Mode" 3 "Reserved" ;
VAL_ 2172675332 TCS_MtrTrgtRpm_Frnt 0 "0x0x000~0xFFE:Motor RPM Target" 4094 "0x0x000~0xFFE:Motor RPM Target" 4095 "Error Value" ;
VAL_ 761 SBCM_AST_Crc3Val 0 "0x0x0~0xFF:CRCValue" 255 "0x0x0~0xFF:CRCValue" ;
VAL_ 761 CDM_TypeOption_AST 0 "Off" 1 "On" 2 "Error Indicator" 3 "RESERVED" ;
VAL_ 761 SBCM_AST_AlvCnt3Val 0 "AlvCntValue" 1 "AlvCntValue" 2 "AlvCntValue" 3 "AlvCntValue" 4 "AlvCntValue" 5 "AlvCntValue" 6 "AlvCntValue" 7 "AlvCntValue" 8 "AlvCntValue" 9 "AlvCntValue" 10 "AlvCntValue" 11 "AlvCntValue" 12 "AlvCntValue" 13 "AlvCntValue" 14 "AlvCntValue" 15 "AlvCntValue" ;
VAL_ 761 CDM_ImmeChgSw_AST 0 "Default" 1 "Off" 2 "On" 3 "RESERVED" ;
VAL_ 761 CDM_ChgDrSwFrt_AST 0 "Default" 1 "Close" 2 "Open" 3 "RESERVED" ;
VAL_ 761 CDM_OpnClsState_AST 0 "Default" 1 "Open" 2 "Close" 3 "RESERVED" ;
VAL_ 761 CDM_WarnMsg_AST 0 "Default" 1 "Normal" 2 "ChargeDoorErrorState" 3 "RESERVED" ;
VAL_ 761 Mirror_RH_FoldingSta 0 "Off" 1 "Folding" 2 "RESERVED" 3 "Error Indicator" ;
VAL_ 761 Mirror_RH_UnfoldingSta 0 "Off" 1 "Unfolding" 2 "RESERVED" 3 "Error Indicator" ;
VAL_ 761 CDM_CmdStatus_AST 0 "Open (AVN)" 1 "Open (SMK)" 2 "Open (Sensor Switch)" 3 "Open (Command Hard Switch)" 4 "Open (Anti - Pinch)" 5 "Close (AVN)" 6 "Close (SMK)" 7 "Close (Assist Mode)" 8 "Close (Command Hard Switch)" 9 "Close (Connector)" 10 "Close (Gear Position)" 11 "Close (Time Over)" 12 "Close (Anti - Pinch)" 13 "Close (Sensor Switch)" 14 "Stall (Stop)" 15 "Invalid" ;
VAL_ 761 AST_CrashMRActAlarm 0 "Off" 1 "On" 2 "RESERVED" 3 "Error Indicator" ;
VAL_ 761 PwrDRBuzzerOut_AST 0 "OFF" 1 "Open" 2 "Close" 3 "Warning" ;
VAL_ 761 IMS_OSMirPlayBackSta_RH 0 "Stop" 1 "Play 1" 2 "Play 2" 3 "Play 3" 4 "Smart IMS" 5 "Profile 1" 6 "Profile 2" 7 "Guest" 8 "RESERVED" 9 "RESERVED" 10 "RESERVED" 11 "RESERVED" 12 "RESERVED" 13 "RESERVED" 14 "RESERVED" 15 "Error Indicator" ;
VAL_ 761 PwrDRClosingASTDrSta 0 "Default" 1 "Close" 2 "Open" 3 "Stop" 4 "RESERVED" 5 "RESERVED" 6 "RESERVED" 7 "Invalid" ;
VAL_ 761 CDM_OutsideOpnSwSta_AST 0 "Default" 1 "Push" 2 "RESERVED" 3 "Invalid" ;
VAL_ 761 SBCM_Longkey_ASTDrAtClsSwSta 0 "Default" 1 "Off" 2 "On" 3 "Error Indicator" ;
VAL_ 761 Hood_TypeOption_AST 0 "Off (Mechanical hood latch is applied)" 1 "On (E-Hood latch is applied)" 2 "RESERVED" 3 "Error Indicator" ;
VAL_ 761 Warn_HoodSwSta_AST 0 "Off" 1 "On" 2 "RESERVED" 3 "Error Indicator" ;
VAL_ 761 FrunkWarning_AST 0 "Off" 1 "On" 2 "RESERVED" 3 "Error Indicator" ;
VAL_ 761 SBCM_FrunkSta_AST 0 "Default" 1 "Valid" 2 "RESERVED" 3 "Error Indicator" ;
VAL_ 761 Ast_DrLkRetryFail_SBCM 0 "Normal" 1 "Fail" 2 "RESERVED" 3 "RESERVED" ;
VAL_ 761 DoorLock_AstLkOutSta_SBCM 0 "Off" 1 "On" 2 "Not Used" 3 "Error Indicator" ;
VAL_ 761 SBCM_AST_DiagSta 0 "Default" 1 "Normal Operation" 2 "AST Indicator Circuit Failure" 3 "RESERVED" ;
VAL_ 758 SBCM_DRV_Crc2Val 0 "0x0x0~0xFF:CRCValue" 255 "0x0x0~0xFF:CRCValue" ;
VAL_ 758 DoorLock_CtrlDrLkUnLkSwSta_SBCM 0 "Off" 1 "On" 2 "RESERVED" 3 "Error Indicator" ;
VAL_ 758 SBCM_DRV_AlvCnt2Val 0 "AlvCntValue" 1 "AlvCntValue" 2 "AlvCntValue" 3 "AlvCntValue" 4 "AlvCntValue" 5 "AlvCntValue" 6 "AlvCntValue" 7 "AlvCntValue" 8 "AlvCntValue" 9 "AlvCntValue" 10 "AlvCntValue" 11 "AlvCntValue" 12 "AlvCntValue" 13 "AlvCntValue" 14 "AlvCntValue" 15 "AlvCntValue" ;
VAL_ 758 SBCM_PsvDrLkReq 0 "None" 1 "Lock" 2 "Passive Trunk Lock" 3 "RESERVED" ;
VAL_ 758 CDMAutoWashModeSet_SBCM 0 "Default" 1 "CDM Auto Wash Mode Off" 2 "CDM Auto Wash Mode On" 3 "RESERVED" 4 "RESERVED" 5 "RESERVED" 6 "RESERVED" 7 "Invalid" ;
VAL_ 758 USM_DrvGhostDoorSta 0 "Default" 1 "Off" 2 "On" 3 "RESERVED" ;
VAL_ 758 Mirror_LH_FoldingSta 0 "Off" 1 "Folding" 2 "RESERVED" 3 "Error Indicator" ;
VAL_ 758 Mirror_LH_UnfoldingSta 0 "Off" 1 "Unfolding" 2 "RESERVED" 3 "Error Indicator" ;
VAL_ 758 DRV_CrashMRActAlarm 0 "Off" 1 "On" 2 "RESERVED" 3 "Error Indicator" ;
VAL_ 758 MirrorFldReq 0 "Default" 1 "Folding Request" 2 "Unfolding Request" 3 "RESERVED" ;
VAL_ 758 OMU_TypeOption_DRV 0 "Off" 1 "On" 2 "RESERVED" 3 "Error Indicator" ;
VAL_ 758 IMS_OSMirPlayBackSta_LH 0 "Stop" 1 "Play 1" 2 "Play 2" 3 "Play 3" 4 "SmartIMS" 5 "Profile 1" 6 "Profile 2" 7 "Guest" 8 "RESERVED" 9 "RESERVED" 10 "RESERVED" 11 "RESERVED" 12 "RESERVED" 13 "RESERVED" 14 "RESERVED" 15 "Error Indicator" ;
VAL_ 758 ECMMRR_PLUS 0 "0x0x0~0x7D:0~1.25 V" 125 "0x0x0~0x7D:0~1.25 V" 126 "0x7E~0xFE:RESERVED" 254 "0x7E~0xFE:RESERVED" 255 "RESERVED" ;
VAL_ 758 SBCM_DRV_DiagSta 0 "Default" 1 "Normal Operation" 2 "DRV Indicator Circuit Failure" 3 "RESERVED" ;
VAL_ 763 SBCM_DRV_Crc3Val 0 "0x0x0~0xFF:CRCValue" 255 "0x0x0~0xFF:CRCValue" ;
VAL_ 763 CDM_TypeOption 0 "Off" 1 "On" 2 "On_2EA" 3 "Error Indicator" ;
VAL_ 763 SBCM_DRV_AlvCnt3Val 0 "AlvCntValue" 1 "AlvCntValue" 2 "AlvCntValue" 3 "AlvCntValue" 4 "AlvCntValue" 5 "AlvCntValue" 6 "AlvCntValue" 7 "AlvCntValue" 8 "AlvCntValue" 9 "AlvCntValue" 10 "AlvCntValue" 11 "AlvCntValue" 12 "AlvCntValue" 13 "AlvCntValue" 14 "AlvCntValue" 15 "AlvCntValue" ;
VAL_ 763 CDM_ImmeChgSw_SBCM 0 "Default" 1 "Off" 2 "On" 3 "RESERVED" ;
VAL_ 763 CDM_ChgDrSwFrt_SBCM 0 "Default" 1 "Close" 2 "Open" 3 "RESERVED" ;
VAL_ 763 CDM_OpnClsState_SBCM 0 "Default" 1 "Open" 2 "Close" 3 "RESERVED" ;
VAL_ 763 CDM_WarnMsg_SBCM 0 "Default" 1 "Normal" 2 "ChargeDoorErrorState" 3 "RESERVED" ;
VAL_ 763 CDM_AutoWashModeSta 0 "Default" 1 "CDM Auto Wash Mode Off (Ready)" 2 "CDM Auto Wash Mode Off (Error)" 3 "CDM Auto Wash Mode On" 4 "RESERVED" 5 "RESERVED" 6 "RESERVED" 7 "Invalid" ;
VAL_ 763 CDM_CmdStatus_SBCM 0 "Open (AVN)" 1 "Open (SMK)" 2 "Open (Sensor Switch)" 3 "Open (Command Hard Switch)" 4 "Open (Anti - Pinch)" 5 "Close (AVN)" 6 "Close (SMK)" 7 "Close (Assist Mode)" 8 "Close (Command Hard Switch)" 9 "Close (Connector)" 10 "Close (Gear Position)" 11 "Close (Time Over)" 12 "Close (Anti - Pinch)" 13 "Close (Sensor Switch)" 14 "Stall (Stop)" 15 "Invalid" ;
VAL_ 763 CDM_OutsideOpnSwSta 0 "Default" 1 "Push" 2 "RESERVED" 3 "Invalid" ;
VAL_ 763 PwrDRBuzzerOut_DRV 0 "OFF" 1 "Open" 2 "Close" 3 "Warning" ;
VAL_ 763 Warn_HoodSwSta_SBCM 0 "Off" 1 "On" 2 "RESERVED" 3 "Error Indicator" ;
VAL_ 763 Hood_TypeOption 0 "Off (Mechanical hood latch is applied)" 1 "On (E-Hood latch is applied)" 2 "RESERVED" 3 "Error Indicator" ;
VAL_ 763 SBCM_FrunkSta 0 "Default" 1 "Valid" 2 "RESERVED" 3 "Error Indicator" ;
VAL_ 763 Warn_HoodSwFullSta_SBCM 0 "Off" 1 "On" 2 "RESERVED" 3 "Error Indicator" ;
VAL_ 763 FrunkWarning_SBCM 0 "Off" 1 "On" 2 "RESERVED" 3 "Error Indicator" ;
VAL_ 763 SBCM_Longkey_DRVDrAtClsSwSta 0 "Default" 1 "Off" 2 "On" 3 "Error Indicator" ;
VAL_ 763 PwrDRClosingDRVDrSta 0 "Default" 1 "Close" 2 "Open" 3 "Stop" 4 "RESERVED" 5 "RESERVED" 6 "RESERVED" 7 "Invalid" ;
VAL_ 763 Drv_DrLkRetryFail_SBCM 0 "Normal" 1 "Fail" 2 "RESERVED" 3 "RESERVED" ;
VAL_ 763 CDM_GbtImmeChgSw_SBCM 0 "Default" 1 "Off" 2 "On" 3 "RESERVED" ;
VAL_ 763 CDM_GbtOpnClsState_SBCM 0 "Default" 1 "Open" 2 "Close" 3 "RESERVED" ;
VAL_ 763 CDM_GbtWarnMsg_SBCM 0 "Default" 1 "Normal" 2 "ChargeDoorErrorState" 3 "RESERVED" ;
VAL_ 763 DoorLock_DrvLkOutSta_SBCM 0 "Off" 1 "On" 2 "Not Used" 3 "Error Indicator" ;
VAL_ 763 CDM_InsideOpnSwSta 0 "Off" 1 "On" 2 "RESERVED" 3 "Error Indicator" ;
VAL_ 742 SGU_FltSta 0 "Normal" 1 "Fault" 2 "Not Used" 3 "Error Indicator" ;
VAL_ 742 SGU_BlindOnOffSet 0 "USM Activation" 1 "Off" 2 "On" 3 "Invalid" ;
VAL_ 742 SGU_BlindOpenReq 0 "Default" 1 "BlindOpen" 2 "Reserved" 3 "Invalid" ;
VAL_ 742 SGU_Roof_OprLv 0 "Default" 1 "OFF" 2 "Level 1" 3 "Level 2" 4 "Level 3" 5 "Reserved" 6 "Reserved" 7 "Invalid" ;
VAL_ 742 SGU_2ndLeftDoor_OprLv 0 "Default" 1 "Off" 2 "Level 1" 3 "Level 2" 4 "Level 3" 5 "Reserved" 6 "Reserved" 7 "Invalid" ;
VAL_ 742 SGU_2ndRightDoor_OprLv 0 "Default" 1 "Off" 2 "Level 1" 3 "Level 2" 4 "Level 3" 5 "Reserved" 6 "Reserved" 7 "Invalid" ;
VAL_ 742 SGU_3rdLeftDoor_OprLv 0 "Default" 1 "Off" 2 "Level 1" 3 "Level 2" 4 "Level 3" 5 "Reserved" 6 "Reserved" 7 "Invalid" ;
VAL_ 742 SGU_3rdRightDoor_OprLv 0 "Default" 1 "Off" 2 "Level 1" 3 "Level 2" 4 "Level 3" 5 "Reserved" 6 "Reserved" 7 "Invalid" ;
VAL_ 742 SGU_RearWindow_OprLv 0 "Default" 1 "Off" 2 "Level 1" 3 "Level 2" 4 "Level 3" 5 "Reserved" 6 "Reserved" 7 "Invalid" ;
VAL_ 742 SGU_OprLvVehicleSet 0 "Default" 1 "Reserved" 2 "Off & Level 1" 3 "Off & Level 1 ~ 2" 4 "Off & Level 1 ~ 3" 5 "Off & Level 1 ~ 4" 6 "Off & Level 1 ~ 5" 7 "Invalid" ;
VAL_ 742 SGU_RdySta 0 "Off" 1 "Ready" 2 "Sleep" 3 "Reserved" ;
